VERSION ""

NS_ :

BS_:

BU_: ETH

BO_ 1520 USM_alertLog: 8 Vector__XXX
 SG_ USM_alertID M : 0|8@1+ (1,0) [0|0] "" Vector__XXX
 SG_ USM_alertState : 15|1@1+ (1,0) [0|0] "" Vector__XXX
 SG_ USM_a000_alertDataW0 m0 : 16|16@1+ (1,0) [0|0] "" Vector__XXX
 SG_ USM_a001_InternalWatchdog m1 : 16|1@1+ (1,0) [0|0] "" Vector__XXX
 SG_ USM_a002_CPUUndervoltage m2 : 16|1@1+ (1,0) [0|0] "" Vector__XXX
 SG_ USM_a003_AssertID m3 : 16|16@1+ (1,0) [0|0] "" Vector__XXX
 SG_ USM_a005_busID0 m5 : 16|4@1+ (1,0) [0|0] "" Vector__XXX
 SG_ USM_a006_busID m6 : 16|4@1+ (1,0) [0|0] "" Vector__XXX
 SG_ USM_a012_ClockError m12 : 16|1@1+ (1,0) [0|0] "" Vector__XXX
 SG_ USM_a013_LogQueueFull m13 : 16|1@1+ (1,0) [0|0] "" Vector__XXX
 SG_ USM_a015_NVMMMemOverflow m15 : 16|1@1+ (1,0) [0|0] "" Vector__XXX
 SG_ USM_a016_NVMMRecordID m16 : 16|16@1+ (1,0) [0|0] "" Vector__XXX
 SG_ USM_a021_Task1msLate m21 : 16|1@1+ (1,0) [0|0] "" Vector__XXX
 SG_ USM_a022_TaskInitErrorCount m22 : 16|8@1+ (1,0) [0|0] "" Vector__XXX
 SG_ USM_a030_logId m30 : 16|4@1+ (1,0) [0|0] "" Vector__XXX
 SG_ USM_a031_uds_bytes_0 m31 : 16|8@1+ (1,0) [0|0] "" Vector__XXX
 SG_ USM_a041_CPULoadTotal m41 : 16|8@1+ (1,0) [0|0] "" Vector__XXX
 SG_ USM_a042_Usage1msTask m42 : 16|8@1+ (1,0) [0|0] "" Vector__XXX
 SG_ USM_a043_CallTrace0 m43 : 16|24@1+ (1,0) [0|0] "" Vector__XXX
 SG_ USM_a044_CallTrace0 m44 : 16|24@1+ (1,0) [0|0] "" Vector__XXX
 SG_ USM_a045_CallTrace0 m45 : 16|24@1+ (1,0) [0|0] "" Vector__XXX
 SG_ USM_a046_CallTrace0 m46 : 16|24@1+ (1,0) [0|0] "" Vector__XXX
 SG_ USM_a057_VEH_cpControl m57 : 16|1@1+ (1,0) [0|0] "" Vector__XXX
 SG_ USM_a058_voltageDrop m58 : 16|12@1+ (0.005443676098,0) [0|0] "" Vector__XXX
 SG_ USM_a059_voltageDrop m59 : 16|12@1+ (0.005443676098,0) [0|0] "" Vector__XXX
 SG_ USM_a060_lockoutDisabled m60 : 16|1@1+ (1,0) [0|0] "" Vector__XXX
 SG_ USM_a063_switchChannel m63 : 16|8@1+ (1,0) [0|0] "" Vector__XXX
 SG_ USM_a064_busBitField m64 : 16|8@1+ (1,0) [0|0] "" Vector__XXX
 SG_ USM_a082_RIPC_epbPrivateState m82 : 16|1@1+ (1,0) [0|0] "" Vector__XXX
 SG_ USM_a083_LIPC_epbPrivateState m83 : 16|1@1+ (1,0) [0|0] "" Vector__XXX
 SG_ USM_a084_CH_StatusC m84 : 16|1@1+ (1,0) [0|0] "" Vector__XXX
 SG_ USM_a085_PARTY_buttonStatus m85 : 16|1@1+ (1,0) [0|0] "" Vector__XXX
 SG_ USM_a086_VEH_LVBMS_statusHigh m86 : 16|1@1+ (1,0) [0|0] "" Vector__XXX
 SG_ USM_a087_VEH_temperature m87 : 16|1@1+ (1,0) [0|0] "" Vector__XXX
 SG_ USM_a088_VEH_temperature m88 : 16|1@1+ (1,0) [0|0] "" Vector__XXX
 SG_ USM_a089_PARTY_party1 m89 : 16|1@1+ (1,0) [0|0] "" Vector__XXX
 SG_ USM_a090_VEH_chNm m90 : 16|1@1+ (1,0) [0|0] "" Vector__XXX
 SG_ USM_a091_VEH_faultsAndExtras m91 : 16|1@1+ (1,0) [0|0] "" Vector__XXX
 SG_ USM_a092_VEH_restraintStatus m92 : 16|1@1+ (1,0) [0|0] "" Vector__XXX
 SG_ USM_a093_VEH_restraintStatus m93 : 16|1@1+ (1,0) [0|0] "" Vector__XXX
 SG_ USM_a094_VEH_sysStatus m94 : 16|1@1+ (1,0) [0|0] "" Vector__XXX
 SG_ USM_a095_PT_ptNm m95 : 16|1@1+ (1,0) [0|0] "" Vector__XXX
 SG_ USM_a096_VEH_status m96 : 16|1@1+ (1,0) [0|0] "" Vector__XXX
 SG_ USM_a097_VEH_HVStatus m97 : 16|1@1+ (1,0) [0|0] "" Vector__XXX
 SG_ USM_a098_CH_torque m98 : 16|1@1+ (1,0) [0|0] "" Vector__XXX
 SG_ USM_a099_VEH_oocStatus m99 : 16|1@1+ (1,0) [0|0] "" Vector__XXX
 SG_ USM_a100_VEH m100 : 16|1@1+ (1,0) [0|0] "" Vector__XXX
 SG_ USM_a101_VEH_state m101 : 16|1@1+ (1,0) [0|0] "" Vector__XXX
 SG_ USM_a102_VEH_faultsAndExtras m102 : 16|1@1+ (1,0) [0|0] "" Vector__XXX
 SG_ USM_a103_VEH_hvsNm m103 : 16|1@1+ (1,0) [0|0] "" Vector__XXX
 SG_ USM_a104_VEH_chNm m104 : 16|1@1+ (1,0) [0|0] "" Vector__XXX
 SG_ USM_a105_VEH_states m105 : 16|1@1+ (1,0) [0|0] "" Vector__XXX
 SG_ USM_a106_VEH_dcdcStatus m106 : 16|1@1+ (1,0) [0|0] "" Vector__XXX
 SG_ USM_a107_VEH_hvsNm m107 : 16|1@1+ (1,0) [0|0] "" Vector__XXX
 SG_ USM_a108_VEH_hvStatus m108 : 16|1@1+ (1,0) [0|0] "" Vector__XXX
 SG_ USM_a109_PARTY_status m109 : 16|1@1+ (1,0) [0|0] "" Vector__XXX
 SG_ USM_a110_VEH_carState m110 : 16|1@1+ (1,0) [0|0] "" Vector__XXX
 SG_ USM_a111_VEH_internalStatus m111 : 16|1@1+ (1,0) [0|0] "" Vector__XXX
 SG_ USM_a112_VEH_internalStatus m112 : 16|1@1+ (1,0) [0|0] "" Vector__XXX
 SG_ USM_a113_VEH_ethNm m113 : 16|1@1+ (1,0) [0|0] "" Vector__XXX
 SG_ USM_a114_PARTY_status m114 : 16|1@1+ (1,0) [0|0] "" Vector__XXX
 SG_ USM_a115_VEH_vehNm m115 : 16|1@1+ (1,0) [0|0] "" Vector__XXX
 SG_ USM_a116_PARTY_epbmStatus m116 : 16|1@1+ (1,0) [0|0] "" Vector__XXX
 SG_ USM_a117_BDY_epbmStatus m117 : 16|1@1+ (1,0) [0|0] "" Vector__XXX
 SG_ USM_a118_VEH_vehNm m118 : 16|1@1+ (1,0) [0|0] "" Vector__XXX
 SG_ USM_a119_VEH_steerAngle m119 : 16|1@1+ (1,0) [0|0] "" Vector__XXX
 SG_ USM_a120_PARTY_chassisCntl m120 : 16|1@1+ (1,0) [0|0] "" Vector__XXX
 SG_ USM_a131_inDrivePowerState m131 : 16|1@1+ (1,0) [0|0] "" Vector__XXX
 SG_ USM_a132_inDrivePowerState m132 : 16|1@1+ (1,0) [0|0] "" Vector__XXX
 SG_ USM_a133_inDrivePowerState m133 : 16|1@1+ (1,0) [0|0] "" Vector__XXX
 SG_ USM_a134_inDrivePowerState m134 : 16|1@1+ (1,0) [0|0] "" Vector__XXX
 SG_ USM_a135_inDrivePowerState m135 : 16|1@1+ (1,0) [0|0] "" Vector__XXX
 SG_ USM_a136_inDrivePowerState m136 : 16|1@1+ (1,0) [0|0] "" Vector__XXX
 SG_ USM_a137_inDrivePowerState m137 : 16|1@1+ (1,0) [0|0] "" Vector__XXX
 SG_ USM_a138_inDrivePowerState m138 : 16|1@1+ (1,0) [0|0] "" Vector__XXX
 SG_ USM_a139_inDrivePowerState m139 : 16|1@1+ (1,0) [0|0] "" Vector__XXX
 SG_ USM_a140_inDrivePowerState m140 : 16|1@1+ (1,0) [0|0] "" Vector__XXX
 SG_ USM_a141_inDrivePowerState m141 : 16|1@1+ (1,0) [0|0] "" Vector__XXX
 SG_ USM_a142_inDrivePowerState m142 : 16|1@1+ (1,0) [0|0] "" Vector__XXX
 SG_ USM_a143_inDrivePowerState m143 : 16|1@1+ (1,0) [0|0] "" Vector__XXX
 SG_ USM_a144_inDrivePowerState m144 : 16|1@1+ (1,0) [0|0] "" Vector__XXX
 SG_ USM_a145_inDrivePowerState m145 : 16|1@1+ (1,0) [0|0] "" Vector__XXX
 SG_ USM_a146_inDrivePowerState m146 : 16|1@1+ (1,0) [0|0] "" Vector__XXX
 SG_ USM_a147_inDrivePowerState m147 : 16|1@1+ (1,0) [0|0] "" Vector__XXX
 SG_ USM_a148_inDrivePowerState m148 : 16|1@1+ (1,0) [0|0] "" Vector__XXX
 SG_ USM_a149_inDrivePowerState m149 : 16|1@1+ (1,0) [0|0] "" Vector__XXX
 SG_ USM_a150_inDrivePowerState m150 : 16|1@1+ (1,0) [0|0] "" Vector__XXX
 SG_ USM_a151_inDrivePowerState m151 : 16|1@1+ (1,0) [0|0] "" Vector__XXX
 SG_ USM_a152_inDrivePowerState m152 : 16|1@1+ (1,0) [0|0] "" Vector__XXX
 SG_ USM_a153_inDrivePowerState m153 : 16|1@1+ (1,0) [0|0] "" Vector__XXX
 SG_ USM_a154_inDrivePowerState m154 : 16|1@1+ (1,0) [0|0] "" Vector__XXX
 SG_ USM_a155_temperature m155 : 16|8@1- (1,33) [0|0] "" Vector__XXX
 SG_ USM_a156_temperature m156 : 16|8@1- (1,33) [0|0] "" Vector__XXX
 SG_ USM_a157_temperature m157 : 16|8@1- (1,33) [0|0] "" Vector__XXX
 SG_ USM_a158_temperature m158 : 16|8@1- (1,33) [0|0] "" Vector__XXX
 SG_ USM_a159_temperature m159 : 16|8@1- (1,33) [0|0] "" Vector__XXX
 SG_ USM_a160_temperature m160 : 16|8@1- (1,33) [0|0] "" Vector__XXX
 SG_ USM_a161_temperature m161 : 16|8@1- (1,33) [0|0] "" Vector__XXX
 SG_ USM_a162_temperature m162 : 16|8@1- (1,33) [0|0] "" Vector__XXX
 SG_ USM_a163_temperature m163 : 16|8@1- (1,33) [0|0] "" Vector__XXX
 SG_ USM_a164_temperature m164 : 16|8@1- (1,33) [0|0] "" Vector__XXX
 SG_ USM_a165_temperature m165 : 16|8@1- (1,33) [0|0] "" Vector__XXX
 SG_ USM_a166_temperature m166 : 16|8@1- (1,33) [0|0] "" Vector__XXX
 SG_ USM_a177_rtmCompensated m177 : 16|8@1+ (8,0) [0|0] "" Vector__XXX
 SG_ USM_a178_rtmCompensated m178 : 16|8@1+ (8,0) [0|0] "" Vector__XXX
 SG_ USM_a179_rtmCompensated m179 : 16|8@1+ (8,0) [0|0] "" Vector__XXX
 SG_ USM_a180_rtmCompensated m180 : 16|8@1+ (8,0) [0|0] "" Vector__XXX
 SG_ USM_a181_rtmCompensated m181 : 16|8@1+ (8,0) [0|0] "" Vector__XXX
 SG_ USM_a182_rtmCompensated m182 : 16|8@1+ (8,0) [0|0] "" Vector__XXX
 SG_ USM_a183_rtmCompensated m183 : 16|8@1+ (8,0) [0|0] "" Vector__XXX
 SG_ USM_a184_rtmCompensated m184 : 16|8@1+ (8,0) [0|0] "" Vector__XXX
 SG_ USM_a185_rtmCompensated m185 : 16|8@1+ (8,0) [0|0] "" Vector__XXX
 SG_ USM_a186_rtmCompensated m186 : 16|8@1+ (8,0) [0|0] "" Vector__XXX
 SG_ USM_a187_rtmCompensated m187 : 16|8@1+ (8,0) [0|0] "" Vector__XXX
 SG_ USM_a188_rtmCompensated m188 : 16|8@1+ (8,0) [0|0] "" Vector__XXX
 SG_ USM_a201_channel m201 : 16|2@1+ (1,0) [0|0] "" Vector__XXX
 SG_ USM_a202_channel m202 : 16|4@1+ (1,0) [0|0] "" Vector__XXX
 SG_ USM_a203_sdiRawDistData m203 : 16|9@1+ (1,0) [0|0] "" Vector__XXX
 SG_ USM_a204_sdiRawDistData m204 : 16|9@1+ (1,0) [0|0] "" Vector__XXX
 SG_ USM_a205_sdiRawDistData m205 : 16|9@1+ (1,0) [0|0] "" Vector__XXX
 SG_ USM_a206_sdiRawDistData m206 : 16|9@1+ (1,0) [0|0] "" Vector__XXX
 SG_ USM_a207_sdiRawDistData m207 : 16|9@1+ (1,0) [0|0] "" Vector__XXX
 SG_ USM_a208_sdiRawDistData m208 : 16|9@1+ (1,0) [0|0] "" Vector__XXX
 SG_ USM_a209_sdiRawDistData m209 : 16|9@1+ (1,0) [0|0] "" Vector__XXX
 SG_ USM_a210_sdiRawDistData m210 : 16|9@1+ (1,0) [0|0] "" Vector__XXX
 SG_ USM_a211_sdiRawDistData m211 : 16|9@1+ (1,0) [0|0] "" Vector__XXX
 SG_ USM_a212_sdiRawDistData m212 : 16|9@1+ (1,0) [0|0] "" Vector__XXX
 SG_ USM_a213_sdiRawDistData m213 : 16|9@1+ (1,0) [0|0] "" Vector__XXX
 SG_ USM_a214_sdiRawDistData m214 : 16|9@1+ (1,0) [0|0] "" Vector__XXX
 SG_ USM_a227_reset m227 : 16|1@1+ (1,0) [0|0] "" Vector__XXX
 SG_ USM_a228_reset m228 : 16|1@1+ (1,0) [0|0] "" Vector__XXX
 SG_ USM_a229_reset m229 : 16|1@1+ (1,0) [0|0] "" Vector__XXX
 SG_ USM_a230_reset m230 : 16|1@1+ (1,0) [0|0] "" Vector__XXX
 SG_ USM_a231_reset m231 : 16|1@1+ (1,0) [0|0] "" Vector__XXX
 SG_ USM_a232_reset m232 : 16|1@1+ (1,0) [0|0] "" Vector__XXX
 SG_ USM_a233_reset m233 : 16|1@1+ (1,0) [0|0] "" Vector__XXX
 SG_ USM_a234_reset m234 : 16|1@1+ (1,0) [0|0] "" Vector__XXX
 SG_ USM_a235_reset m235 : 16|1@1+ (1,0) [0|0] "" Vector__XXX
 SG_ USM_a236_reset m236 : 16|1@1+ (1,0) [0|0] "" Vector__XXX
 SG_ USM_a237_reset m237 : 16|1@1+ (1,0) [0|0] "" Vector__XXX
 SG_ USM_a238_reset m238 : 16|1@1+ (1,0) [0|0] "" Vector__XXX
 SG_ USM_a240_reset m240 : 16|1@1+ (1,0) [0|0] "" Vector__XXX
 SG_ USM_a241_reset m241 : 16|1@1+ (1,0) [0|0] "" Vector__XXX
 SG_ USM_a242_reset m242 : 16|1@1+ (1,0) [0|0] "" Vector__XXX
 SG_ USM_a243_reset m243 : 16|1@1+ (1,0) [0|0] "" Vector__XXX
 SG_ USM_a244_reset m244 : 16|1@1+ (1,0) [0|0] "" Vector__XXX
 SG_ USM_a245_reset m245 : 16|1@1+ (1,0) [0|0] "" Vector__XXX
 SG_ USM_a246_reset m246 : 16|1@1+ (1,0) [0|0] "" Vector__XXX
 SG_ USM_a247_reset m247 : 16|1@1+ (1,0) [0|0] "" Vector__XXX
 SG_ USM_a248_reset m248 : 16|1@1+ (1,0) [0|0] "" Vector__XXX
 SG_ USM_a249_reset m249 : 16|1@1+ (1,0) [0|0] "" Vector__XXX
 SG_ USM_a250_reset m250 : 16|1@1+ (1,0) [0|0] "" Vector__XXX
 SG_ USM_a251_reset m251 : 16|1@1+ (1,0) [0|0] "" Vector__XXX
 SG_ USM_a252_inDrivePowerState m252 : 16|1@1+ (1,0) [0|0] "" Vector__XXX
 SG_ USM_a253_inDrivePowerState m253 : 16|1@1+ (1,0) [0|0] "" Vector__XXX
 SG_ USM_a254_frontSensorsCurrent m254 : 16|10@1+ (0.005865102639296188,0) [0|0] "" Vector__XXX
 SG_ USM_a255_rearSensorsCurrent m255 : 16|10@1+ (0.005865102639296188,0) [0|0] "" Vector__XXX
 SG_ USM_a002_PowerOnReset m2 : 17|1@1+ (1,0) [0|0] "" Vector__XXX
 SG_ USM_a012_FlashError m12 : 17|1@1+ (1,0) [0|0] "" Vector__XXX
 SG_ USM_a013_ClearQueueFull m13 : 17|1@1+ (1,0) [0|0] "" Vector__XXX
 SG_ USM_a015_NVMMFilesystemError m15 : 17|1@1+ (1,0) [0|0] "" Vector__XXX
 SG_ USM_a021_Task1msStarved m21 : 17|1@1+ (1,0) [0|0] "" Vector__XXX
 SG_ USM_a060_resetUnlocked m60 : 17|1@1+ (1,0) [0|0] "" Vector__XXX
 SG_ USM_a082_RIPC_remoteHSD m82 : 17|1@1+ (1,0) [0|0] "" Vector__XXX
 SG_ USM_a083_LIPC_remoteHSD m83 : 17|1@1+ (1,0) [0|0] "" Vector__XXX
 SG_ USM_a086_VEH_LVBMS_statusLow m86 : 17|1@1+ (1,0) [0|0] "" Vector__XXX
 SG_ USM_a087_VEH_thermalControl m87 : 17|1@1+ (1,0) [0|0] "" Vector__XXX
 SG_ USM_a088_VEH_thermalControl m88 : 17|1@1+ (1,0) [0|0] "" Vector__XXX
 SG_ USM_a089_PARTY_status m89 : 17|1@1+ (1,0) [0|0] "" Vector__XXX
 SG_ USM_a090_VEH_state m90 : 17|1@1+ (1,0) [0|0] "" Vector__XXX
 SG_ USM_a091_VEH_info m91 : 17|1@1+ (1,0) [0|0] "" Vector__XXX
 SG_ USM_a092_VEH_switchStatus m92 : 17|1@1+ (1,0) [0|0] "" Vector__XXX
 SG_ USM_a093_VEH_switchStatus m93 : 17|1@1+ (1,0) [0|0] "" Vector__XXX
 SG_ USM_a094_PARTY_sysStatus m94 : 17|1@1+ (1,0) [0|0] "" Vector__XXX
 SG_ USM_a095_PT_status m95 : 17|1@1+ (1,0) [0|0] "" Vector__XXX
 SG_ USM_a096_CH_status m96 : 17|1@1+ (1,0) [0|0] "" Vector__XXX
 SG_ USM_a097_VEH_state m97 : 17|1@1+ (1,0) [0|0] "" Vector__XXX
 SG_ USM_a098_VEH_hvStatus m98 : 17|1@1+ (1,0) [0|0] "" Vector__XXX
 SG_ USM_a100_PARTY m100 : 17|1@1+ (1,0) [0|0] "" Vector__XXX
 SG_ USM_a101_PARTY_locState m101 : 17|1@1+ (1,0) [0|0] "" Vector__XXX
 SG_ USM_a102_VEH_feedbackStatus m102 : 17|1@1+ (1,0) [0|0] "" Vector__XXX
 SG_ USM_a103_VEH_vehNm m103 : 17|1@1+ (1,0) [0|0] "" Vector__XXX
 SG_ USM_a104_VEH_bodyControls m104 : 17|1@1+ (1,0) [0|0] "" Vector__XXX
 SG_ USM_a105_VEH_chNm m105 : 17|1@1+ (1,0) [0|0] "" Vector__XXX
 SG_ USM_a106_VEH_thermalControl m106 : 17|1@1+ (1,0) [0|0] "" Vector__XXX
 SG_ USM_a107_VEH_vehNm m107 : 17|1@1+ (1,0) [0|0] "" Vector__XXX
 SG_ USM_a108_VEH_temperature m108 : 17|1@1+ (1,0) [0|0] "" Vector__XXX
 SG_ USM_a109_PARTY_inertial2 m109 : 17|1@1+ (1,0) [0|0] "" Vector__XXX
 SG_ USM_a110_VEH_carConfig m110 : 17|1@1+ (1,0) [0|0] "" Vector__XXX
 SG_ USM_a111_VEH_status m111 : 17|1@1+ (1,0) [0|0] "" Vector__XXX
 SG_ USM_a112_VEH_status m112 : 17|1@1+ (1,0) [0|0] "" Vector__XXX
 SG_ USM_a113_VEH_hvacRequest m113 : 17|1@1+ (1,0) [0|0] "" Vector__XXX
 SG_ USM_a114_PARTY_wheelSpeeds m114 : 17|1@1+ (1,0) [0|0] "" Vector__XXX
 SG_ USM_a115_VEH_authentication m115 : 17|1@1+ (1,0) [0|0] "" Vector__XXX
 SG_ USM_a116_VEH_vehNm m116 : 17|1@1+ (1,0) [0|0] "" Vector__XXX
 SG_ USM_a117_BDY_restraintStatus m117 : 17|1@1+ (1,0) [0|0] "" Vector__XXX
 SG_ USM_a118_VEH_lighting m118 : 17|1@1+ (1,0) [0|0] "" Vector__XXX
 SG_ USM_a119_VEH_leftStalk m119 : 17|1@1+ (1,0) [0|0] "" Vector__XXX
 SG_ USM_a120_VEH_systemStatus m120 : 17|1@1+ (1,0) [0|0] "" Vector__XXX
 SG_ USM_a227_otpCrcError m227 : 17|1@1+ (1,0) [0|0] "" Vector__XXX
 SG_ USM_a228_otpCrcError m228 : 17|1@1+ (1,0) [0|0] "" Vector__XXX
 SG_ USM_a229_otpCrcError m229 : 17|1@1+ (1,0) [0|0] "" Vector__XXX
 SG_ USM_a230_otpCrcError m230 : 17|1@1+ (1,0) [0|0] "" Vector__XXX
 SG_ USM_a231_otpCrcError m231 : 17|1@1+ (1,0) [0|0] "" Vector__XXX
 SG_ USM_a232_otpCrcError m232 : 17|1@1+ (1,0) [0|0] "" Vector__XXX
 SG_ USM_a233_otpCrcError m233 : 17|1@1+ (1,0) [0|0] "" Vector__XXX
 SG_ USM_a234_otpCrcError m234 : 17|1@1+ (1,0) [0|0] "" Vector__XXX
 SG_ USM_a235_otpCrcError m235 : 17|1@1+ (1,0) [0|0] "" Vector__XXX
 SG_ USM_a236_otpCrcError m236 : 17|1@1+ (1,0) [0|0] "" Vector__XXX
 SG_ USM_a237_otpCrcError m237 : 17|1@1+ (1,0) [0|0] "" Vector__XXX
 SG_ USM_a238_otpCrcError m238 : 17|1@1+ (1,0) [0|0] "" Vector__XXX
 SG_ USM_a240_otpCrcError m240 : 17|1@1+ (1,0) [0|0] "" Vector__XXX
 SG_ USM_a241_otpCrcError m241 : 17|1@1+ (1,0) [0|0] "" Vector__XXX
 SG_ USM_a242_otpCrcError m242 : 17|1@1+ (1,0) [0|0] "" Vector__XXX
 SG_ USM_a243_otpCrcError m243 : 17|1@1+ (1,0) [0|0] "" Vector__XXX
 SG_ USM_a244_otpCrcError m244 : 17|1@1+ (1,0) [0|0] "" Vector__XXX
 SG_ USM_a245_otpCrcError m245 : 17|1@1+ (1,0) [0|0] "" Vector__XXX
 SG_ USM_a246_otpCrcError m246 : 17|1@1+ (1,0) [0|0] "" Vector__XXX
 SG_ USM_a247_otpCrcError m247 : 17|1@1+ (1,0) [0|0] "" Vector__XXX
 SG_ USM_a248_otpCrcError m248 : 17|1@1+ (1,0) [0|0] "" Vector__XXX
 SG_ USM_a249_otpCrcError m249 : 17|1@1+ (1,0) [0|0] "" Vector__XXX
 SG_ USM_a250_otpCrcError m250 : 17|1@1+ (1,0) [0|0] "" Vector__XXX
 SG_ USM_a251_otpCrcError m251 : 17|1@1+ (1,0) [0|0] "" Vector__XXX
 SG_ USM_a012_SoftwareReset m12 : 18|1@1+ (1,0) [0|0] "" Vector__XXX
 SG_ USM_a015_NVMMRecordIDError m15 : 18|1@1+ (1,0) [0|0] "" Vector__XXX
 SG_ USM_a021_Task1msMissed m21 : 18|1@1+ (1,0) [0|0] "" Vector__XXX
 SG_ USM_a082_RIPC_railStatus m82 : 18|1@1+ (1,0) [0|0] "" Vector__XXX
 SG_ USM_a083_LIPC_railStatus m83 : 18|1@1+ (1,0) [0|0] "" Vector__XXX
 SG_ USM_a086_VEH_status m86 : 18|1@1+ (1,0) [0|0] "" Vector__XXX
 SG_ USM_a087_VEH_torque m87 : 18|1@1+ (1,0) [0|0] "" Vector__XXX
 SG_ USM_a088_VEH_torque m88 : 18|1@1+ (1,0) [0|0] "" Vector__XXX
 SG_ USM_a089_VEH_status m89 : 18|1@1+ (1,0) [0|0] "" Vector__XXX
 SG_ USM_a090_PARTY_eacMonitor m90 : 18|1@1+ (1,0) [0|0] "" Vector__XXX
 SG_ USM_a091_VEH_state m91 : 18|1@1+ (1,0) [0|0] "" Vector__XXX
 SG_ USM_a092_VEH_seatStatus2 m92 : 18|1@1+ (1,0) [0|0] "" Vector__XXX
 SG_ USM_a093_VEH_seatStatus2 m93 : 18|1@1+ (1,0) [0|0] "" Vector__XXX
 SG_ USM_a098_VEH_status m98 : 18|1@1+ (1,0) [0|0] "" Vector__XXX
 SG_ USM_a100_PT m100 : 18|1@1+ (1,0) [0|0] "" Vector__XXX
 SG_ USM_a101_LIPC_externalWatchdogHeartBeat m101 : 18|1@1+ (1,0) [0|0] "" Vector__XXX
 SG_ USM_a102_VEH_sensorStatus m102 : 18|1@1+ (1,0) [0|0] "" Vector__XXX
 SG_ USM_a103_VEH_status m103 : 18|1@1+ (1,0) [0|0] "" Vector__XXX
 SG_ USM_a104_VEH_bodyControls3 m104 : 18|1@1+ (1,0) [0|0] "" Vector__XXX
 SG_ USM_a105_VEH_dampingStates m105 : 18|1@1+ (1,0) [0|0] "" Vector__XXX
 SG_ USM_a106_VEH_dcdcRailStatus m106 : 18|1@1+ (1,0) [0|0] "" Vector__XXX
 SG_ USM_a107_VEH_status m107 : 18|1@1+ (1,0) [0|0] "" Vector__XXX
 SG_ USM_a108_VEH_thermalControl m108 : 18|1@1+ (1,0) [0|0] "" Vector__XXX
 SG_ USM_a109_PARTY_nearDeploy m109 : 18|1@1+ (1,0) [0|0] "" Vector__XXX
 SG_ USM_a110_VEH_time m110 : 18|1@1+ (1,0) [0|0] "" Vector__XXX
 SG_ USM_a111_VEH_vehNm m111 : 18|1@1+ (1,0) [0|0] "" Vector__XXX
 SG_ USM_a112_VEH_vehNm m112 : 18|1@1+ (1,0) [0|0] "" Vector__XXX
 SG_ USM_a113_VEH_chargeRequest m113 : 18|1@1+ (1,0) [0|0] "" Vector__XXX
 SG_ USM_a114_VEH_wheelSpeeds m114 : 18|1@1+ (1,0) [0|0] "" Vector__XXX
 SG_ USM_a115_VEH_BLEResetRequest m115 : 18|1@1+ (1,0) [0|0] "" Vector__XXX
 SG_ USM_a116_VEH_hvacRequest m116 : 18|1@1+ (1,0) [0|0] "" Vector__XXX
 SG_ USM_a117_VEH_prndStatus m117 : 18|1@1+ (1,0) [0|0] "" Vector__XXX
 SG_ USM_a118_VEH_sensors m118 : 18|1@1+ (1,0) [0|0] "" Vector__XXX
 SG_ USM_a119_VEH_rightStalk m119 : 18|1@1+ (1,0) [0|0] "" Vector__XXX
 SG_ USM_a120_CH_chassisCntl m120 : 18|1@1+ (1,0) [0|0] "" Vector__XXX
 SG_ USM_a201_OT m201 : 18|1@1+ (1,0) [0|0] "" Vector__XXX
 SG_ USM_a227_trimRegParityErr m227 : 18|1@1+ (1,0) [0|0] "" Vector__XXX
 SG_ USM_a228_trimRegParityErr m228 : 18|1@1+ (1,0) [0|0] "" Vector__XXX
 SG_ USM_a229_trimRegParityErr m229 : 18|1@1+ (1,0) [0|0] "" Vector__XXX
 SG_ USM_a230_trimRegParityErr m230 : 18|1@1+ (1,0) [0|0] "" Vector__XXX
 SG_ USM_a231_trimRegParityErr m231 : 18|1@1+ (1,0) [0|0] "" Vector__XXX
 SG_ USM_a232_trimRegParityErr m232 : 18|1@1+ (1,0) [0|0] "" Vector__XXX
 SG_ USM_a233_trimRegParityErr m233 : 18|1@1+ (1,0) [0|0] "" Vector__XXX
 SG_ USM_a234_trimRegParityErr m234 : 18|1@1+ (1,0) [0|0] "" Vector__XXX
 SG_ USM_a235_trimRegParityErr m235 : 18|1@1+ (1,0) [0|0] "" Vector__XXX
 SG_ USM_a236_trimRegParityErr m236 : 18|1@1+ (1,0) [0|0] "" Vector__XXX
 SG_ USM_a237_trimRegParityErr m237 : 18|1@1+ (1,0) [0|0] "" Vector__XXX
 SG_ USM_a238_trimRegParityErr m238 : 18|1@1+ (1,0) [0|0] "" Vector__XXX
 SG_ USM_a240_trimRegParityErr m240 : 18|1@1+ (1,0) [0|0] "" Vector__XXX
 SG_ USM_a241_trimRegParityErr m241 : 18|1@1+ (1,0) [0|0] "" Vector__XXX
 SG_ USM_a242_trimRegParityErr m242 : 18|1@1+ (1,0) [0|0] "" Vector__XXX
 SG_ USM_a243_trimRegParityErr m243 : 18|1@1+ (1,0) [0|0] "" Vector__XXX
 SG_ USM_a244_trimRegParityErr m244 : 18|1@1+ (1,0) [0|0] "" Vector__XXX
 SG_ USM_a245_trimRegParityErr m245 : 18|1@1+ (1,0) [0|0] "" Vector__XXX
 SG_ USM_a246_trimRegParityErr m246 : 18|1@1+ (1,0) [0|0] "" Vector__XXX
 SG_ USM_a247_trimRegParityErr m247 : 18|1@1+ (1,0) [0|0] "" Vector__XXX
 SG_ USM_a248_trimRegParityErr m248 : 18|1@1+ (1,0) [0|0] "" Vector__XXX
 SG_ USM_a249_trimRegParityErr m249 : 18|1@1+ (1,0) [0|0] "" Vector__XXX
 SG_ USM_a250_trimRegParityErr m250 : 18|1@1+ (1,0) [0|0] "" Vector__XXX
 SG_ USM_a251_trimRegParityErr m251 : 18|1@1+ (1,0) [0|0] "" Vector__XXX
 SG_ USM_a012_CheckstopReset m12 : 19|1@1+ (1,0) [0|0] "" Vector__XXX
 SG_ USM_a021_Task10msLate m21 : 19|1@1+ (1,0) [0|0] "" Vector__XXX
 SG_ USM_a082_RIPC_remoteMux m82 : 19|1@1+ (1,0) [0|0] "" Vector__XXX
 SG_ USM_a083_LIPC_HSDFaults m83 : 19|1@1+ (1,0) [0|0] "" Vector__XXX
 SG_ USM_a086_VEH_12VBatteryStatus m86 : 19|1@1+ (1,0) [0|0] "" Vector__XXX
 SG_ USM_a087_VEH_status m87 : 19|1@1+ (1,0) [0|0] "" Vector__XXX
 SG_ USM_a088_VEH_status m88 : 19|1@1+ (1,0) [0|0] "" Vector__XXX
 SG_ USM_a089_BDY_party1 m89 : 19|1@1+ (1,0) [0|0] "" Vector__XXX
 SG_ USM_a090_CH_eacMonitor m90 : 19|1@1+ (1,0) [0|0] "" Vector__XXX
 SG_ USM_a092_VEH_vehNm m92 : 19|1@1+ (1,0) [0|0] "" Vector__XXX
 SG_ USM_a093_VEH_vehNm m93 : 19|1@1+ (1,0) [0|0] "" Vector__XXX
 SG_ USM_a098_VEH_thermalControl m98 : 19|1@1+ (1,0) [0|0] "" Vector__XXX
 SG_ USM_a100_CH m100 : 19|1@1+ (1,0) [0|0] "" Vector__XXX
 SG_ USM_a101_VEH_locState m101 : 19|1@1+ (1,0) [0|0] "" Vector__XXX
 SG_ USM_a102_VEH_rods m102 : 19|1@1+ (1,0) [0|0] "" Vector__XXX
 SG_ USM_a103_PT_ptNm m103 : 19|1@1+ (1,0) [0|0] "" Vector__XXX
 SG_ USM_a104_BDY_bodyControls3 m104 : 19|1@1+ (1,0) [0|0] "" Vector__XXX
 SG_ USM_a106_CH_dcdcRailStatus m106 : 19|1@1+ (1,0) [0|0] "" Vector__XXX
 SG_ USM_a107_VEH_thermalStatus m107 : 19|1@1+ (1,0) [0|0] "" Vector__XXX
 SG_ USM_a108_VEH_torque m108 : 19|1@1+ (1,0) [0|0] "" Vector__XXX
 SG_ USM_a109_PARTY_collision m109 : 19|1@1+ (1,0) [0|0] "" Vector__XXX
 SG_ USM_a110_VEH_updateStatus m110 : 19|1@1+ (1,0) [0|0] "" Vector__XXX
 SG_ USM_a111_RIPC_LVPowerState m111 : 19|1@1+ (1,0) [0|0] "" Vector__XXX
 SG_ USM_a112_LIPC_LVPowerState m112 : 19|1@1+ (1,0) [0|0] "" Vector__XXX
 SG_ USM_a113_VEH_vehicleControl m113 : 19|1@1+ (1,0) [0|0] "" Vector__XXX
 SG_ USM_a114_CH_wheelSpeeds m114 : 19|1@1+ (1,0) [0|0] "" Vector__XXX
 SG_ USM_a115_VEH_requests m115 : 19|1@1+ (1,0) [0|0] "" Vector__XXX
 SG_ USM_a116_VEH_hvacStatus m116 : 19|1@1+ (1,0) [0|0] "" Vector__XXX
 SG_ USM_a117_PARTY_epbmStatus m117 : 19|1@1+ (1,0) [0|0] "" Vector__XXX
 SG_ USM_a118_VEH_status m118 : 19|1@1+ (1,0) [0|0] "" Vector__XXX
 SG_ USM_a119_PARTY_rightStalk m119 : 19|1@1+ (1,0) [0|0] "" Vector__XXX
 SG_ USM_a120_PARTY_systemStatus m120 : 19|1@1+ (1,0) [0|0] "" Vector__XXX
 SG_ USM_a201_VCCUV_RFCB m201 : 19|1@1+ (1,0) [0|0] "" Vector__XXX
 SG_ USM_a227_sramParityErr m227 : 19|1@1+ (1,0) [0|0] "" Vector__XXX
 SG_ USM_a228_sramParityErr m228 : 19|1@1+ (1,0) [0|0] "" Vector__XXX
 SG_ USM_a229_sramParityErr m229 : 19|1@1+ (1,0) [0|0] "" Vector__XXX
 SG_ USM_a230_sramParityErr m230 : 19|1@1+ (1,0) [0|0] "" Vector__XXX
 SG_ USM_a231_sramParityErr m231 : 19|1@1+ (1,0) [0|0] "" Vector__XXX
 SG_ USM_a232_sramParityErr m232 : 19|1@1+ (1,0) [0|0] "" Vector__XXX
 SG_ USM_a233_sramParityErr m233 : 19|1@1+ (1,0) [0|0] "" Vector__XXX
 SG_ USM_a234_sramParityErr m234 : 19|1@1+ (1,0) [0|0] "" Vector__XXX
 SG_ USM_a235_sramParityErr m235 : 19|1@1+ (1,0) [0|0] "" Vector__XXX
 SG_ USM_a236_sramParityErr m236 : 19|1@1+ (1,0) [0|0] "" Vector__XXX
 SG_ USM_a237_sramParityErr m237 : 19|1@1+ (1,0) [0|0] "" Vector__XXX
 SG_ USM_a238_sramParityErr m238 : 19|1@1+ (1,0) [0|0] "" Vector__XXX
 SG_ USM_a240_sramParityErr m240 : 19|1@1+ (1,0) [0|0] "" Vector__XXX
 SG_ USM_a241_sramParityErr m241 : 19|1@1+ (1,0) [0|0] "" Vector__XXX
 SG_ USM_a242_sramParityErr m242 : 19|1@1+ (1,0) [0|0] "" Vector__XXX
 SG_ USM_a243_sramParityErr m243 : 19|1@1+ (1,0) [0|0] "" Vector__XXX
 SG_ USM_a244_sramParityErr m244 : 19|1@1+ (1,0) [0|0] "" Vector__XXX
 SG_ USM_a245_sramParityErr m245 : 19|1@1+ (1,0) [0|0] "" Vector__XXX
 SG_ USM_a246_sramParityErr m246 : 19|1@1+ (1,0) [0|0] "" Vector__XXX
 SG_ USM_a247_sramParityErr m247 : 19|1@1+ (1,0) [0|0] "" Vector__XXX
 SG_ USM_a248_sramParityErr m248 : 19|1@1+ (1,0) [0|0] "" Vector__XXX
 SG_ USM_a249_sramParityErr m249 : 19|1@1+ (1,0) [0|0] "" Vector__XXX
 SG_ USM_a250_sramParityErr m250 : 19|1@1+ (1,0) [0|0] "" Vector__XXX
 SG_ USM_a251_sramParityErr m251 : 19|1@1+ (1,0) [0|0] "" Vector__XXX
 SG_ USM_a005_faults0 m5 : 20|12@1+ (1,0) [0|0] "" Vector__XXX
 SG_ USM_a006_fault m6 : 20|4@1+ (1,0) [0|0] "" Vector__XXX
 SG_ USM_a012_DebugReset m12 : 20|1@1+ (1,0) [0|0] "" Vector__XXX
 SG_ USM_a021_Task10msStarved m21 : 20|1@1+ (1,0) [0|0] "" Vector__XXX
 SG_ USM_a086_VEH_LVPowerState m86 : 20|1@1+ (1,0) [0|0] "" Vector__XXX
 SG_ USM_a087_PARTY_torque m87 : 20|1@1+ (1,0) [0|0] "" Vector__XXX
 SG_ USM_a088_PARTY_torque m88 : 20|1@1+ (1,0) [0|0] "" Vector__XXX
 SG_ USM_a089_BDY_status m89 : 20|1@1+ (1,0) [0|0] "" Vector__XXX
 SG_ USM_a098_VEH_temperature m98 : 20|1@1+ (1,0) [0|0] "" Vector__XXX
 SG_ USM_a100_OBD m100 : 20|1@1+ (1,0) [0|0] "" Vector__XXX
 SG_ USM_a101_BDY_locState m101 : 20|1@1+ (1,0) [0|0] "" Vector__XXX
 SG_ USM_a103_PT_status m103 : 20|1@1+ (1,0) [0|0] "" Vector__XXX
 SG_ USM_a104_VEH_thermalStatus m104 : 20|1@1+ (1,0) [0|0] "" Vector__XXX
 SG_ USM_a106_CH_alertMatrix m106 : 20|1@1+ (1,0) [0|0] "" Vector__XXX
 SG_ USM_a107_VEH_bmbMinMax m107 : 20|1@1+ (1,0) [0|0] "" Vector__XXX
 SG_ USM_a108_VEH_status m108 : 20|1@1+ (1,0) [0|0] "" Vector__XXX
 SG_ USM_a109_VEH_status m109 : 20|1@1+ (1,0) [0|0] "" Vector__XXX
 SG_ USM_a110_VEH_vehNm m110 : 20|1@1+ (1,0) [0|0] "" Vector__XXX
 SG_ USM_a111_RIPC_epbPrivateState m111 : 20|1@1+ (1,0) [0|0] "" Vector__XXX
 SG_ USM_a112_LIPC_epbPrivateState m112 : 20|1@1+ (1,0) [0|0] "" Vector__XXX
 SG_ USM_a113_VEH_vehicleControl2 m113 : 20|1@1+ (1,0) [0|0] "" Vector__XXX
 SG_ USM_a114_PARTY_party3 m114 : 20|1@1+ (1,0) [0|0] "" Vector__XXX
 SG_ USM_a115_VEH_requests2 m115 : 20|1@1+ (1,0) [0|0] "" Vector__XXX
 SG_ USM_a116_VEH_LVPowerState m116 : 20|1@1+ (1,0) [0|0] "" Vector__XXX
 SG_ USM_a117_VEH_vehNm m117 : 20|1@1+ (1,0) [0|0] "" Vector__XXX
 SG_ USM_a118_VEH_okToUseHighPwr m118 : 20|1@1+ (1,0) [0|0] "" Vector__XXX
 SG_ USM_a119_CH_steerAngle m119 : 20|1@1+ (1,0) [0|0] "" Vector__XXX
 SG_ USM_a120_PARTY_torque m120 : 20|1@1+ (1,0) [0|0] "" Vector__XXX
 SG_ USM_a201_CLKREF_ERROR m201 : 20|1@1+ (1,0) [0|0] "" Vector__XXX
 SG_ USM_a202_EE m202 : 20|1@1+ (1,0) [0|0] "" Vector__XXX
 SG_ USM_a227_crcMismatchInOtp m227 : 20|1@1+ (1,0) [0|0] "" Vector__XXX
 SG_ USM_a228_crcMismatchInOtp m228 : 20|1@1+ (1,0) [0|0] "" Vector__XXX
 SG_ USM_a229_crcMismatchInOtp m229 : 20|1@1+ (1,0) [0|0] "" Vector__XXX
 SG_ USM_a230_crcMismatchInOtp m230 : 20|1@1+ (1,0) [0|0] "" Vector__XXX
 SG_ USM_a231_crcMismatchInOtp m231 : 20|1@1+ (1,0) [0|0] "" Vector__XXX
 SG_ USM_a232_crcMismatchInOtp m232 : 20|1@1+ (1,0) [0|0] "" Vector__XXX
 SG_ USM_a233_crcMismatchInOtp m233 : 20|1@1+ (1,0) [0|0] "" Vector__XXX
 SG_ USM_a234_crcMismatchInOtp m234 : 20|1@1+ (1,0) [0|0] "" Vector__XXX
 SG_ USM_a235_crcMismatchInOtp m235 : 20|1@1+ (1,0) [0|0] "" Vector__XXX
 SG_ USM_a236_crcMismatchInOtp m236 : 20|1@1+ (1,0) [0|0] "" Vector__XXX
 SG_ USM_a237_crcMismatchInOtp m237 : 20|1@1+ (1,0) [0|0] "" Vector__XXX
 SG_ USM_a238_crcMismatchInOtp m238 : 20|1@1+ (1,0) [0|0] "" Vector__XXX
 SG_ USM_a240_crcMismatchInOtp m240 : 20|1@1+ (1,0) [0|0] "" Vector__XXX
 SG_ USM_a241_crcMismatchInOtp m241 : 20|1@1+ (1,0) [0|0] "" Vector__XXX
 SG_ USM_a242_crcMismatchInOtp m242 : 20|1@1+ (1,0) [0|0] "" Vector__XXX
 SG_ USM_a243_crcMismatchInOtp m243 : 20|1@1+ (1,0) [0|0] "" Vector__XXX
 SG_ USM_a244_crcMismatchInOtp m244 : 20|1@1+ (1,0) [0|0] "" Vector__XXX
 SG_ USM_a245_crcMismatchInOtp m245 : 20|1@1+ (1,0) [0|0] "" Vector__XXX
 SG_ USM_a246_crcMismatchInOtp m246 : 20|1@1+ (1,0) [0|0] "" Vector__XXX
 SG_ USM_a247_crcMismatchInOtp m247 : 20|1@1+ (1,0) [0|0] "" Vector__XXX
 SG_ USM_a248_crcMismatchInOtp m248 : 20|1@1+ (1,0) [0|0] "" Vector__XXX
 SG_ USM_a249_crcMismatchInOtp m249 : 20|1@1+ (1,0) [0|0] "" Vector__XXX
 SG_ USM_a250_crcMismatchInOtp m250 : 20|1@1+ (1,0) [0|0] "" Vector__XXX
 SG_ USM_a251_crcMismatchInOtp m251 : 20|1@1+ (1,0) [0|0] "" Vector__XXX
 SG_ USM_a012_ExternalReset m12 : 21|1@1+ (1,0) [0|0] "" Vector__XXX
 SG_ USM_a021_Task10msMissed m21 : 21|1@1+ (1,0) [0|0] "" Vector__XXX
 SG_ USM_a086_VEH_lightStatus m86 : 21|1@1+ (1,0) [0|0] "" Vector__XXX
 SG_ USM_a087_PARTY_status m87 : 21|1@1+ (1,0) [0|0] "" Vector__XXX
 SG_ USM_a088_PARTY_status m88 : 21|1@1+ (1,0) [0|0] "" Vector__XXX
 SG_ USM_a089_CH_status m89 : 21|1@1+ (1,0) [0|0] "" Vector__XXX
 SG_ USM_a098_VEH_torque m98 : 21|1@1+ (1,0) [0|0] "" Vector__XXX
 SG_ USM_a103_VEH_evseStatus m103 : 21|1@1+ (1,0) [0|0] "" Vector__XXX
 SG_ USM_a104_CH_control m104 : 21|1@1+ (1,0) [0|0] "" Vector__XXX
 SG_ USM_a107_VEH_powerAvailable m107 : 21|1@1+ (1,0) [0|0] "" Vector__XXX
 SG_ USM_a108_PARTY_torque m108 : 21|1@1+ (1,0) [0|0] "" Vector__XXX
 SG_ USM_a109_VEH_imuOffsets m109 : 21|1@1+ (1,0) [0|0] "" Vector__XXX
 SG_ USM_a110_VEH_mismatchFault m110 : 21|1@1+ (1,0) [0|0] "" Vector__XXX
 SG_ USM_a111_RIPC_railStatus m111 : 21|1@1+ (1,0) [0|0] "" Vector__XXX
 SG_ USM_a112_LIPC_railStatus m112 : 21|1@1+ (1,0) [0|0] "" Vector__XXX
 SG_ USM_a113_VEH_peripheralPowerRequests m113 : 21|1@1+ (1,0) [0|0] "" Vector__XXX
 SG_ USM_a114_VEH_party3 m114 : 21|1@1+ (1,0) [0|0] "" Vector__XXX
 SG_ USM_a115_REM_authentication m115 : 21|1@1+ (1,0) [0|0] "" Vector__XXX
 SG_ USM_a116_VEH_lightStatus m116 : 21|1@1+ (1,0) [0|0] "" Vector__XXX
 SG_ USM_a117_VEH_hvacBlowerFdb m117 : 21|1@1+ (1,0) [0|0] "" Vector__XXX
 SG_ USM_a118_VEH_LVPowerState m118 : 21|1@1+ (1,0) [0|0] "" Vector__XXX
 SG_ USM_a119_PARTY_steerAngle m119 : 21|1@1+ (1,0) [0|0] "" Vector__XXX
 SG_ USM_a120_VEH_torque m120 : 21|1@1+ (1,0) [0|0] "" Vector__XXX
 SG_ USM_a201_CMD_INC m201 : 21|1@1+ (1,0) [0|0] "" Vector__XXX
 SG_ USM_a202_LE m202 : 21|1@1+ (1,0) [0|0] "" Vector__XXX
 SG_ USM_a227_crcMismatchInSysrom m227 : 21|1@1+ (1,0) [0|0] "" Vector__XXX
 SG_ USM_a228_crcMismatchInSysrom m228 : 21|1@1+ (1,0) [0|0] "" Vector__XXX
 SG_ USM_a229_crcMismatchInSysrom m229 : 21|1@1+ (1,0) [0|0] "" Vector__XXX
 SG_ USM_a230_crcMismatchInSysrom m230 : 21|1@1+ (1,0) [0|0] "" Vector__XXX
 SG_ USM_a231_crcMismatchInSysrom m231 : 21|1@1+ (1,0) [0|0] "" Vector__XXX
 SG_ USM_a232_crcMismatchInSysrom m232 : 21|1@1+ (1,0) [0|0] "" Vector__XXX
 SG_ USM_a233_crcMismatchInSysrom m233 : 21|1@1+ (1,0) [0|0] "" Vector__XXX
 SG_ USM_a234_crcMismatchInSysrom m234 : 21|1@1+ (1,0) [0|0] "" Vector__XXX
 SG_ USM_a235_crcMismatchInSysrom m235 : 21|1@1+ (1,0) [0|0] "" Vector__XXX
 SG_ USM_a236_crcMismatchInSysrom m236 : 21|1@1+ (1,0) [0|0] "" Vector__XXX
 SG_ USM_a237_crcMismatchInSysrom m237 : 21|1@1+ (1,0) [0|0] "" Vector__XXX
 SG_ USM_a238_crcMismatchInSysrom m238 : 21|1@1+ (1,0) [0|0] "" Vector__XXX
 SG_ USM_a240_crcMismatchInSysrom m240 : 21|1@1+ (1,0) [0|0] "" Vector__XXX
 SG_ USM_a241_crcMismatchInSysrom m241 : 21|1@1+ (1,0) [0|0] "" Vector__XXX
 SG_ USM_a242_crcMismatchInSysrom m242 : 21|1@1+ (1,0) [0|0] "" Vector__XXX
 SG_ USM_a243_crcMismatchInSysrom m243 : 21|1@1+ (1,0) [0|0] "" Vector__XXX
 SG_ USM_a244_crcMismatchInSysrom m244 : 21|1@1+ (1,0) [0|0] "" Vector__XXX
 SG_ USM_a245_crcMismatchInSysrom m245 : 21|1@1+ (1,0) [0|0] "" Vector__XXX
 SG_ USM_a246_crcMismatchInSysrom m246 : 21|1@1+ (1,0) [0|0] "" Vector__XXX
 SG_ USM_a247_crcMismatchInSysrom m247 : 21|1@1+ (1,0) [0|0] "" Vector__XXX
 SG_ USM_a248_crcMismatchInSysrom m248 : 21|1@1+ (1,0) [0|0] "" Vector__XXX
 SG_ USM_a249_crcMismatchInSysrom m249 : 21|1@1+ (1,0) [0|0] "" Vector__XXX
 SG_ USM_a250_crcMismatchInSysrom m250 : 21|1@1+ (1,0) [0|0] "" Vector__XXX
 SG_ USM_a251_crcMismatchInSysrom m251 : 21|1@1+ (1,0) [0|0] "" Vector__XXX
 SG_ USM_a021_Task100msLate m21 : 22|1@1+ (1,0) [0|0] "" Vector__XXX
 SG_ USM_a086_VEH_systemStatus m86 : 22|1@1+ (1,0) [0|0] "" Vector__XXX
 SG_ USM_a087_PARTY_temperature m87 : 22|1@1+ (1,0) [0|0] "" Vector__XXX
 SG_ USM_a088_PARTY_temperature m88 : 22|1@1+ (1,0) [0|0] "" Vector__XXX
 SG_ USM_a089_CH_party1 m89 : 22|1@1+ (1,0) [0|0] "" Vector__XXX
 SG_ USM_a098_PARTY_status m98 : 22|1@1+ (1,0) [0|0] "" Vector__XXX
 SG_ USM_a104_PARTY_control m104 : 22|1@1+ (1,0) [0|0] "" Vector__XXX
 SG_ USM_a107_PT_ptNm m107 : 22|1@1+ (1,0) [0|0] "" Vector__XXX
 SG_ USM_a108_PARTY_status m108 : 22|1@1+ (1,0) [0|0] "" Vector__XXX
 SG_ USM_a109_PARTY_inertial1 m109 : 22|1@1+ (1,0) [0|0] "" Vector__XXX
 SG_ USM_a110_VEH_vin m110 : 22|1@1+ (1,0) [0|0] "" Vector__XXX
 SG_ USM_a111_RIPC_remoteADC m111 : 22|1@1+ (1,0) [0|0] "" Vector__XXX
 SG_ USM_a112_LIPC_remoteADC m112 : 22|1@1+ (1,0) [0|0] "" Vector__XXX
 SG_ USM_a113_VEH_corianderVehicleControl m113 : 22|1@1+ (1,0) [0|0] "" Vector__XXX
 SG_ USM_a114_VEH_status m114 : 22|1@1+ (1,0) [0|0] "" Vector__XXX
 SG_ USM_a115_UI_corianderVehicleControl m115 : 22|1@1+ (1,0) [0|0] "" Vector__XXX
 SG_ USM_a116_VEH_seatStatus m116 : 22|1@1+ (1,0) [0|0] "" Vector__XXX
 SG_ USM_a117_VEH_LVPowerState m117 : 22|1@1+ (1,0) [0|0] "" Vector__XXX
 SG_ USM_a118_VEH_coolant m118 : 22|1@1+ (1,0) [0|0] "" Vector__XXX
 SG_ USM_a120_PARTY_locStatus m120 : 22|1@1+ (1,0) [0|0] "" Vector__XXX
 SG_ USM_a201_CRC_ERROR m201 : 22|1@1+ (1,0) [0|0] "" Vector__XXX
 SG_ USM_a202_SC m202 : 22|1@1+ (1,0) [0|0] "" Vector__XXX
 SG_ USM_a227_crcMismatchInEeprom m227 : 22|1@1+ (1,0) [0|0] "" Vector__XXX
 SG_ USM_a228_crcMismatchInEeprom m228 : 22|1@1+ (1,0) [0|0] "" Vector__XXX
 SG_ USM_a229_crcMismatchInEeprom m229 : 22|1@1+ (1,0) [0|0] "" Vector__XXX
 SG_ USM_a230_crcMismatchInEeprom m230 : 22|1@1+ (1,0) [0|0] "" Vector__XXX
 SG_ USM_a231_crcMismatchInEeprom m231 : 22|1@1+ (1,0) [0|0] "" Vector__XXX
 SG_ USM_a232_crcMismatchInEeprom m232 : 22|1@1+ (1,0) [0|0] "" Vector__XXX
 SG_ USM_a233_crcMismatchInEeprom m233 : 22|1@1+ (1,0) [0|0] "" Vector__XXX
 SG_ USM_a234_crcMismatchInEeprom m234 : 22|1@1+ (1,0) [0|0] "" Vector__XXX
 SG_ USM_a235_crcMismatchInEeprom m235 : 22|1@1+ (1,0) [0|0] "" Vector__XXX
 SG_ USM_a236_crcMismatchInEeprom m236 : 22|1@1+ (1,0) [0|0] "" Vector__XXX
 SG_ USM_a237_crcMismatchInEeprom m237 : 22|1@1+ (1,0) [0|0] "" Vector__XXX
 SG_ USM_a238_crcMismatchInEeprom m238 : 22|1@1+ (1,0) [0|0] "" Vector__XXX
 SG_ USM_a240_crcMismatchInEeprom m240 : 22|1@1+ (1,0) [0|0] "" Vector__XXX
 SG_ USM_a241_crcMismatchInEeprom m241 : 22|1@1+ (1,0) [0|0] "" Vector__XXX
 SG_ USM_a242_crcMismatchInEeprom m242 : 22|1@1+ (1,0) [0|0] "" Vector__XXX
 SG_ USM_a243_crcMismatchInEeprom m243 : 22|1@1+ (1,0) [0|0] "" Vector__XXX
 SG_ USM_a244_crcMismatchInEeprom m244 : 22|1@1+ (1,0) [0|0] "" Vector__XXX
 SG_ USM_a245_crcMismatchInEeprom m245 : 22|1@1+ (1,0) [0|0] "" Vector__XXX
 SG_ USM_a246_crcMismatchInEeprom m246 : 22|1@1+ (1,0) [0|0] "" Vector__XXX
 SG_ USM_a247_crcMismatchInEeprom m247 : 22|1@1+ (1,0) [0|0] "" Vector__XXX
 SG_ USM_a248_crcMismatchInEeprom m248 : 22|1@1+ (1,0) [0|0] "" Vector__XXX
 SG_ USM_a249_crcMismatchInEeprom m249 : 22|1@1+ (1,0) [0|0] "" Vector__XXX
 SG_ USM_a250_crcMismatchInEeprom m250 : 22|1@1+ (1,0) [0|0] "" Vector__XXX
 SG_ USM_a251_crcMismatchInEeprom m251 : 22|1@1+ (1,0) [0|0] "" Vector__XXX
 SG_ USM_a021_Task100msStarved m21 : 23|1@1+ (1,0) [0|0] "" Vector__XXX
 SG_ USM_a086_VEH_thermalStatus m86 : 23|1@1+ (1,0) [0|0] "" Vector__XXX
 SG_ USM_a087_PARTY_thermalControl m87 : 23|1@1+ (1,0) [0|0] "" Vector__XXX
 SG_ USM_a088_PARTY_thermalControl m88 : 23|1@1+ (1,0) [0|0] "" Vector__XXX
 SG_ USM_a089_CH_party3 m89 : 23|1@1+ (1,0) [0|0] "" Vector__XXX
 SG_ USM_a098_PARTY_temperature m98 : 23|1@1+ (1,0) [0|0] "" Vector__XXX
 SG_ USM_a104_PARTY_bodyControls m104 : 23|1@1+ (1,0) [0|0] "" Vector__XXX
 SG_ USM_a107_PT_status m107 : 23|1@1+ (1,0) [0|0] "" Vector__XXX
 SG_ USM_a108_PARTY_temperature m108 : 23|1@1+ (1,0) [0|0] "" Vector__XXX
 SG_ USM_a109_BDY_imuOffsets m109 : 23|1@1+ (1,0) [0|0] "" Vector__XXX
 SG_ USM_a110_VEH_bmpDebug m110 : 23|1@1+ (1,0) [0|0] "" Vector__XXX
 SG_ USM_a111_RIPC_switchStatus m111 : 23|1@1+ (1,0) [0|0] "" Vector__XXX
 SG_ USM_a112_LIPC_switchStatus m112 : 23|1@1+ (1,0) [0|0] "" Vector__XXX
 SG_ USM_a113_VEH_solarData m113 : 23|1@1+ (1,0) [0|0] "" Vector__XXX
 SG_ USM_a114_PARTY_wheelRotation m114 : 23|1@1+ (1,0) [0|0] "" Vector__XXX
 SG_ USM_a115_CH_TPMSDisplay m115 : 23|1@1+ (1,0) [0|0] "" Vector__XXX
 SG_ USM_a116_VEH_thsStatus m116 : 23|1@1+ (1,0) [0|0] "" Vector__XXX
 SG_ USM_a117_VEH_restraintStatus m117 : 23|1@1+ (1,0) [0|0] "" Vector__XXX
 SG_ USM_a118_VEH_vehicleStatus m118 : 23|1@1+ (1,0) [0|0] "" Vector__XXX
 SG_ USM_a120_PARTY_speed m120 : 23|1@1+ (1,0) [0|0] "" Vector__XXX
 SG_ USM_a201_UND_CMD m201 : 23|1@1+ (1,0) [0|0] "" Vector__XXX
 SG_ USM_a202_CR m202 : 23|1@1+ (1,0) [0|0] "" Vector__XXX
 SG_ USM_a227_capLossVdddOutOfRange m227 : 23|1@1+ (1,0) [0|0] "" Vector__XXX
 SG_ USM_a228_capLossVdddOutOfRange m228 : 23|1@1+ (1,0) [0|0] "" Vector__XXX
 SG_ USM_a229_capLossVdddOutOfRange m229 : 23|1@1+ (1,0) [0|0] "" Vector__XXX
 SG_ USM_a230_capLossVdddOutOfRange m230 : 23|1@1+ (1,0) [0|0] "" Vector__XXX
 SG_ USM_a231_capLossVdddOutOfRange m231 : 23|1@1+ (1,0) [0|0] "" Vector__XXX
 SG_ USM_a232_capLossVdddOutOfRange m232 : 23|1@1+ (1,0) [0|0] "" Vector__XXX
 SG_ USM_a233_capLossVdddOutOfRange m233 : 23|1@1+ (1,0) [0|0] "" Vector__XXX
 SG_ USM_a234_capLossVdddOutOfRange m234 : 23|1@1+ (1,0) [0|0] "" Vector__XXX
 SG_ USM_a235_capLossVdddOutOfRange m235 : 23|1@1+ (1,0) [0|0] "" Vector__XXX
 SG_ USM_a236_capLossVdddOutOfRange m236 : 23|1@1+ (1,0) [0|0] "" Vector__XXX
 SG_ USM_a237_capLossVdddOutOfRange m237 : 23|1@1+ (1,0) [0|0] "" Vector__XXX
 SG_ USM_a238_capLossVdddOutOfRange m238 : 23|1@1+ (1,0) [0|0] "" Vector__XXX
 SG_ USM_a240_capLossVdddOutOfRange m240 : 23|1@1+ (1,0) [0|0] "" Vector__XXX
 SG_ USM_a241_capLossVdddOutOfRange m241 : 23|1@1+ (1,0) [0|0] "" Vector__XXX
 SG_ USM_a242_capLossVdddOutOfRange m242 : 23|1@1+ (1,0) [0|0] "" Vector__XXX
 SG_ USM_a243_capLossVdddOutOfRange m243 : 23|1@1+ (1,0) [0|0] "" Vector__XXX
 SG_ USM_a244_capLossVdddOutOfRange m244 : 23|1@1+ (1,0) [0|0] "" Vector__XXX
 SG_ USM_a245_capLossVdddOutOfRange m245 : 23|1@1+ (1,0) [0|0] "" Vector__XXX
 SG_ USM_a246_capLossVdddOutOfRange m246 : 23|1@1+ (1,0) [0|0] "" Vector__XXX
 SG_ USM_a247_capLossVdddOutOfRange m247 : 23|1@1+ (1,0) [0|0] "" Vector__XXX
 SG_ USM_a248_capLossVdddOutOfRange m248 : 23|1@1+ (1,0) [0|0] "" Vector__XXX
 SG_ USM_a249_capLossVdddOutOfRange m249 : 23|1@1+ (1,0) [0|0] "" Vector__XXX
 SG_ USM_a250_capLossVdddOutOfRange m250 : 23|1@1+ (1,0) [0|0] "" Vector__XXX
 SG_ USM_a251_capLossVdddOutOfRange m251 : 23|1@1+ (1,0) [0|0] "" Vector__XXX
 SG_ USM_a006_mailboxID m6 : 24|8@1+ (1,0) [0|0] "" Vector__XXX
 SG_ USM_a021_Task100msMissed m21 : 24|1@1+ (1,0) [0|0] "" Vector__XXX
 SG_ USM_a022_TaskInitError0 m22 : 24|8@1+ (1,0) [0|0] "" Vector__XXX
 SG_ USM_a031_uds_bytes_1 m31 : 24|8@1+ (1,0) [0|0] "" Vector__XXX
 SG_ USM_a041_CPULoad1msTask m41 : 24|8@1+ (1,0) [0|0] "" Vector__XXX
 SG_ USM_a042_Usage10msTask m42 : 24|8@1+ (1,0) [0|0] "" Vector__XXX
 SG_ USM_a063_switchType m63 : 24|8@1+ (1,0) [0|0] "" Vector__XXX
 SG_ USM_a086_VEH_vehNm m86 : 24|1@1+ (1,0) [0|0] "" Vector__XXX
 SG_ USM_a087_VEH_motorStatus m87 : 24|1@1+ (1,0) [0|0] "" Vector__XXX
 SG_ USM_a088_VEH_motorStatus m88 : 24|1@1+ (1,0) [0|0] "" Vector__XXX
 SG_ USM_a089_VEH_party1 m89 : 24|1@1+ (1,0) [0|0] "" Vector__XXX
 SG_ USM_a098_PARTY_thermalControl m98 : 24|1@1+ (1,0) [0|0] "" Vector__XXX
 SG_ USM_a104_PARTY_gpsAccuracies m104 : 24|1@1+ (1,0) [0|0] "" Vector__XXX
 SG_ USM_a107_PT_thermalStatus m107 : 24|1@1+ (1,0) [0|0] "" Vector__XXX
 SG_ USM_a108_PARTY_thermalControl m108 : 24|1@1+ (1,0) [0|0] "" Vector__XXX
 SG_ USM_a109_BDY_inertial1 m109 : 24|1@1+ (1,0) [0|0] "" Vector__XXX
 SG_ USM_a110_VEH_gearControl m110 : 24|1@1+ (1,0) [0|0] "" Vector__XXX
 SG_ USM_a111_VEH_LVPowerState m111 : 24|1@1+ (1,0) [0|0] "" Vector__XXX
 SG_ USM_a112_VEH_LVPowerState m112 : 24|1@1+ (1,0) [0|0] "" Vector__XXX
 SG_ USM_a113_VEH_ventCntlReq m113 : 24|1@1+ (1,0) [0|0] "" Vector__XXX
 SG_ USM_a114_CH_wheelRotation m114 : 24|1@1+ (1,0) [0|0] "" Vector__XXX
 SG_ USM_a116_VEH_doorStatus m116 : 24|1@1+ (1,0) [0|0] "" Vector__XXX
 SG_ USM_a117_VEH_lightStatus m117 : 24|1@1+ (1,0) [0|0] "" Vector__XXX
 SG_ USM_a118_VEH_12VBatteryStatus m118 : 24|1@1+ (1,0) [0|0] "" Vector__XXX
 SG_ USM_a120_VEH_speed m120 : 24|1@1+ (1,0) [0|0] "" Vector__XXX
 SG_ USM_a131_timeSinceInit m131 : 24|16@1+ (1,0) [0|0] "" Vector__XXX
 SG_ USM_a132_timeSinceInit m132 : 24|16@1+ (1,0) [0|0] "" Vector__XXX
 SG_ USM_a133_timeSinceInit m133 : 24|16@1+ (1,0) [0|0] "" Vector__XXX
 SG_ USM_a134_timeSinceInit m134 : 24|16@1+ (1,0) [0|0] "" Vector__XXX
 SG_ USM_a135_timeSinceInit m135 : 24|16@1+ (1,0) [0|0] "" Vector__XXX
 SG_ USM_a136_timeSinceInit m136 : 24|16@1+ (1,0) [0|0] "" Vector__XXX
 SG_ USM_a137_timeSinceInit m137 : 24|16@1+ (1,0) [0|0] "" Vector__XXX
 SG_ USM_a138_timeSinceInit m138 : 24|16@1+ (1,0) [0|0] "" Vector__XXX
 SG_ USM_a139_timeSinceInit m139 : 24|16@1+ (1,0) [0|0] "" Vector__XXX
 SG_ USM_a140_timeSinceInit m140 : 24|16@1+ (1,0) [0|0] "" Vector__XXX
 SG_ USM_a141_timeSinceInit m141 : 24|16@1+ (1,0) [0|0] "" Vector__XXX
 SG_ USM_a142_timeSinceInit m142 : 24|16@1+ (1,0) [0|0] "" Vector__XXX
 SG_ USM_a143_timeSinceInit m143 : 24|16@1+ (1,0) [0|0] "" Vector__XXX
 SG_ USM_a144_timeSinceInit m144 : 24|16@1+ (1,0) [0|0] "" Vector__XXX
 SG_ USM_a145_timeSinceInit m145 : 24|16@1+ (1,0) [0|0] "" Vector__XXX
 SG_ USM_a146_timeSinceInit m146 : 24|16@1+ (1,0) [0|0] "" Vector__XXX
 SG_ USM_a147_timeSinceInit m147 : 24|16@1+ (1,0) [0|0] "" Vector__XXX
 SG_ USM_a148_timeSinceInit m148 : 24|16@1+ (1,0) [0|0] "" Vector__XXX
 SG_ USM_a149_timeSinceInit m149 : 24|16@1+ (1,0) [0|0] "" Vector__XXX
 SG_ USM_a150_timeSinceInit m150 : 24|16@1+ (1,0) [0|0] "" Vector__XXX
 SG_ USM_a151_timeSinceInit m151 : 24|16@1+ (1,0) [0|0] "" Vector__XXX
 SG_ USM_a152_timeSinceInit m152 : 24|16@1+ (1,0) [0|0] "" Vector__XXX
 SG_ USM_a153_timeSinceInit m153 : 24|16@1+ (1,0) [0|0] "" Vector__XXX
 SG_ USM_a154_timeSinceInit m154 : 24|16@1+ (1,0) [0|0] "" Vector__XXX
 SG_ USM_a177_rtmOffset m177 : 24|8@1- (2,0) [0|0] "" Vector__XXX
 SG_ USM_a178_rtmOffset m178 : 24|8@1- (2,0) [0|0] "" Vector__XXX
 SG_ USM_a179_rtmOffset m179 : 24|8@1- (2,0) [0|0] "" Vector__XXX
 SG_ USM_a180_rtmOffset m180 : 24|8@1- (2,0) [0|0] "" Vector__XXX
 SG_ USM_a181_rtmOffset m181 : 24|8@1- (2,0) [0|0] "" Vector__XXX
 SG_ USM_a182_rtmOffset m182 : 24|8@1- (2,0) [0|0] "" Vector__XXX
 SG_ USM_a183_rtmOffset m183 : 24|8@1- (2,0) [0|0] "" Vector__XXX
 SG_ USM_a184_rtmOffset m184 : 24|8@1- (2,0) [0|0] "" Vector__XXX
 SG_ USM_a185_rtmOffset m185 : 24|8@1- (2,0) [0|0] "" Vector__XXX
 SG_ USM_a186_rtmOffset m186 : 24|8@1- (2,0) [0|0] "" Vector__XXX
 SG_ USM_a187_rtmOffset m187 : 24|8@1- (2,0) [0|0] "" Vector__XXX
 SG_ USM_a188_rtmOffset m188 : 24|8@1- (2,0) [0|0] "" Vector__XXX
 SG_ USM_a201_DSI1_CMD_OVR m201 : 24|1@1+ (1,0) [0|0] "" Vector__XXX
 SG_ USM_a202_SP m202 : 24|1@1+ (1,0) [0|0] "" Vector__XXX
 SG_ USM_a227_capLossVddaOutOfRange m227 : 24|1@1+ (1,0) [0|0] "" Vector__XXX
 SG_ USM_a228_capLossVddaOutOfRange m228 : 24|1@1+ (1,0) [0|0] "" Vector__XXX
 SG_ USM_a229_capLossVddaOutOfRange m229 : 24|1@1+ (1,0) [0|0] "" Vector__XXX
 SG_ USM_a230_capLossVddaOutOfRange m230 : 24|1@1+ (1,0) [0|0] "" Vector__XXX
 SG_ USM_a231_capLossVddaOutOfRange m231 : 24|1@1+ (1,0) [0|0] "" Vector__XXX
 SG_ USM_a232_capLossVddaOutOfRange m232 : 24|1@1+ (1,0) [0|0] "" Vector__XXX
 SG_ USM_a233_capLossVddaOutOfRange m233 : 24|1@1+ (1,0) [0|0] "" Vector__XXX
 SG_ USM_a234_capLossVddaOutOfRange m234 : 24|1@1+ (1,0) [0|0] "" Vector__XXX
 SG_ USM_a235_capLossVddaOutOfRange m235 : 24|1@1+ (1,0) [0|0] "" Vector__XXX
 SG_ USM_a236_capLossVddaOutOfRange m236 : 24|1@1+ (1,0) [0|0] "" Vector__XXX
 SG_ USM_a237_capLossVddaOutOfRange m237 : 24|1@1+ (1,0) [0|0] "" Vector__XXX
 SG_ USM_a238_capLossVddaOutOfRange m238 : 24|1@1+ (1,0) [0|0] "" Vector__XXX
 SG_ USM_a240_capLossVddaOutOfRange m240 : 24|1@1+ (1,0) [0|0] "" Vector__XXX
 SG_ USM_a241_capLossVddaOutOfRange m241 : 24|1@1+ (1,0) [0|0] "" Vector__XXX
 SG_ USM_a242_capLossVddaOutOfRange m242 : 24|1@1+ (1,0) [0|0] "" Vector__XXX
 SG_ USM_a243_capLossVddaOutOfRange m243 : 24|1@1+ (1,0) [0|0] "" Vector__XXX
 SG_ USM_a244_capLossVddaOutOfRange m244 : 24|1@1+ (1,0) [0|0] "" Vector__XXX
 SG_ USM_a245_capLossVddaOutOfRange m245 : 24|1@1+ (1,0) [0|0] "" Vector__XXX
 SG_ USM_a246_capLossVddaOutOfRange m246 : 24|1@1+ (1,0) [0|0] "" Vector__XXX
 SG_ USM_a247_capLossVddaOutOfRange m247 : 24|1@1+ (1,0) [0|0] "" Vector__XXX
 SG_ USM_a248_capLossVddaOutOfRange m248 : 24|1@1+ (1,0) [0|0] "" Vector__XXX
 SG_ USM_a249_capLossVddaOutOfRange m249 : 24|1@1+ (1,0) [0|0] "" Vector__XXX
 SG_ USM_a250_capLossVddaOutOfRange m250 : 24|1@1+ (1,0) [0|0] "" Vector__XXX
 SG_ USM_a251_capLossVddaOutOfRange m251 : 24|1@1+ (1,0) [0|0] "" Vector__XXX
 SG_ USM_a021_Task1000msLate m21 : 25|1@1+ (1,0) [0|0] "" Vector__XXX
 SG_ USM_a089_VEH_party3 m89 : 25|1@1+ (1,0) [0|0] "" Vector__XXX
 SG_ USM_a098_PARTY_torque m98 : 25|1@1+ (1,0) [0|0] "" Vector__XXX
 SG_ USM_a104_CH_status m104 : 25|1@1+ (1,0) [0|0] "" Vector__XXX
 SG_ USM_a107_PT_socStatus m107 : 25|1@1+ (1,0) [0|0] "" Vector__XXX
 SG_ USM_a108_PT_temperature m108 : 25|1@1+ (1,0) [0|0] "" Vector__XXX
 SG_ USM_a109_BDY_inertial2 m109 : 25|1@1+ (1,0) [0|0] "" Vector__XXX
 SG_ USM_a110_VEH_canLogAvailability m110 : 25|1@1+ (1,0) [0|0] "" Vector__XXX
 SG_ USM_a111_VEH_seatStatus m111 : 25|1@1+ (1,0) [0|0] "" Vector__XXX
 SG_ USM_a112_PARTY_status m112 : 25|1@1+ (1,0) [0|0] "" Vector__XXX
 SG_ USM_a113_VEH_chassisControl m113 : 25|1@1+ (1,0) [0|0] "" Vector__XXX
 SG_ USM_a114_VEH_wheelRotation m114 : 25|1@1+ (1,0) [0|0] "" Vector__XXX
 SG_ USM_a116_VEH_seatHeatStatus m116 : 25|1@1+ (1,0) [0|0] "" Vector__XXX
 SG_ USM_a117_VEH_seatStatus m117 : 25|1@1+ (1,0) [0|0] "" Vector__XXX
 SG_ USM_a118_VEH_systemStatus m118 : 25|1@1+ (1,0) [0|0] "" Vector__XXX
 SG_ USM_a120_PARTY_status m120 : 25|1@1+ (1,0) [0|0] "" Vector__XXX
 SG_ USM_a201_DSI2_CMD_OVR m201 : 25|1@1+ (1,0) [0|0] "" Vector__XXX
 SG_ USM_a202_SE m202 : 25|1@1+ (1,0) [0|0] "" Vector__XXX
 SG_ USM_a227_referenceVoltOutOfRange m227 : 25|1@1+ (1,0) [0|0] "" Vector__XXX
 SG_ USM_a228_referenceVoltOutOfRange m228 : 25|1@1+ (1,0) [0|0] "" Vector__XXX
 SG_ USM_a229_referenceVoltOutOfRange m229 : 25|1@1+ (1,0) [0|0] "" Vector__XXX
 SG_ USM_a230_referenceVoltOutOfRange m230 : 25|1@1+ (1,0) [0|0] "" Vector__XXX
 SG_ USM_a231_referenceVoltOutOfRange m231 : 25|1@1+ (1,0) [0|0] "" Vector__XXX
 SG_ USM_a232_referenceVoltOutOfRange m232 : 25|1@1+ (1,0) [0|0] "" Vector__XXX
 SG_ USM_a233_referenceVoltOutOfRange m233 : 25|1@1+ (1,0) [0|0] "" Vector__XXX
 SG_ USM_a234_referenceVoltOutOfRange m234 : 25|1@1+ (1,0) [0|0] "" Vector__XXX
 SG_ USM_a235_referenceVoltOutOfRange m235 : 25|1@1+ (1,0) [0|0] "" Vector__XXX
 SG_ USM_a236_referenceVoltOutOfRange m236 : 25|1@1+ (1,0) [0|0] "" Vector__XXX
 SG_ USM_a237_referenceVoltOutOfRange m237 : 25|1@1+ (1,0) [0|0] "" Vector__XXX
 SG_ USM_a238_referenceVoltOutOfRange m238 : 25|1@1+ (1,0) [0|0] "" Vector__XXX
 SG_ USM_a240_referenceVoltOutOfRange m240 : 25|1@1+ (1,0) [0|0] "" Vector__XXX
 SG_ USM_a241_referenceVoltOutOfRange m241 : 25|1@1+ (1,0) [0|0] "" Vector__XXX
 SG_ USM_a242_referenceVoltOutOfRange m242 : 25|1@1+ (1,0) [0|0] "" Vector__XXX
 SG_ USM_a243_referenceVoltOutOfRange m243 : 25|1@1+ (1,0) [0|0] "" Vector__XXX
 SG_ USM_a244_referenceVoltOutOfRange m244 : 25|1@1+ (1,0) [0|0] "" Vector__XXX
 SG_ USM_a245_referenceVoltOutOfRange m245 : 25|1@1+ (1,0) [0|0] "" Vector__XXX
 SG_ USM_a246_referenceVoltOutOfRange m246 : 25|1@1+ (1,0) [0|0] "" Vector__XXX
 SG_ USM_a247_referenceVoltOutOfRange m247 : 25|1@1+ (1,0) [0|0] "" Vector__XXX
 SG_ USM_a248_referenceVoltOutOfRange m248 : 25|1@1+ (1,0) [0|0] "" Vector__XXX
 SG_ USM_a249_referenceVoltOutOfRange m249 : 25|1@1+ (1,0) [0|0] "" Vector__XXX
 SG_ USM_a250_referenceVoltOutOfRange m250 : 25|1@1+ (1,0) [0|0] "" Vector__XXX
 SG_ USM_a251_referenceVoltOutOfRange m251 : 25|1@1+ (1,0) [0|0] "" Vector__XXX
 SG_ USM_a021_Task1000msStarved m21 : 26|1@1+ (1,0) [0|0] "" Vector__XXX
 SG_ USM_a098_PT_thermalControl m98 : 26|1@1+ (1,0) [0|0] "" Vector__XXX
 SG_ USM_a104_PARTY_status m104 : 26|1@1+ (1,0) [0|0] "" Vector__XXX
 SG_ USM_a107_VEH_socStatus m107 : 26|1@1+ (1,0) [0|0] "" Vector__XXX
 SG_ USM_a108_PT_thermalControl m108 : 26|1@1+ (1,0) [0|0] "" Vector__XXX
 SG_ USM_a109_BDY_status m109 : 26|1@1+ (1,0) [0|0] "" Vector__XXX
 SG_ USM_a110_CH_airbagCutoffStatus m110 : 26|1@1+ (1,0) [0|0] "" Vector__XXX
 SG_ USM_a111_PARTY_status m111 : 26|1@1+ (1,0) [0|0] "" Vector__XXX
 SG_ USM_a112_CH_status m112 : 26|1@1+ (1,0) [0|0] "" Vector__XXX
 SG_ USM_a113_VEH_trackModeSettings m113 : 26|1@1+ (1,0) [0|0] "" Vector__XXX
 SG_ USM_a114_PARTY_brakeTorque m114 : 26|1@1+ (1,0) [0|0] "" Vector__XXX
 SG_ USM_a116_VEH_restraintStatus m116 : 26|1@1+ (1,0) [0|0] "" Vector__XXX
 SG_ USM_a117_BDY_falconSwitchStatus m117 : 26|1@1+ (1,0) [0|0] "" Vector__XXX
 SG_ USM_a118_PARTY_LVPowerState m118 : 26|1@1+ (1,0) [0|0] "" Vector__XXX
 SG_ USM_a120_PT_speed m120 : 26|1@1+ (1,0) [0|0] "" Vector__XXX
 SG_ USM_a201_DSI1_UV m201 : 26|1@1+ (1,0) [0|0] "" Vector__XXX
 SG_ USM_a202_UV m202 : 26|1@1+ (1,0) [0|0] "" Vector__XXX
 SG_ USM_a227_vdddVoltOutOfRange m227 : 26|1@1+ (1,0) [0|0] "" Vector__XXX
 SG_ USM_a228_vdddVoltOutOfRange m228 : 26|1@1+ (1,0) [0|0] "" Vector__XXX
 SG_ USM_a229_vdddVoltOutOfRange m229 : 26|1@1+ (1,0) [0|0] "" Vector__XXX
 SG_ USM_a230_vdddVoltOutOfRange m230 : 26|1@1+ (1,0) [0|0] "" Vector__XXX
 SG_ USM_a231_vdddVoltOutOfRange m231 : 26|1@1+ (1,0) [0|0] "" Vector__XXX
 SG_ USM_a232_vdddVoltOutOfRange m232 : 26|1@1+ (1,0) [0|0] "" Vector__XXX
 SG_ USM_a233_vdddVoltOutOfRange m233 : 26|1@1+ (1,0) [0|0] "" Vector__XXX
 SG_ USM_a234_vdddVoltOutOfRange m234 : 26|1@1+ (1,0) [0|0] "" Vector__XXX
 SG_ USM_a235_vdddVoltOutOfRange m235 : 26|1@1+ (1,0) [0|0] "" Vector__XXX
 SG_ USM_a236_vdddVoltOutOfRange m236 : 26|1@1+ (1,0) [0|0] "" Vector__XXX
 SG_ USM_a237_vdddVoltOutOfRange m237 : 26|1@1+ (1,0) [0|0] "" Vector__XXX
 SG_ USM_a238_vdddVoltOutOfRange m238 : 26|1@1+ (1,0) [0|0] "" Vector__XXX
 SG_ USM_a240_vdddVoltOutOfRange m240 : 26|1@1+ (1,0) [0|0] "" Vector__XXX
 SG_ USM_a241_vdddVoltOutOfRange m241 : 26|1@1+ (1,0) [0|0] "" Vector__XXX
 SG_ USM_a242_vdddVoltOutOfRange m242 : 26|1@1+ (1,0) [0|0] "" Vector__XXX
 SG_ USM_a243_vdddVoltOutOfRange m243 : 26|1@1+ (1,0) [0|0] "" Vector__XXX
 SG_ USM_a244_vdddVoltOutOfRange m244 : 26|1@1+ (1,0) [0|0] "" Vector__XXX
 SG_ USM_a245_vdddVoltOutOfRange m245 : 26|1@1+ (1,0) [0|0] "" Vector__XXX
 SG_ USM_a246_vdddVoltOutOfRange m246 : 26|1@1+ (1,0) [0|0] "" Vector__XXX
 SG_ USM_a247_vdddVoltOutOfRange m247 : 26|1@1+ (1,0) [0|0] "" Vector__XXX
 SG_ USM_a248_vdddVoltOutOfRange m248 : 26|1@1+ (1,0) [0|0] "" Vector__XXX
 SG_ USM_a249_vdddVoltOutOfRange m249 : 26|1@1+ (1,0) [0|0] "" Vector__XXX
 SG_ USM_a250_vdddVoltOutOfRange m250 : 26|1@1+ (1,0) [0|0] "" Vector__XXX
 SG_ USM_a251_vdddVoltOutOfRange m251 : 26|1@1+ (1,0) [0|0] "" Vector__XXX
 SG_ USM_a254_frontSensorsVoltage m254 : 26|10@1+ (0.02,0) [0|0] "" Vector__XXX
 SG_ USM_a255_rearSensorsVoltage m255 : 26|10@1+ (0.02,0) [0|0] "" Vector__XXX
 SG_ USM_a021_Task1000msMissed m21 : 27|1@1+ (1,0) [0|0] "" Vector__XXX
 SG_ USM_a098_PT_temperature m98 : 27|1@1+ (1,0) [0|0] "" Vector__XXX
 SG_ USM_a104_PARTY_steeringControl m104 : 27|1@1+ (1,0) [0|0] "" Vector__XXX
 SG_ USM_a107_VEH_packConfig m107 : 27|1@1+ (1,0) [0|0] "" Vector__XXX
 SG_ USM_a108_PARTY_motorStatus m108 : 27|1@1+ (1,0) [0|0] "" Vector__XXX
 SG_ USM_a109_VEH_inertial1 m109 : 27|1@1+ (1,0) [0|0] "" Vector__XXX
 SG_ USM_a110_CH_carConfig m110 : 27|1@1+ (1,0) [0|0] "" Vector__XXX
 SG_ USM_a111_CH_status m111 : 27|1@1+ (1,0) [0|0] "" Vector__XXX
 SG_ USM_a113_VEH_powertrainControl m113 : 27|1@1+ (1,0) [0|0] "" Vector__XXX
 SG_ USM_a114_PARTY_offsets m114 : 27|1@1+ (1,0) [0|0] "" Vector__XXX
 SG_ USM_a116_VEH_switchStatus m116 : 27|1@1+ (1,0) [0|0] "" Vector__XXX
 SG_ USM_a117_VEH_doorStatus m117 : 27|1@1+ (1,0) [0|0] "" Vector__XXX
 SG_ USM_a118_PARTY_outputPowerStatus m118 : 27|1@1+ (1,0) [0|0] "" Vector__XXX
 SG_ USM_a120_PT_systemStatus m120 : 27|1@1+ (1,0) [0|0] "" Vector__XXX
 SG_ USM_a201_DSI2_UV m201 : 27|1@1+ (1,0) [0|0] "" Vector__XXX
 SG_ USM_a202_CE m202 : 27|1@1+ (1,0) [0|0] "" Vector__XXX
 SG_ USM_a227_vrefVoldOfOtpOutOfRange m227 : 27|1@1+ (1,0) [0|0] "" Vector__XXX
 SG_ USM_a228_vrefVoldOfOtpOutOfRange m228 : 27|1@1+ (1,0) [0|0] "" Vector__XXX
 SG_ USM_a229_vrefVoldOfOtpOutOfRange m229 : 27|1@1+ (1,0) [0|0] "" Vector__XXX
 SG_ USM_a230_vrefVoldOfOtpOutOfRange m230 : 27|1@1+ (1,0) [0|0] "" Vector__XXX
 SG_ USM_a231_vrefVoldOfOtpOutOfRange m231 : 27|1@1+ (1,0) [0|0] "" Vector__XXX
 SG_ USM_a232_vrefVoldOfOtpOutOfRange m232 : 27|1@1+ (1,0) [0|0] "" Vector__XXX
 SG_ USM_a233_vrefVoldOfOtpOutOfRange m233 : 27|1@1+ (1,0) [0|0] "" Vector__XXX
 SG_ USM_a234_vrefVoldOfOtpOutOfRange m234 : 27|1@1+ (1,0) [0|0] "" Vector__XXX
 SG_ USM_a235_vrefVoldOfOtpOutOfRange m235 : 27|1@1+ (1,0) [0|0] "" Vector__XXX
 SG_ USM_a236_vrefVoldOfOtpOutOfRange m236 : 27|1@1+ (1,0) [0|0] "" Vector__XXX
 SG_ USM_a237_vrefVoldOfOtpOutOfRange m237 : 27|1@1+ (1,0) [0|0] "" Vector__XXX
 SG_ USM_a238_vrefVoldOfOtpOutOfRange m238 : 27|1@1+ (1,0) [0|0] "" Vector__XXX
 SG_ USM_a240_vrefVoldOfOtpOutOfRange m240 : 27|1@1+ (1,0) [0|0] "" Vector__XXX
 SG_ USM_a241_vrefVoldOfOtpOutOfRange m241 : 27|1@1+ (1,0) [0|0] "" Vector__XXX
 SG_ USM_a242_vrefVoldOfOtpOutOfRange m242 : 27|1@1+ (1,0) [0|0] "" Vector__XXX
 SG_ USM_a243_vrefVoldOfOtpOutOfRange m243 : 27|1@1+ (1,0) [0|0] "" Vector__XXX
 SG_ USM_a244_vrefVoldOfOtpOutOfRange m244 : 27|1@1+ (1,0) [0|0] "" Vector__XXX
 SG_ USM_a245_vrefVoldOfOtpOutOfRange m245 : 27|1@1+ (1,0) [0|0] "" Vector__XXX
 SG_ USM_a246_vrefVoldOfOtpOutOfRange m246 : 27|1@1+ (1,0) [0|0] "" Vector__XXX
 SG_ USM_a247_vrefVoldOfOtpOutOfRange m247 : 27|1@1+ (1,0) [0|0] "" Vector__XXX
 SG_ USM_a248_vrefVoldOfOtpOutOfRange m248 : 27|1@1+ (1,0) [0|0] "" Vector__XXX
 SG_ USM_a249_vrefVoldOfOtpOutOfRange m249 : 27|1@1+ (1,0) [0|0] "" Vector__XXX
 SG_ USM_a250_vrefVoldOfOtpOutOfRange m250 : 27|1@1+ (1,0) [0|0] "" Vector__XXX
 SG_ USM_a251_vrefVoldOfOtpOutOfRange m251 : 27|1@1+ (1,0) [0|0] "" Vector__XXX
 SG_ USM_a058_current m58 : 28|11@1+ (0.1,0) [0|0] "" Vector__XXX
 SG_ USM_a059_resistanceEstimate m59 : 28|12@1+ (0.00244,0) [0|0] "" Vector__XXX
 SG_ USM_a098_PARTY_motorStatus m98 : 28|1@1+ (1,0) [0|0] "" Vector__XXX
 SG_ USM_a104_CH_steeringControl m104 : 28|1@1+ (1,0) [0|0] "" Vector__XXX
 SG_ USM_a107_VEH_energyStatus m107 : 28|1@1+ (1,0) [0|0] "" Vector__XXX
 SG_ USM_a108_VEH_motorStatus m108 : 28|1@1+ (1,0) [0|0] "" Vector__XXX
 SG_ USM_a109_VEH_inertial2 m109 : 28|1@1+ (1,0) [0|0] "" Vector__XXX
 SG_ USM_a110_CH_carState m110 : 28|1@1+ (1,0) [0|0] "" Vector__XXX
 SG_ USM_a113_VEH_vehicleModes m113 : 28|1@1+ (1,0) [0|0] "" Vector__XXX
 SG_ USM_a114_BDY_offsets m114 : 28|1@1+ (1,0) [0|0] "" Vector__XXX
 SG_ USM_a116_VEH_logging1Hz m116 : 28|1@1+ (1,0) [0|0] "" Vector__XXX
 SG_ USM_a117_VEH_doorStatus2 m117 : 28|1@1+ (1,0) [0|0] "" Vector__XXX
 SG_ USM_a118_PARTY_vehicleTime m118 : 28|1@1+ (1,0) [0|0] "" Vector__XXX
 SG_ USM_a120_PARTY_vehicleEstimates m120 : 28|1@1+ (1,0) [0|0] "" Vector__XXX
 SG_ USM_a201_DSI1_ND m201 : 28|1@1+ (1,0) [0|0] "" Vector__XXX
 SG_ USM_a227_eepromProgFail m227 : 28|1@1+ (1,0) [0|0] "" Vector__XXX
 SG_ USM_a228_eepromProgFail m228 : 28|1@1+ (1,0) [0|0] "" Vector__XXX
 SG_ USM_a229_eepromProgFail m229 : 28|1@1+ (1,0) [0|0] "" Vector__XXX
 SG_ USM_a230_eepromProgFail m230 : 28|1@1+ (1,0) [0|0] "" Vector__XXX
 SG_ USM_a231_eepromProgFail m231 : 28|1@1+ (1,0) [0|0] "" Vector__XXX
 SG_ USM_a232_eepromProgFail m232 : 28|1@1+ (1,0) [0|0] "" Vector__XXX
 SG_ USM_a233_eepromProgFail m233 : 28|1@1+ (1,0) [0|0] "" Vector__XXX
 SG_ USM_a234_eepromProgFail m234 : 28|1@1+ (1,0) [0|0] "" Vector__XXX
 SG_ USM_a235_eepromProgFail m235 : 28|1@1+ (1,0) [0|0] "" Vector__XXX
 SG_ USM_a236_eepromProgFail m236 : 28|1@1+ (1,0) [0|0] "" Vector__XXX
 SG_ USM_a237_eepromProgFail m237 : 28|1@1+ (1,0) [0|0] "" Vector__XXX
 SG_ USM_a238_eepromProgFail m238 : 28|1@1+ (1,0) [0|0] "" Vector__XXX
 SG_ USM_a240_eepromProgFail m240 : 28|1@1+ (1,0) [0|0] "" Vector__XXX
 SG_ USM_a241_eepromProgFail m241 : 28|1@1+ (1,0) [0|0] "" Vector__XXX
 SG_ USM_a242_eepromProgFail m242 : 28|1@1+ (1,0) [0|0] "" Vector__XXX
 SG_ USM_a243_eepromProgFail m243 : 28|1@1+ (1,0) [0|0] "" Vector__XXX
 SG_ USM_a244_eepromProgFail m244 : 28|1@1+ (1,0) [0|0] "" Vector__XXX
 SG_ USM_a245_eepromProgFail m245 : 28|1@1+ (1,0) [0|0] "" Vector__XXX
 SG_ USM_a246_eepromProgFail m246 : 28|1@1+ (1,0) [0|0] "" Vector__XXX
 SG_ USM_a247_eepromProgFail m247 : 28|1@1+ (1,0) [0|0] "" Vector__XXX
 SG_ USM_a248_eepromProgFail m248 : 28|1@1+ (1,0) [0|0] "" Vector__XXX
 SG_ USM_a249_eepromProgFail m249 : 28|1@1+ (1,0) [0|0] "" Vector__XXX
 SG_ USM_a250_eepromProgFail m250 : 28|1@1+ (1,0) [0|0] "" Vector__XXX
 SG_ USM_a251_eepromProgFail m251 : 28|1@1+ (1,0) [0|0] "" Vector__XXX
 SG_ USM_a098_VEH_motorStatus m98 : 29|1@1+ (1,0) [0|0] "" Vector__XXX
 SG_ USM_a104_VEH_steeringControl m104 : 29|1@1+ (1,0) [0|0] "" Vector__XXX
 SG_ USM_a107_VEH_chargeInfo m107 : 29|1@1+ (1,0) [0|0] "" Vector__XXX
 SG_ USM_a108_CH_torque m108 : 29|1@1+ (1,0) [0|0] "" Vector__XXX
 SG_ USM_a109_CH_inertial1 m109 : 29|1@1+ (1,0) [0|0] "" Vector__XXX
 SG_ USM_a110_CH_vin m110 : 29|1@1+ (1,0) [0|0] "" Vector__XXX
 SG_ USM_a113_VEH_driverProfileRecall m113 : 29|1@1+ (1,0) [0|0] "" Vector__XXX
 SG_ USM_a114_BDY_party3 m114 : 29|1@1+ (1,0) [0|0] "" Vector__XXX
 SG_ USM_a116_VEH_seatStatus2 m116 : 29|1@1+ (1,0) [0|0] "" Vector__XXX
 SG_ USM_a117_VEH_windowStatus m117 : 29|1@1+ (1,0) [0|0] "" Vector__XXX
 SG_ USM_a118_VEH_thermalCommand m118 : 29|1@1+ (1,0) [0|0] "" Vector__XXX
 SG_ USM_a120_VEH_aggregatedAxleSpeed m120 : 29|1@1+ (1,0) [0|0] "" Vector__XXX
 SG_ USM_a201_DSI2_ND m201 : 29|1@1+ (1,0) [0|0] "" Vector__XXX
 SG_ USM_a227_eepromProgBuys m227 : 29|1@1+ (1,0) [0|0] "" Vector__XXX
 SG_ USM_a228_eepromProgBuys m228 : 29|1@1+ (1,0) [0|0] "" Vector__XXX
 SG_ USM_a229_eepromProgBuys m229 : 29|1@1+ (1,0) [0|0] "" Vector__XXX
 SG_ USM_a230_eepromProgBuys m230 : 29|1@1+ (1,0) [0|0] "" Vector__XXX
 SG_ USM_a231_eepromProgBuys m231 : 29|1@1+ (1,0) [0|0] "" Vector__XXX
 SG_ USM_a232_eepromProgBuys m232 : 29|1@1+ (1,0) [0|0] "" Vector__XXX
 SG_ USM_a233_eepromProgBuys m233 : 29|1@1+ (1,0) [0|0] "" Vector__XXX
 SG_ USM_a234_eepromProgBuys m234 : 29|1@1+ (1,0) [0|0] "" Vector__XXX
 SG_ USM_a235_eepromProgBuys m235 : 29|1@1+ (1,0) [0|0] "" Vector__XXX
 SG_ USM_a236_eepromProgBuys m236 : 29|1@1+ (1,0) [0|0] "" Vector__XXX
 SG_ USM_a237_eepromProgBuys m237 : 29|1@1+ (1,0) [0|0] "" Vector__XXX
 SG_ USM_a238_eepromProgBuys m238 : 29|1@1+ (1,0) [0|0] "" Vector__XXX
 SG_ USM_a240_eepromProgBuys m240 : 29|1@1+ (1,0) [0|0] "" Vector__XXX
 SG_ USM_a241_eepromProgBuys m241 : 29|1@1+ (1,0) [0|0] "" Vector__XXX
 SG_ USM_a242_eepromProgBuys m242 : 29|1@1+ (1,0) [0|0] "" Vector__XXX
 SG_ USM_a243_eepromProgBuys m243 : 29|1@1+ (1,0) [0|0] "" Vector__XXX
 SG_ USM_a244_eepromProgBuys m244 : 29|1@1+ (1,0) [0|0] "" Vector__XXX
 SG_ USM_a245_eepromProgBuys m245 : 29|1@1+ (1,0) [0|0] "" Vector__XXX
 SG_ USM_a246_eepromProgBuys m246 : 29|1@1+ (1,0) [0|0] "" Vector__XXX
 SG_ USM_a247_eepromProgBuys m247 : 29|1@1+ (1,0) [0|0] "" Vector__XXX
 SG_ USM_a248_eepromProgBuys m248 : 29|1@1+ (1,0) [0|0] "" Vector__XXX
 SG_ USM_a249_eepromProgBuys m249 : 29|1@1+ (1,0) [0|0] "" Vector__XXX
 SG_ USM_a250_eepromProgBuys m250 : 29|1@1+ (1,0) [0|0] "" Vector__XXX
 SG_ USM_a251_eepromProgBuys m251 : 29|1@1+ (1,0) [0|0] "" Vector__XXX
 SG_ USM_a104_PARTY_integratedSafetyFront m104 : 30|1@1+ (1,0) [0|0] "" Vector__XXX
 SG_ USM_a109_CH_inertial2 m109 : 30|1@1+ (1,0) [0|0] "" Vector__XXX
 SG_ USM_a110_CH_chNm m110 : 30|1@1+ (1,0) [0|0] "" Vector__XXX
 SG_ USM_a113_VEH_driverProfileRecall2 m113 : 30|1@1+ (1,0) [0|0] "" Vector__XXX
 SG_ USM_a114_BDY_status m114 : 30|1@1+ (1,0) [0|0] "" Vector__XXX
 SG_ USM_a116_VEH_status m116 : 30|1@1+ (1,0) [0|0] "" Vector__XXX
 SG_ USM_a117_VEH_switchStatus m117 : 30|1@1+ (1,0) [0|0] "" Vector__XXX
 SG_ USM_a118_CH_LVPowerState m118 : 30|1@1+ (1,0) [0|0] "" Vector__XXX
 SG_ USM_a120_PARTY_aggregatedAxleSpeed m120 : 30|1@1+ (1,0) [0|0] "" Vector__XXX
 SG_ USM_a201_DSI1_OR m201 : 30|1@1+ (1,0) [0|0] "" Vector__XXX
 SG_ USM_a227_vsupVoltOutOfRange m227 : 30|1@1+ (1,0) [0|0] "" Vector__XXX
 SG_ USM_a228_vsupVoltOutOfRange m228 : 30|1@1+ (1,0) [0|0] "" Vector__XXX
 SG_ USM_a229_vsupVoltOutOfRange m229 : 30|1@1+ (1,0) [0|0] "" Vector__XXX
 SG_ USM_a230_vsupVoltOutOfRange m230 : 30|1@1+ (1,0) [0|0] "" Vector__XXX
 SG_ USM_a231_vsupVoltOutOfRange m231 : 30|1@1+ (1,0) [0|0] "" Vector__XXX
 SG_ USM_a232_vsupVoltOutOfRange m232 : 30|1@1+ (1,0) [0|0] "" Vector__XXX
 SG_ USM_a233_vsupVoltOutOfRange m233 : 30|1@1+ (1,0) [0|0] "" Vector__XXX
 SG_ USM_a234_vsupVoltOutOfRange m234 : 30|1@1+ (1,0) [0|0] "" Vector__XXX
 SG_ USM_a235_vsupVoltOutOfRange m235 : 30|1@1+ (1,0) [0|0] "" Vector__XXX
 SG_ USM_a236_vsupVoltOutOfRange m236 : 30|1@1+ (1,0) [0|0] "" Vector__XXX
 SG_ USM_a237_vsupVoltOutOfRange m237 : 30|1@1+ (1,0) [0|0] "" Vector__XXX
 SG_ USM_a238_vsupVoltOutOfRange m238 : 30|1@1+ (1,0) [0|0] "" Vector__XXX
 SG_ USM_a240_vsupVoltOutOfRange m240 : 30|1@1+ (1,0) [0|0] "" Vector__XXX
 SG_ USM_a241_vsupVoltOutOfRange m241 : 30|1@1+ (1,0) [0|0] "" Vector__XXX
 SG_ USM_a242_vsupVoltOutOfRange m242 : 30|1@1+ (1,0) [0|0] "" Vector__XXX
 SG_ USM_a243_vsupVoltOutOfRange m243 : 30|1@1+ (1,0) [0|0] "" Vector__XXX
 SG_ USM_a244_vsupVoltOutOfRange m244 : 30|1@1+ (1,0) [0|0] "" Vector__XXX
 SG_ USM_a245_vsupVoltOutOfRange m245 : 30|1@1+ (1,0) [0|0] "" Vector__XXX
 SG_ USM_a246_vsupVoltOutOfRange m246 : 30|1@1+ (1,0) [0|0] "" Vector__XXX
 SG_ USM_a247_vsupVoltOutOfRange m247 : 30|1@1+ (1,0) [0|0] "" Vector__XXX
 SG_ USM_a248_vsupVoltOutOfRange m248 : 30|1@1+ (1,0) [0|0] "" Vector__XXX
 SG_ USM_a249_vsupVoltOutOfRange m249 : 30|1@1+ (1,0) [0|0] "" Vector__XXX
 SG_ USM_a250_vsupVoltOutOfRange m250 : 30|1@1+ (1,0) [0|0] "" Vector__XXX
 SG_ USM_a251_vsupVoltOutOfRange m251 : 30|1@1+ (1,0) [0|0] "" Vector__XXX
 SG_ USM_a104_PARTY_matrixBendAngleRequest m104 : 31|1@1+ (1,0) [0|0] "" Vector__XXX
 SG_ USM_a109_CH_status m109 : 31|1@1+ (1,0) [0|0] "" Vector__XXX
 SG_ USM_a110_CH_epochTimeGtw m110 : 31|1@1+ (1,0) [0|0] "" Vector__XXX
 SG_ USM_a113_VEH_ventCntlReg m113 : 31|1@1+ (1,0) [0|0] "" Vector__XXX
 SG_ USM_a114_BDY_wheelRotation m114 : 31|1@1+ (1,0) [0|0] "" Vector__XXX
 SG_ USM_a116_VEH_thermalCommand m116 : 31|1@1+ (1,0) [0|0] "" Vector__XXX
 SG_ USM_a117_VEH_intrusionSensorStatus m117 : 31|1@1+ (1,0) [0|0] "" Vector__XXX
 SG_ USM_a118_PARTY_sensors m118 : 31|1@1+ (1,0) [0|0] "" Vector__XXX
 SG_ USM_a120_VEH_systemPower m120 : 31|1@1+ (1,0) [0|0] "" Vector__XXX
 SG_ USM_a201_DSI2_OR m201 : 31|1@1+ (1,0) [0|0] "" Vector__XXX
 SG_ USM_a227_tempSensOutOfRange m227 : 31|1@1+ (1,0) [0|0] "" Vector__XXX
 SG_ USM_a228_tempSensOutOfRange m228 : 31|1@1+ (1,0) [0|0] "" Vector__XXX
 SG_ USM_a229_tempSensOutOfRange m229 : 31|1@1+ (1,0) [0|0] "" Vector__XXX
 SG_ USM_a230_tempSensOutOfRange m230 : 31|1@1+ (1,0) [0|0] "" Vector__XXX
 SG_ USM_a231_tempSensOutOfRange m231 : 31|1@1+ (1,0) [0|0] "" Vector__XXX
 SG_ USM_a232_tempSensOutOfRange m232 : 31|1@1+ (1,0) [0|0] "" Vector__XXX
 SG_ USM_a233_tempSensOutOfRange m233 : 31|1@1+ (1,0) [0|0] "" Vector__XXX
 SG_ USM_a234_tempSensOutOfRange m234 : 31|1@1+ (1,0) [0|0] "" Vector__XXX
 SG_ USM_a235_tempSensOutOfRange m235 : 31|1@1+ (1,0) [0|0] "" Vector__XXX
 SG_ USM_a236_tempSensOutOfRange m236 : 31|1@1+ (1,0) [0|0] "" Vector__XXX
 SG_ USM_a237_tempSensOutOfRange m237 : 31|1@1+ (1,0) [0|0] "" Vector__XXX
 SG_ USM_a238_tempSensOutOfRange m238 : 31|1@1+ (1,0) [0|0] "" Vector__XXX
 SG_ USM_a240_tempSensOutOfRange m240 : 31|1@1+ (1,0) [0|0] "" Vector__XXX
 SG_ USM_a241_tempSensOutOfRange m241 : 31|1@1+ (1,0) [0|0] "" Vector__XXX
 SG_ USM_a242_tempSensOutOfRange m242 : 31|1@1+ (1,0) [0|0] "" Vector__XXX
 SG_ USM_a243_tempSensOutOfRange m243 : 31|1@1+ (1,0) [0|0] "" Vector__XXX
 SG_ USM_a244_tempSensOutOfRange m244 : 31|1@1+ (1,0) [0|0] "" Vector__XXX
 SG_ USM_a245_tempSensOutOfRange m245 : 31|1@1+ (1,0) [0|0] "" Vector__XXX
 SG_ USM_a246_tempSensOutOfRange m246 : 31|1@1+ (1,0) [0|0] "" Vector__XXX
 SG_ USM_a247_tempSensOutOfRange m247 : 31|1@1+ (1,0) [0|0] "" Vector__XXX
 SG_ USM_a248_tempSensOutOfRange m248 : 31|1@1+ (1,0) [0|0] "" Vector__XXX
 SG_ USM_a249_tempSensOutOfRange m249 : 31|1@1+ (1,0) [0|0] "" Vector__XXX
 SG_ USM_a250_tempSensOutOfRange m250 : 31|1@1+ (1,0) [0|0] "" Vector__XXX
 SG_ USM_a251_tempSensOutOfRange m251 : 31|1@1+ (1,0) [0|0] "" Vector__XXX
 SG_ USM_a000_alertDataW1 m0 : 32|16@1+ (1,0) [0|0] "" Vector__XXX
 SG_ USM_a003_LineNumber m3 : 32|16@1+ (1,0) [0|0] "" Vector__XXX
 SG_ USM_a005_busID1 m5 : 32|4@1+ (1,0) [0|0] "" Vector__XXX
 SG_ USM_a006_messageID m6 : 32|29@1+ (1,0) [0|0] "" Vector__XXX
 SG_ USM_a016_NVMMRecordNotFound m16 : 32|1@1+ (1,0) [0|0] "" Vector__XXX
 SG_ USM_a022_TaskInitError1 m22 : 32|8@1+ (1,0) [0|0] "" Vector__XXX
 SG_ USM_a031_uds_bytes_2 m31 : 32|8@1+ (1,0) [0|0] "" Vector__XXX
 SG_ USM_a041_CPULoad10msTask m41 : 32|8@1+ (1,0) [0|0] "" Vector__XXX
 SG_ USM_a042_Usage100msTask m42 : 32|8@1+ (1,0) [0|0] "" Vector__XXX
 SG_ USM_a063_ADCVoltage m63 : 32|8@1+ (0.025,0) [0|0] "" Vector__XXX
 SG_ USM_a104_VEH_matrixHighBeamRequest m104 : 32|1@1+ (1,0) [0|0] "" Vector__XXX
 SG_ USM_a110_PARTY_carConfig m110 : 32|1@1+ (1,0) [0|0] "" Vector__XXX
 SG_ USM_a113_VEH_debugECU m113 : 32|1@1+ (1,0) [0|0] "" Vector__XXX
 SG_ USM_a114_BDY_wheelSpeeds m114 : 32|1@1+ (1,0) [0|0] "" Vector__XXX
 SG_ USM_a116_VEH_windowStatus m116 : 32|1@1+ (1,0) [0|0] "" Vector__XXX
 SG_ USM_a117_VEH_liftgateStatus m117 : 32|1@1+ (1,0) [0|0] "" Vector__XXX
 SG_ USM_a118_CH_sensors m118 : 32|1@1+ (1,0) [0|0] "" Vector__XXX
 SG_ USM_a120_PARTY_autonomyHealth m120 : 32|1@1+ (1,0) [0|0] "" Vector__XXX
 SG_ USM_a177_rtmOffsetFromInit m177 : 32|1@1+ (1,0) [0|0] "" Vector__XXX
 SG_ USM_a178_rtmOffsetFromInit m178 : 32|1@1+ (1,0) [0|0] "" Vector__XXX
 SG_ USM_a179_rtmOffsetFromInit m179 : 32|1@1+ (1,0) [0|0] "" Vector__XXX
 SG_ USM_a180_rtmOffsetFromInit m180 : 32|1@1+ (1,0) [0|0] "" Vector__XXX
 SG_ USM_a181_rtmOffsetFromInit m181 : 32|1@1+ (1,0) [0|0] "" Vector__XXX
 SG_ USM_a182_rtmOffsetFromInit m182 : 32|1@1+ (1,0) [0|0] "" Vector__XXX
 SG_ USM_a183_rtmOffsetFromInit m183 : 32|1@1+ (1,0) [0|0] "" Vector__XXX
 SG_ USM_a184_rtmOffsetFromInit m184 : 32|1@1+ (1,0) [0|0] "" Vector__XXX
 SG_ USM_a185_rtmOffsetFromInit m185 : 32|1@1+ (1,0) [0|0] "" Vector__XXX
 SG_ USM_a186_rtmOffsetFromInit m186 : 32|1@1+ (1,0) [0|0] "" Vector__XXX
 SG_ USM_a187_rtmOffsetFromInit m187 : 32|1@1+ (1,0) [0|0] "" Vector__XXX
 SG_ USM_a188_rtmOffsetFromInit m188 : 32|1@1+ (1,0) [0|0] "" Vector__XXX
 SG_ USM_a201_DSI1_DL m201 : 32|1@1+ (1,0) [0|0] "" Vector__XXX
 SG_ USM_a203_ambientTemperature m203 : 32|8@1+ (0.5,-40) [0|0] "" Vector__XXX
 SG_ USM_a204_ambientTemperature m204 : 32|8@1+ (0.5,-40) [0|0] "" Vector__XXX
 SG_ USM_a205_ambientTemperature m205 : 32|8@1+ (0.5,-40) [0|0] "" Vector__XXX
 SG_ USM_a206_ambientTemperature m206 : 32|8@1+ (0.5,-40) [0|0] "" Vector__XXX
 SG_ USM_a207_ambientTemperature m207 : 32|8@1+ (0.5,-40) [0|0] "" Vector__XXX
 SG_ USM_a208_ambientTemperature m208 : 32|8@1+ (0.5,-40) [0|0] "" Vector__XXX
 SG_ USM_a209_ambientTemperature m209 : 32|8@1+ (0.5,-40) [0|0] "" Vector__XXX
 SG_ USM_a210_ambientTemperature m210 : 32|8@1+ (0.5,-40) [0|0] "" Vector__XXX
 SG_ USM_a211_ambientTemperature m211 : 32|8@1+ (0.5,-40) [0|0] "" Vector__XXX
 SG_ USM_a212_ambientTemperature m212 : 32|8@1+ (0.5,-40) [0|0] "" Vector__XXX
 SG_ USM_a213_ambientTemperature m213 : 32|8@1+ (0.5,-40) [0|0] "" Vector__XXX
 SG_ USM_a214_ambientTemperature m214 : 32|8@1+ (0.5,-40) [0|0] "" Vector__XXX
 SG_ USM_a227_underVoltAtVtankDuringBurst m227 : 32|1@1+ (1,0) [0|0] "" Vector__XXX
 SG_ USM_a228_underVoltAtVtankDuringBurst m228 : 32|1@1+ (1,0) [0|0] "" Vector__XXX
 SG_ USM_a229_underVoltAtVtankDuringBurst m229 : 32|1@1+ (1,0) [0|0] "" Vector__XXX
 SG_ USM_a230_underVoltAtVtankDuringBurst m230 : 32|1@1+ (1,0) [0|0] "" Vector__XXX
 SG_ USM_a231_underVoltAtVtankDuringBurst m231 : 32|1@1+ (1,0) [0|0] "" Vector__XXX
 SG_ USM_a232_underVoltAtVtankDuringBurst m232 : 32|1@1+ (1,0) [0|0] "" Vector__XXX
 SG_ USM_a233_underVoltAtVtankDuringBurst m233 : 32|1@1+ (1,0) [0|0] "" Vector__XXX
 SG_ USM_a234_underVoltAtVtankDuringBurst m234 : 32|1@1+ (1,0) [0|0] "" Vector__XXX
 SG_ USM_a235_underVoltAtVtankDuringBurst m235 : 32|1@1+ (1,0) [0|0] "" Vector__XXX
 SG_ USM_a236_underVoltAtVtankDuringBurst m236 : 32|1@1+ (1,0) [0|0] "" Vector__XXX
 SG_ USM_a237_underVoltAtVtankDuringBurst m237 : 32|1@1+ (1,0) [0|0] "" Vector__XXX
 SG_ USM_a238_underVoltAtVtankDuringBurst m238 : 32|1@1+ (1,0) [0|0] "" Vector__XXX
 SG_ USM_a240_underVoltAtVtankDuringBurst m240 : 32|1@1+ (1,0) [0|0] "" Vector__XXX
 SG_ USM_a241_underVoltAtVtankDuringBurst m241 : 32|1@1+ (1,0) [0|0] "" Vector__XXX
 SG_ USM_a242_underVoltAtVtankDuringBurst m242 : 32|1@1+ (1,0) [0|0] "" Vector__XXX
 SG_ USM_a243_underVoltAtVtankDuringBurst m243 : 32|1@1+ (1,0) [0|0] "" Vector__XXX
 SG_ USM_a244_underVoltAtVtankDuringBurst m244 : 32|1@1+ (1,0) [0|0] "" Vector__XXX
 SG_ USM_a245_underVoltAtVtankDuringBurst m245 : 32|1@1+ (1,0) [0|0] "" Vector__XXX
 SG_ USM_a246_underVoltAtVtankDuringBurst m246 : 32|1@1+ (1,0) [0|0] "" Vector__XXX
 SG_ USM_a247_underVoltAtVtankDuringBurst m247 : 32|1@1+ (1,0) [0|0] "" Vector__XXX
 SG_ USM_a248_underVoltAtVtankDuringBurst m248 : 32|1@1+ (1,0) [0|0] "" Vector__XXX
 SG_ USM_a249_underVoltAtVtankDuringBurst m249 : 32|1@1+ (1,0) [0|0] "" Vector__XXX
 SG_ USM_a250_underVoltAtVtankDuringBurst m250 : 32|1@1+ (1,0) [0|0] "" Vector__XXX
 SG_ USM_a251_underVoltAtVtankDuringBurst m251 : 32|1@1+ (1,0) [0|0] "" Vector__XXX
 SG_ USM_a016_NVMMCRCMismatch m16 : 33|1@1+ (1,0) [0|0] "" Vector__XXX
 SG_ USM_a104_VEH_summonCommand m104 : 33|1@1+ (1,0) [0|0] "" Vector__XXX
 SG_ USM_a113_VEH_status m113 : 33|1@1+ (1,0) [0|0] "" Vector__XXX
 SG_ USM_a114_CH_party1 m114 : 33|1@1+ (1,0) [0|0] "" Vector__XXX
 SG_ USM_a116_PARTY_restraintStatus m116 : 33|1@1+ (1,0) [0|0] "" Vector__XXX
 SG_ USM_a117_VEH_seatStatus2 m117 : 33|1@1+ (1,0) [0|0] "" Vector__XXX
 SG_ USM_a118_VEH_interNodeResistance m118 : 33|1@1+ (1,0) [0|0] "" Vector__XXX
 SG_ USM_a120_VEH_autonomyHealth m120 : 33|1@1+ (1,0) [0|0] "" Vector__XXX
 SG_ USM_a201_DSI2_DL m201 : 33|1@1+ (1,0) [0|0] "" Vector__XXX
 SG_ USM_a227_overVoltAtVtankDuringBurst m227 : 33|1@1+ (1,0) [0|0] "" Vector__XXX
 SG_ USM_a228_overVoltAtVtankDuringBurst m228 : 33|1@1+ (1,0) [0|0] "" Vector__XXX
 SG_ USM_a229_overVoltAtVtankDuringBurst m229 : 33|1@1+ (1,0) [0|0] "" Vector__XXX
 SG_ USM_a230_overVoltAtVtankDuringBurst m230 : 33|1@1+ (1,0) [0|0] "" Vector__XXX
 SG_ USM_a231_overVoltAtVtankDuringBurst m231 : 33|1@1+ (1,0) [0|0] "" Vector__XXX
 SG_ USM_a232_overVoltAtVtankDuringBurst m232 : 33|1@1+ (1,0) [0|0] "" Vector__XXX
 SG_ USM_a233_overVoltAtVtankDuringBurst m233 : 33|1@1+ (1,0) [0|0] "" Vector__XXX
 SG_ USM_a234_overVoltAtVtankDuringBurst m234 : 33|1@1+ (1,0) [0|0] "" Vector__XXX
 SG_ USM_a235_overVoltAtVtankDuringBurst m235 : 33|1@1+ (1,0) [0|0] "" Vector__XXX
 SG_ USM_a236_overVoltAtVtankDuringBurst m236 : 33|1@1+ (1,0) [0|0] "" Vector__XXX
 SG_ USM_a237_overVoltAtVtankDuringBurst m237 : 33|1@1+ (1,0) [0|0] "" Vector__XXX
 SG_ USM_a238_overVoltAtVtankDuringBurst m238 : 33|1@1+ (1,0) [0|0] "" Vector__XXX
 SG_ USM_a240_overVoltAtVtankDuringBurst m240 : 33|1@1+ (1,0) [0|0] "" Vector__XXX
 SG_ USM_a241_overVoltAtVtankDuringBurst m241 : 33|1@1+ (1,0) [0|0] "" Vector__XXX
 SG_ USM_a242_overVoltAtVtankDuringBurst m242 : 33|1@1+ (1,0) [0|0] "" Vector__XXX
 SG_ USM_a243_overVoltAtVtankDuringBurst m243 : 33|1@1+ (1,0) [0|0] "" Vector__XXX
 SG_ USM_a244_overVoltAtVtankDuringBurst m244 : 33|1@1+ (1,0) [0|0] "" Vector__XXX
 SG_ USM_a245_overVoltAtVtankDuringBurst m245 : 33|1@1+ (1,0) [0|0] "" Vector__XXX
 SG_ USM_a246_overVoltAtVtankDuringBurst m246 : 33|1@1+ (1,0) [0|0] "" Vector__XXX
 SG_ USM_a247_overVoltAtVtankDuringBurst m247 : 33|1@1+ (1,0) [0|0] "" Vector__XXX
 SG_ USM_a248_overVoltAtVtankDuringBurst m248 : 33|1@1+ (1,0) [0|0] "" Vector__XXX
 SG_ USM_a249_overVoltAtVtankDuringBurst m249 : 33|1@1+ (1,0) [0|0] "" Vector__XXX
 SG_ USM_a250_overVoltAtVtankDuringBurst m250 : 33|1@1+ (1,0) [0|0] "" Vector__XXX
 SG_ USM_a251_overVoltAtVtankDuringBurst m251 : 33|1@1+ (1,0) [0|0] "" Vector__XXX
 SG_ USM_a016_NVMMVersionMismatch m16 : 34|1@1+ (1,0) [0|0] "" Vector__XXX
 SG_ USM_a104_VEH_status m104 : 34|1@1+ (1,0) [0|0] "" Vector__XXX
 SG_ USM_a113_VEH_elevationStatus m113 : 34|1@1+ (1,0) [0|0] "" Vector__XXX
 SG_ USM_a114_CH_party3 m114 : 34|1@1+ (1,0) [0|0] "" Vector__XXX
 SG_ USM_a116_PARTY_doorStatus m116 : 34|1@1+ (1,0) [0|0] "" Vector__XXX
 SG_ USM_a117_PARTY_restraintStatus m117 : 34|1@1+ (1,0) [0|0] "" Vector__XXX
 SG_ USM_a118_CH_lighting m118 : 34|1@1+ (1,0) [0|0] "" Vector__XXX
 SG_ USM_a120_PT_systemPower m120 : 34|1@1+ (1,0) [0|0] "" Vector__XXX
 SG_ USM_a201_DSI1_PC m201 : 34|1@1+ (1,0) [0|0] "" Vector__XXX
 SG_ USM_a227_drvsFailDuringBurst m227 : 34|1@1+ (1,0) [0|0] "" Vector__XXX
 SG_ USM_a228_drvsFailDuringBurst m228 : 34|1@1+ (1,0) [0|0] "" Vector__XXX
 SG_ USM_a229_drvsFailDuringBurst m229 : 34|1@1+ (1,0) [0|0] "" Vector__XXX
 SG_ USM_a230_drvsFailDuringBurst m230 : 34|1@1+ (1,0) [0|0] "" Vector__XXX
 SG_ USM_a231_drvsFailDuringBurst m231 : 34|1@1+ (1,0) [0|0] "" Vector__XXX
 SG_ USM_a232_drvsFailDuringBurst m232 : 34|1@1+ (1,0) [0|0] "" Vector__XXX
 SG_ USM_a233_drvsFailDuringBurst m233 : 34|1@1+ (1,0) [0|0] "" Vector__XXX
 SG_ USM_a234_drvsFailDuringBurst m234 : 34|1@1+ (1,0) [0|0] "" Vector__XXX
 SG_ USM_a235_drvsFailDuringBurst m235 : 34|1@1+ (1,0) [0|0] "" Vector__XXX
 SG_ USM_a236_drvsFailDuringBurst m236 : 34|1@1+ (1,0) [0|0] "" Vector__XXX
 SG_ USM_a237_drvsFailDuringBurst m237 : 34|1@1+ (1,0) [0|0] "" Vector__XXX
 SG_ USM_a238_drvsFailDuringBurst m238 : 34|1@1+ (1,0) [0|0] "" Vector__XXX
 SG_ USM_a240_drvsFailDuringBurst m240 : 34|1@1+ (1,0) [0|0] "" Vector__XXX
 SG_ USM_a241_drvsFailDuringBurst m241 : 34|1@1+ (1,0) [0|0] "" Vector__XXX
 SG_ USM_a242_drvsFailDuringBurst m242 : 34|1@1+ (1,0) [0|0] "" Vector__XXX
 SG_ USM_a243_drvsFailDuringBurst m243 : 34|1@1+ (1,0) [0|0] "" Vector__XXX
 SG_ USM_a244_drvsFailDuringBurst m244 : 34|1@1+ (1,0) [0|0] "" Vector__XXX
 SG_ USM_a245_drvsFailDuringBurst m245 : 34|1@1+ (1,0) [0|0] "" Vector__XXX
 SG_ USM_a246_drvsFailDuringBurst m246 : 34|1@1+ (1,0) [0|0] "" Vector__XXX
 SG_ USM_a247_drvsFailDuringBurst m247 : 34|1@1+ (1,0) [0|0] "" Vector__XXX
 SG_ USM_a248_drvsFailDuringBurst m248 : 34|1@1+ (1,0) [0|0] "" Vector__XXX
 SG_ USM_a249_drvsFailDuringBurst m249 : 34|1@1+ (1,0) [0|0] "" Vector__XXX
 SG_ USM_a250_drvsFailDuringBurst m250 : 34|1@1+ (1,0) [0|0] "" Vector__XXX
 SG_ USM_a251_drvsFailDuringBurst m251 : 34|1@1+ (1,0) [0|0] "" Vector__XXX
 SG_ USM_a016_NVMMRecordUpgraded m16 : 35|1@1+ (1,0) [0|0] "" Vector__XXX
 SG_ USM_a104_CH_pscControl m104 : 35|1@1+ (1,0) [0|0] "" Vector__XXX
 SG_ USM_a113_VEH_LVControl m113 : 35|1@1+ (1,0) [0|0] "" Vector__XXX
 SG_ USM_a114_CH_status m114 : 35|1@1+ (1,0) [0|0] "" Vector__XXX
 SG_ USM_a116_BDY_epbmStatus m116 : 35|1@1+ (1,0) [0|0] "" Vector__XXX
 SG_ USM_a117_VEH_thermalStatus m117 : 35|1@1+ (1,0) [0|0] "" Vector__XXX
 SG_ USM_a118_VEH_lightStatus m118 : 35|1@1+ (1,0) [0|0] "" Vector__XXX
 SG_ USM_a120_PARTY_stalklessInterfaces m120 : 35|1@1+ (1,0) [0|0] "" Vector__XXX
 SG_ USM_a201_DSI2_PC m201 : 35|1@1+ (1,0) [0|0] "" Vector__XXX
 SG_ USM_a227_drv1FailDuringBurst m227 : 35|1@1+ (1,0) [0|0] "" Vector__XXX
 SG_ USM_a228_drv1FailDuringBurst m228 : 35|1@1+ (1,0) [0|0] "" Vector__XXX
 SG_ USM_a229_drv1FailDuringBurst m229 : 35|1@1+ (1,0) [0|0] "" Vector__XXX
 SG_ USM_a230_drv1FailDuringBurst m230 : 35|1@1+ (1,0) [0|0] "" Vector__XXX
 SG_ USM_a231_drv1FailDuringBurst m231 : 35|1@1+ (1,0) [0|0] "" Vector__XXX
 SG_ USM_a232_drv1FailDuringBurst m232 : 35|1@1+ (1,0) [0|0] "" Vector__XXX
 SG_ USM_a233_drv1FailDuringBurst m233 : 35|1@1+ (1,0) [0|0] "" Vector__XXX
 SG_ USM_a234_drv1FailDuringBurst m234 : 35|1@1+ (1,0) [0|0] "" Vector__XXX
 SG_ USM_a235_drv1FailDuringBurst m235 : 35|1@1+ (1,0) [0|0] "" Vector__XXX
 SG_ USM_a236_drv1FailDuringBurst m236 : 35|1@1+ (1,0) [0|0] "" Vector__XXX
 SG_ USM_a237_drv1FailDuringBurst m237 : 35|1@1+ (1,0) [0|0] "" Vector__XXX
 SG_ USM_a238_drv1FailDuringBurst m238 : 35|1@1+ (1,0) [0|0] "" Vector__XXX
 SG_ USM_a240_drv1FailDuringBurst m240 : 35|1@1+ (1,0) [0|0] "" Vector__XXX
 SG_ USM_a241_drv1FailDuringBurst m241 : 35|1@1+ (1,0) [0|0] "" Vector__XXX
 SG_ USM_a242_drv1FailDuringBurst m242 : 35|1@1+ (1,0) [0|0] "" Vector__XXX
 SG_ USM_a243_drv1FailDuringBurst m243 : 35|1@1+ (1,0) [0|0] "" Vector__XXX
 SG_ USM_a244_drv1FailDuringBurst m244 : 35|1@1+ (1,0) [0|0] "" Vector__XXX
 SG_ USM_a245_drv1FailDuringBurst m245 : 35|1@1+ (1,0) [0|0] "" Vector__XXX
 SG_ USM_a246_drv1FailDuringBurst m246 : 35|1@1+ (1,0) [0|0] "" Vector__XXX
 SG_ USM_a247_drv1FailDuringBurst m247 : 35|1@1+ (1,0) [0|0] "" Vector__XXX
 SG_ USM_a248_drv1FailDuringBurst m248 : 35|1@1+ (1,0) [0|0] "" Vector__XXX
 SG_ USM_a249_drv1FailDuringBurst m249 : 35|1@1+ (1,0) [0|0] "" Vector__XXX
 SG_ USM_a250_drv1FailDuringBurst m250 : 35|1@1+ (1,0) [0|0] "" Vector__XXX
 SG_ USM_a251_drv1FailDuringBurst m251 : 35|1@1+ (1,0) [0|0] "" Vector__XXX
 SG_ USM_a005_faults1 m5 : 36|12@1+ (1,0) [0|0] "" Vector__XXX
 SG_ USM_a016_NVMMMemOverflow m16 : 36|1@1+ (1,0) [0|0] "" Vector__XXX
 SG_ USM_a104_BDY_gpsAccuracies m104 : 36|1@1+ (1,0) [0|0] "" Vector__XXX
 SG_ USM_a113_CH_chassisControl m113 : 36|1@1+ (1,0) [0|0] "" Vector__XXX
 SG_ USM_a116_BDY_restraintStatus m116 : 36|1@1+ (1,0) [0|0] "" Vector__XXX
 SG_ USM_a117_PARTY_doorStatus m117 : 36|1@1+ (1,0) [0|0] "" Vector__XXX
 SG_ USM_a118_PARTY_vehNm m118 : 36|1@1+ (1,0) [0|0] "" Vector__XXX
 SG_ USM_a120_CH_speed m120 : 36|1@1+ (1,0) [0|0] "" Vector__XXX
 SG_ USM_a227_drv2FailDuringBurst m227 : 36|1@1+ (1,0) [0|0] "" Vector__XXX
 SG_ USM_a228_drv2FailDuringBurst m228 : 36|1@1+ (1,0) [0|0] "" Vector__XXX
 SG_ USM_a229_drv2FailDuringBurst m229 : 36|1@1+ (1,0) [0|0] "" Vector__XXX
 SG_ USM_a230_drv2FailDuringBurst m230 : 36|1@1+ (1,0) [0|0] "" Vector__XXX
 SG_ USM_a231_drv2FailDuringBurst m231 : 36|1@1+ (1,0) [0|0] "" Vector__XXX
 SG_ USM_a232_drv2FailDuringBurst m232 : 36|1@1+ (1,0) [0|0] "" Vector__XXX
 SG_ USM_a233_drv2FailDuringBurst m233 : 36|1@1+ (1,0) [0|0] "" Vector__XXX
 SG_ USM_a234_drv2FailDuringBurst m234 : 36|1@1+ (1,0) [0|0] "" Vector__XXX
 SG_ USM_a235_drv2FailDuringBurst m235 : 36|1@1+ (1,0) [0|0] "" Vector__XXX
 SG_ USM_a236_drv2FailDuringBurst m236 : 36|1@1+ (1,0) [0|0] "" Vector__XXX
 SG_ USM_a237_drv2FailDuringBurst m237 : 36|1@1+ (1,0) [0|0] "" Vector__XXX
 SG_ USM_a238_drv2FailDuringBurst m238 : 36|1@1+ (1,0) [0|0] "" Vector__XXX
 SG_ USM_a240_drv2FailDuringBurst m240 : 36|1@1+ (1,0) [0|0] "" Vector__XXX
 SG_ USM_a241_drv2FailDuringBurst m241 : 36|1@1+ (1,0) [0|0] "" Vector__XXX
 SG_ USM_a242_drv2FailDuringBurst m242 : 36|1@1+ (1,0) [0|0] "" Vector__XXX
 SG_ USM_a243_drv2FailDuringBurst m243 : 36|1@1+ (1,0) [0|0] "" Vector__XXX
 SG_ USM_a244_drv2FailDuringBurst m244 : 36|1@1+ (1,0) [0|0] "" Vector__XXX
 SG_ USM_a245_drv2FailDuringBurst m245 : 36|1@1+ (1,0) [0|0] "" Vector__XXX
 SG_ USM_a246_drv2FailDuringBurst m246 : 36|1@1+ (1,0) [0|0] "" Vector__XXX
 SG_ USM_a247_drv2FailDuringBurst m247 : 36|1@1+ (1,0) [0|0] "" Vector__XXX
 SG_ USM_a248_drv2FailDuringBurst m248 : 36|1@1+ (1,0) [0|0] "" Vector__XXX
 SG_ USM_a249_drv2FailDuringBurst m249 : 36|1@1+ (1,0) [0|0] "" Vector__XXX
 SG_ USM_a250_drv2FailDuringBurst m250 : 36|1@1+ (1,0) [0|0] "" Vector__XXX
 SG_ USM_a251_drv2FailDuringBurst m251 : 36|1@1+ (1,0) [0|0] "" Vector__XXX
 SG_ USM_a016_NVMMWriteFailed m16 : 37|1@1+ (1,0) [0|0] "" Vector__XXX
 SG_ USM_a104_BDY_control m104 : 37|1@1+ (1,0) [0|0] "" Vector__XXX
 SG_ USM_a113_CH_powertrainControl m113 : 37|1@1+ (1,0) [0|0] "" Vector__XXX
 SG_ USM_a116_BDY_switchStatus m116 : 37|1@1+ (1,0) [0|0] "" Vector__XXX
 SG_ USM_a117_VEH_status m117 : 37|1@1+ (1,0) [0|0] "" Vector__XXX
 SG_ USM_a118_CH_12VBatteryStatus m118 : 37|1@1+ (1,0) [0|0] "" Vector__XXX
 SG_ USM_a120_VEH_estimatedBrakeTemp m120 : 37|1@1+ (1,0) [0|0] "" Vector__XXX
 SG_ USM_a227_crcMismatchInRam m227 : 37|1@1+ (1,0) [0|0] "" Vector__XXX
 SG_ USM_a228_crcMismatchInRam m228 : 37|1@1+ (1,0) [0|0] "" Vector__XXX
 SG_ USM_a229_crcMismatchInRam m229 : 37|1@1+ (1,0) [0|0] "" Vector__XXX
 SG_ USM_a230_crcMismatchInRam m230 : 37|1@1+ (1,0) [0|0] "" Vector__XXX
 SG_ USM_a231_crcMismatchInRam m231 : 37|1@1+ (1,0) [0|0] "" Vector__XXX
 SG_ USM_a232_crcMismatchInRam m232 : 37|1@1+ (1,0) [0|0] "" Vector__XXX
 SG_ USM_a233_crcMismatchInRam m233 : 37|1@1+ (1,0) [0|0] "" Vector__XXX
 SG_ USM_a234_crcMismatchInRam m234 : 37|1@1+ (1,0) [0|0] "" Vector__XXX
 SG_ USM_a235_crcMismatchInRam m235 : 37|1@1+ (1,0) [0|0] "" Vector__XXX
 SG_ USM_a236_crcMismatchInRam m236 : 37|1@1+ (1,0) [0|0] "" Vector__XXX
 SG_ USM_a237_crcMismatchInRam m237 : 37|1@1+ (1,0) [0|0] "" Vector__XXX
 SG_ USM_a238_crcMismatchInRam m238 : 37|1@1+ (1,0) [0|0] "" Vector__XXX
 SG_ USM_a240_crcMismatchInRam m240 : 37|1@1+ (1,0) [0|0] "" Vector__XXX
 SG_ USM_a241_crcMismatchInRam m241 : 37|1@1+ (1,0) [0|0] "" Vector__XXX
 SG_ USM_a242_crcMismatchInRam m242 : 37|1@1+ (1,0) [0|0] "" Vector__XXX
 SG_ USM_a243_crcMismatchInRam m243 : 37|1@1+ (1,0) [0|0] "" Vector__XXX
 SG_ USM_a244_crcMismatchInRam m244 : 37|1@1+ (1,0) [0|0] "" Vector__XXX
 SG_ USM_a245_crcMismatchInRam m245 : 37|1@1+ (1,0) [0|0] "" Vector__XXX
 SG_ USM_a246_crcMismatchInRam m246 : 37|1@1+ (1,0) [0|0] "" Vector__XXX
 SG_ USM_a247_crcMismatchInRam m247 : 37|1@1+ (1,0) [0|0] "" Vector__XXX
 SG_ USM_a248_crcMismatchInRam m248 : 37|1@1+ (1,0) [0|0] "" Vector__XXX
 SG_ USM_a249_crcMismatchInRam m249 : 37|1@1+ (1,0) [0|0] "" Vector__XXX
 SG_ USM_a250_crcMismatchInRam m250 : 37|1@1+ (1,0) [0|0] "" Vector__XXX
 SG_ USM_a251_crcMismatchInRam m251 : 37|1@1+ (1,0) [0|0] "" Vector__XXX
 SG_ USM_a104_BDY_status m104 : 38|1@1+ (1,0) [0|0] "" Vector__XXX
 SG_ USM_a113_VEH_tripPlanning m113 : 38|1@1+ (1,0) [0|0] "" Vector__XXX
 SG_ USM_a117_PARTY_prndStatus m117 : 38|1@1+ (1,0) [0|0] "" Vector__XXX
 SG_ USM_a118_CH_LVBMS_statusHigh m118 : 38|1@1+ (1,0) [0|0] "" Vector__XXX
 SG_ USM_a120_PARTY_prndControl m120 : 38|1@1+ (1,0) [0|0] "" Vector__XXX
 SG_ USM_a227_verificationOfConfigAndCalcParamsFail m227 : 38|1@1+ (1,0) [0|0] "" Vector__XXX
 SG_ USM_a228_verificationOfConfigAndCalcParamsFail m228 : 38|1@1+ (1,0) [0|0] "" Vector__XXX
 SG_ USM_a229_verificationOfConfigAndCalcParamsFail m229 : 38|1@1+ (1,0) [0|0] "" Vector__XXX
 SG_ USM_a230_verificationOfConfigAndCalcParamsFail m230 : 38|1@1+ (1,0) [0|0] "" Vector__XXX
 SG_ USM_a231_verificationOfConfigAndCalcParamsFail m231 : 38|1@1+ (1,0) [0|0] "" Vector__XXX
 SG_ USM_a232_verificationOfConfigAndCalcParamsFail m232 : 38|1@1+ (1,0) [0|0] "" Vector__XXX
 SG_ USM_a233_verificationOfConfigAndCalcParamsFail m233 : 38|1@1+ (1,0) [0|0] "" Vector__XXX
 SG_ USM_a234_verificationOfConfigAndCalcParamsFail m234 : 38|1@1+ (1,0) [0|0] "" Vector__XXX
 SG_ USM_a235_verificationOfConfigAndCalcParamsFail m235 : 38|1@1+ (1,0) [0|0] "" Vector__XXX
 SG_ USM_a236_verificationOfConfigAndCalcParamsFail m236 : 38|1@1+ (1,0) [0|0] "" Vector__XXX
 SG_ USM_a237_verificationOfConfigAndCalcParamsFail m237 : 38|1@1+ (1,0) [0|0] "" Vector__XXX
 SG_ USM_a238_verificationOfConfigAndCalcParamsFail m238 : 38|1@1+ (1,0) [0|0] "" Vector__XXX
 SG_ USM_a240_verificationOfConfigAndCalcParamsFail m240 : 38|1@1+ (1,0) [0|0] "" Vector__XXX
 SG_ USM_a241_verificationOfConfigAndCalcParamsFail m241 : 38|1@1+ (1,0) [0|0] "" Vector__XXX
 SG_ USM_a242_verificationOfConfigAndCalcParamsFail m242 : 38|1@1+ (1,0) [0|0] "" Vector__XXX
 SG_ USM_a243_verificationOfConfigAndCalcParamsFail m243 : 38|1@1+ (1,0) [0|0] "" Vector__XXX
 SG_ USM_a244_verificationOfConfigAndCalcParamsFail m244 : 38|1@1+ (1,0) [0|0] "" Vector__XXX
 SG_ USM_a245_verificationOfConfigAndCalcParamsFail m245 : 38|1@1+ (1,0) [0|0] "" Vector__XXX
 SG_ USM_a246_verificationOfConfigAndCalcParamsFail m246 : 38|1@1+ (1,0) [0|0] "" Vector__XXX
 SG_ USM_a247_verificationOfConfigAndCalcParamsFail m247 : 38|1@1+ (1,0) [0|0] "" Vector__XXX
 SG_ USM_a248_verificationOfConfigAndCalcParamsFail m248 : 38|1@1+ (1,0) [0|0] "" Vector__XXX
 SG_ USM_a249_verificationOfConfigAndCalcParamsFail m249 : 38|1@1+ (1,0) [0|0] "" Vector__XXX
 SG_ USM_a250_verificationOfConfigAndCalcParamsFail m250 : 38|1@1+ (1,0) [0|0] "" Vector__XXX
 SG_ USM_a251_verificationOfConfigAndCalcParamsFail m251 : 38|1@1+ (1,0) [0|0] "" Vector__XXX
 SG_ USM_a058_prevREstimate m58 : 39|12@1+ (0.00061,0) [0|0] "" Vector__XXX
 SG_ USM_a104_PARTY_autonomyControl m104 : 39|1@1+ (1,0) [0|0] "" Vector__XXX
 SG_ USM_a113_VEH_vehicleControl3 m113 : 39|1@1+ (1,0) [0|0] "" Vector__XXX
 SG_ USM_a117_PARTY_lightingSecondary m117 : 39|1@1+ (1,0) [0|0] "" Vector__XXX
 SG_ USM_a118_CH_alertMatrix m118 : 39|1@1+ (1,0) [0|0] "" Vector__XXX
 SG_ USM_a120_PARTY_locStatus2 m120 : 39|1@1+ (1,0) [0|0] "" Vector__XXX
 SG_ USM_a227_wdgClockFreqOutOfRange m227 : 39|1@1+ (1,0) [0|0] "" Vector__XXX
 SG_ USM_a228_wdgClockFreqOutOfRange m228 : 39|1@1+ (1,0) [0|0] "" Vector__XXX
 SG_ USM_a229_wdgClockFreqOutOfRange m229 : 39|1@1+ (1,0) [0|0] "" Vector__XXX
 SG_ USM_a230_wdgClockFreqOutOfRange m230 : 39|1@1+ (1,0) [0|0] "" Vector__XXX
 SG_ USM_a231_wdgClockFreqOutOfRange m231 : 39|1@1+ (1,0) [0|0] "" Vector__XXX
 SG_ USM_a232_wdgClockFreqOutOfRange m232 : 39|1@1+ (1,0) [0|0] "" Vector__XXX
 SG_ USM_a233_wdgClockFreqOutOfRange m233 : 39|1@1+ (1,0) [0|0] "" Vector__XXX
 SG_ USM_a234_wdgClockFreqOutOfRange m234 : 39|1@1+ (1,0) [0|0] "" Vector__XXX
 SG_ USM_a235_wdgClockFreqOutOfRange m235 : 39|1@1+ (1,0) [0|0] "" Vector__XXX
 SG_ USM_a236_wdgClockFreqOutOfRange m236 : 39|1@1+ (1,0) [0|0] "" Vector__XXX
 SG_ USM_a237_wdgClockFreqOutOfRange m237 : 39|1@1+ (1,0) [0|0] "" Vector__XXX
 SG_ USM_a238_wdgClockFreqOutOfRange m238 : 39|1@1+ (1,0) [0|0] "" Vector__XXX
 SG_ USM_a240_wdgClockFreqOutOfRange m240 : 39|1@1+ (1,0) [0|0] "" Vector__XXX
 SG_ USM_a241_wdgClockFreqOutOfRange m241 : 39|1@1+ (1,0) [0|0] "" Vector__XXX
 SG_ USM_a242_wdgClockFreqOutOfRange m242 : 39|1@1+ (1,0) [0|0] "" Vector__XXX
 SG_ USM_a243_wdgClockFreqOutOfRange m243 : 39|1@1+ (1,0) [0|0] "" Vector__XXX
 SG_ USM_a244_wdgClockFreqOutOfRange m244 : 39|1@1+ (1,0) [0|0] "" Vector__XXX
 SG_ USM_a245_wdgClockFreqOutOfRange m245 : 39|1@1+ (1,0) [0|0] "" Vector__XXX
 SG_ USM_a246_wdgClockFreqOutOfRange m246 : 39|1@1+ (1,0) [0|0] "" Vector__XXX
 SG_ USM_a247_wdgClockFreqOutOfRange m247 : 39|1@1+ (1,0) [0|0] "" Vector__XXX
 SG_ USM_a248_wdgClockFreqOutOfRange m248 : 39|1@1+ (1,0) [0|0] "" Vector__XXX
 SG_ USM_a249_wdgClockFreqOutOfRange m249 : 39|1@1+ (1,0) [0|0] "" Vector__XXX
 SG_ USM_a250_wdgClockFreqOutOfRange m250 : 39|1@1+ (1,0) [0|0] "" Vector__XXX
 SG_ USM_a251_wdgClockFreqOutOfRange m251 : 39|1@1+ (1,0) [0|0] "" Vector__XXX
 SG_ USM_a022_TaskInitError2 m22 : 40|8@1+ (1,0) [0|0] "" Vector__XXX
 SG_ USM_a031_uds_bytes_3 m31 : 40|8@1+ (1,0) [0|0] "" Vector__XXX
 SG_ USM_a041_CPULoad100msTask m41 : 40|8@1+ (1,0) [0|0] "" Vector__XXX
 SG_ USM_a042_Usage1000msTask m42 : 40|8@1+ (1,0) [0|0] "" Vector__XXX
 SG_ USM_a043_CallTrace1 m43 : 40|24@1+ (1,0) [0|0] "" Vector__XXX
 SG_ USM_a044_CallTrace1 m44 : 40|24@1+ (1,0) [0|0] "" Vector__XXX
 SG_ USM_a045_CallTrace1 m45 : 40|24@1+ (1,0) [0|0] "" Vector__XXX
 SG_ USM_a046_CallTrace1 m46 : 40|24@1+ (1,0) [0|0] "" Vector__XXX
 SG_ USM_a059_current m59 : 40|12@1+ (0.05,0) [0|0] "" Vector__XXX
 SG_ USM_a063_disconnected m63 : 40|1@1+ (1,0) [0|0] "" Vector__XXX
 SG_ USM_a104_VEH_autonomyControl m104 : 40|1@1+ (1,0) [0|0] "" Vector__XXX
 SG_ USM_a113_VEH_vehicleControlThermal m113 : 40|1@1+ (1,0) [0|0] "" Vector__XXX
 SG_ USM_a118_BDY_outputPowerStatus m118 : 40|1@1+ (1,0) [0|0] "" Vector__XXX
 SG_ USM_a120_VEH_chassisCntl m120 : 40|1@1+ (1,0) [0|0] "" Vector__XXX
 SG_ USM_a131_timeSincePwrStateTransition m131 : 40|16@1+ (1,0) [0|0] "" Vector__XXX
 SG_ USM_a132_timeSincePwrStateTransition m132 : 40|16@1+ (1,0) [0|0] "" Vector__XXX
 SG_ USM_a133_timeSincePwrStateTransition m133 : 40|16@1+ (1,0) [0|0] "" Vector__XXX
 SG_ USM_a134_timeSincePwrStateTransition m134 : 40|16@1+ (1,0) [0|0] "" Vector__XXX
 SG_ USM_a135_timeSincePwrStateTransition m135 : 40|16@1+ (1,0) [0|0] "" Vector__XXX
 SG_ USM_a136_timeSincePwrStateTransition m136 : 40|16@1+ (1,0) [0|0] "" Vector__XXX
 SG_ USM_a137_timeSincePwrStateTransition m137 : 40|16@1+ (1,0) [0|0] "" Vector__XXX
 SG_ USM_a138_timeSincePwrStateTransition m138 : 40|16@1+ (1,0) [0|0] "" Vector__XXX
 SG_ USM_a139_timeSincePwrStateTransition m139 : 40|16@1+ (1,0) [0|0] "" Vector__XXX
 SG_ USM_a140_timeSincePwrStateTransition m140 : 40|16@1+ (1,0) [0|0] "" Vector__XXX
 SG_ USM_a141_timeSincePwrStateTransition m141 : 40|16@1+ (1,0) [0|0] "" Vector__XXX
 SG_ USM_a142_timeSincePwrStateTransition m142 : 40|16@1+ (1,0) [0|0] "" Vector__XXX
 SG_ USM_a143_timeSincePwrStateTransition m143 : 40|16@1+ (1,0) [0|0] "" Vector__XXX
 SG_ USM_a144_timeSincePwrStateTransition m144 : 40|16@1+ (1,0) [0|0] "" Vector__XXX
 SG_ USM_a145_timeSincePwrStateTransition m145 : 40|16@1+ (1,0) [0|0] "" Vector__XXX
 SG_ USM_a146_timeSincePwrStateTransition m146 : 40|16@1+ (1,0) [0|0] "" Vector__XXX
 SG_ USM_a147_timeSincePwrStateTransition m147 : 40|16@1+ (1,0) [0|0] "" Vector__XXX
 SG_ USM_a148_timeSincePwrStateTransition m148 : 40|16@1+ (1,0) [0|0] "" Vector__XXX
 SG_ USM_a149_timeSincePwrStateTransition m149 : 40|16@1+ (1,0) [0|0] "" Vector__XXX
 SG_ USM_a150_timeSincePwrStateTransition m150 : 40|16@1+ (1,0) [0|0] "" Vector__XXX
 SG_ USM_a151_timeSincePwrStateTransition m151 : 40|16@1+ (1,0) [0|0] "" Vector__XXX
 SG_ USM_a152_timeSincePwrStateTransition m152 : 40|16@1+ (1,0) [0|0] "" Vector__XXX
 SG_ USM_a153_timeSincePwrStateTransition m153 : 40|16@1+ (1,0) [0|0] "" Vector__XXX
 SG_ USM_a154_timeSincePwrStateTransition m154 : 40|16@1+ (1,0) [0|0] "" Vector__XXX
 SG_ USM_a177_ambientTemperature m177 : 40|8@1+ (0.5,-40) [0|0] "" Vector__XXX
 SG_ USM_a178_ambientTemperature m178 : 40|8@1+ (0.5,-40) [0|0] "" Vector__XXX
 SG_ USM_a179_ambientTemperature m179 : 40|8@1+ (0.5,-40) [0|0] "" Vector__XXX
 SG_ USM_a180_ambientTemperature m180 : 40|8@1+ (0.5,-40) [0|0] "" Vector__XXX
 SG_ USM_a181_ambientTemperature m181 : 40|8@1+ (0.5,-40) [0|0] "" Vector__XXX
 SG_ USM_a182_ambientTemperature m182 : 40|8@1+ (0.5,-40) [0|0] "" Vector__XXX
 SG_ USM_a183_ambientTemperature m183 : 40|8@1+ (0.5,-40) [0|0] "" Vector__XXX
 SG_ USM_a184_ambientTemperature m184 : 40|8@1+ (0.5,-40) [0|0] "" Vector__XXX
 SG_ USM_a185_ambientTemperature m185 : 40|8@1+ (0.5,-40) [0|0] "" Vector__XXX
 SG_ USM_a186_ambientTemperature m186 : 40|8@1+ (0.5,-40) [0|0] "" Vector__XXX
 SG_ USM_a187_ambientTemperature m187 : 40|8@1+ (0.5,-40) [0|0] "" Vector__XXX
 SG_ USM_a188_ambientTemperature m188 : 40|8@1+ (0.5,-40) [0|0] "" Vector__XXX
 SG_ USM_a203_sensorTemperature m203 : 40|8@1- (1,33) [0|0] "" Vector__XXX
 SG_ USM_a204_sensorTemperature m204 : 40|8@1- (1,33) [0|0] "" Vector__XXX
 SG_ USM_a205_sensorTemperature m205 : 40|8@1- (1,33) [0|0] "" Vector__XXX
 SG_ USM_a206_sensorTemperature m206 : 40|8@1- (1,33) [0|0] "" Vector__XXX
 SG_ USM_a207_sensorTemperature m207 : 40|8@1- (1,33) [0|0] "" Vector__XXX
 SG_ USM_a208_sensorTemperature m208 : 40|8@1- (1,33) [0|0] "" Vector__XXX
 SG_ USM_a209_sensorTemperature m209 : 40|8@1- (1,33) [0|0] "" Vector__XXX
 SG_ USM_a210_sensorTemperature m210 : 40|8@1- (1,33) [0|0] "" Vector__XXX
 SG_ USM_a211_sensorTemperature m211 : 40|8@1- (1,33) [0|0] "" Vector__XXX
 SG_ USM_a212_sensorTemperature m212 : 40|8@1- (1,33) [0|0] "" Vector__XXX
 SG_ USM_a213_sensorTemperature m213 : 40|8@1- (1,33) [0|0] "" Vector__XXX
 SG_ USM_a214_sensorTemperature m214 : 40|8@1- (1,33) [0|0] "" Vector__XXX
 SG_ USM_a227_atgNoiseMeasOutOfRange m227 : 40|1@1+ (1,0) [0|0] "" Vector__XXX
 SG_ USM_a228_atgNoiseMeasOutOfRange m228 : 40|1@1+ (1,0) [0|0] "" Vector__XXX
 SG_ USM_a229_atgNoiseMeasOutOfRange m229 : 40|1@1+ (1,0) [0|0] "" Vector__XXX
 SG_ USM_a230_atgNoiseMeasOutOfRange m230 : 40|1@1+ (1,0) [0|0] "" Vector__XXX
 SG_ USM_a231_atgNoiseMeasOutOfRange m231 : 40|1@1+ (1,0) [0|0] "" Vector__XXX
 SG_ USM_a232_atgNoiseMeasOutOfRange m232 : 40|1@1+ (1,0) [0|0] "" Vector__XXX
 SG_ USM_a233_atgNoiseMeasOutOfRange m233 : 40|1@1+ (1,0) [0|0] "" Vector__XXX
 SG_ USM_a234_atgNoiseMeasOutOfRange m234 : 40|1@1+ (1,0) [0|0] "" Vector__XXX
 SG_ USM_a235_atgNoiseMeasOutOfRange m235 : 40|1@1+ (1,0) [0|0] "" Vector__XXX
 SG_ USM_a236_atgNoiseMeasOutOfRange m236 : 40|1@1+ (1,0) [0|0] "" Vector__XXX
 SG_ USM_a237_atgNoiseMeasOutOfRange m237 : 40|1@1+ (1,0) [0|0] "" Vector__XXX
 SG_ USM_a238_atgNoiseMeasOutOfRange m238 : 40|1@1+ (1,0) [0|0] "" Vector__XXX
 SG_ USM_a240_atgNoiseMeasOutOfRange m240 : 40|1@1+ (1,0) [0|0] "" Vector__XXX
 SG_ USM_a241_atgNoiseMeasOutOfRange m241 : 40|1@1+ (1,0) [0|0] "" Vector__XXX
 SG_ USM_a242_atgNoiseMeasOutOfRange m242 : 40|1@1+ (1,0) [0|0] "" Vector__XXX
 SG_ USM_a243_atgNoiseMeasOutOfRange m243 : 40|1@1+ (1,0) [0|0] "" Vector__XXX
 SG_ USM_a244_atgNoiseMeasOutOfRange m244 : 40|1@1+ (1,0) [0|0] "" Vector__XXX
 SG_ USM_a245_atgNoiseMeasOutOfRange m245 : 40|1@1+ (1,0) [0|0] "" Vector__XXX
 SG_ USM_a246_atgNoiseMeasOutOfRange m246 : 40|1@1+ (1,0) [0|0] "" Vector__XXX
 SG_ USM_a247_atgNoiseMeasOutOfRange m247 : 40|1@1+ (1,0) [0|0] "" Vector__XXX
 SG_ USM_a248_atgNoiseMeasOutOfRange m248 : 40|1@1+ (1,0) [0|0] "" Vector__XXX
 SG_ USM_a249_atgNoiseMeasOutOfRange m249 : 40|1@1+ (1,0) [0|0] "" Vector__XXX
 SG_ USM_a250_atgNoiseMeasOutOfRange m250 : 40|1@1+ (1,0) [0|0] "" Vector__XXX
 SG_ USM_a251_atgNoiseMeasOutOfRange m251 : 40|1@1+ (1,0) [0|0] "" Vector__XXX
 SG_ USM_a254_ambientTemperature m254 : 40|8@1+ (0.5,-40) [0|0] "" Vector__XXX
 SG_ USM_a255_ambientTemperature m255 : 40|8@1+ (0.5,-40) [0|0] "" Vector__XXX
 SG_ USM_a063_indeterminate m63 : 41|1@1+ (1,0) [0|0] "" Vector__XXX
 SG_ USM_a104_CH_autonomyControl m104 : 41|1@1+ (1,0) [0|0] "" Vector__XXX
 SG_ USM_a113_CH_odo m113 : 41|1@1+ (1,0) [0|0] "" Vector__XXX
 SG_ USM_a118_BDY_vehicleTime m118 : 41|1@1+ (1,0) [0|0] "" Vector__XXX
 SG_ USM_a120_CH_locStatus2 m120 : 41|1@1+ (1,0) [0|0] "" Vector__XXX
 SG_ USM_a227_syncCountError m227 : 41|1@1+ (1,0) [0|0] "" Vector__XXX
 SG_ USM_a228_syncCountError m228 : 41|1@1+ (1,0) [0|0] "" Vector__XXX
 SG_ USM_a229_syncCountError m229 : 41|1@1+ (1,0) [0|0] "" Vector__XXX
 SG_ USM_a230_syncCountError m230 : 41|1@1+ (1,0) [0|0] "" Vector__XXX
 SG_ USM_a231_syncCountError m231 : 41|1@1+ (1,0) [0|0] "" Vector__XXX
 SG_ USM_a232_syncCountError m232 : 41|1@1+ (1,0) [0|0] "" Vector__XXX
 SG_ USM_a233_syncCountError m233 : 41|1@1+ (1,0) [0|0] "" Vector__XXX
 SG_ USM_a234_syncCountError m234 : 41|1@1+ (1,0) [0|0] "" Vector__XXX
 SG_ USM_a235_syncCountError m235 : 41|1@1+ (1,0) [0|0] "" Vector__XXX
 SG_ USM_a236_syncCountError m236 : 41|1@1+ (1,0) [0|0] "" Vector__XXX
 SG_ USM_a237_syncCountError m237 : 41|1@1+ (1,0) [0|0] "" Vector__XXX
 SG_ USM_a238_syncCountError m238 : 41|1@1+ (1,0) [0|0] "" Vector__XXX
 SG_ USM_a240_syncCountError m240 : 41|1@1+ (1,0) [0|0] "" Vector__XXX
 SG_ USM_a241_syncCountError m241 : 41|1@1+ (1,0) [0|0] "" Vector__XXX
 SG_ USM_a242_syncCountError m242 : 41|1@1+ (1,0) [0|0] "" Vector__XXX
 SG_ USM_a243_syncCountError m243 : 41|1@1+ (1,0) [0|0] "" Vector__XXX
 SG_ USM_a244_syncCountError m244 : 41|1@1+ (1,0) [0|0] "" Vector__XXX
 SG_ USM_a245_syncCountError m245 : 41|1@1+ (1,0) [0|0] "" Vector__XXX
 SG_ USM_a246_syncCountError m246 : 41|1@1+ (1,0) [0|0] "" Vector__XXX
 SG_ USM_a247_syncCountError m247 : 41|1@1+ (1,0) [0|0] "" Vector__XXX
 SG_ USM_a248_syncCountError m248 : 41|1@1+ (1,0) [0|0] "" Vector__XXX
 SG_ USM_a249_syncCountError m249 : 41|1@1+ (1,0) [0|0] "" Vector__XXX
 SG_ USM_a250_syncCountError m250 : 41|1@1+ (1,0) [0|0] "" Vector__XXX
 SG_ USM_a251_syncCountError m251 : 41|1@1+ (1,0) [0|0] "" Vector__XXX
 SG_ USM_a063_stuckActive m63 : 42|1@1+ (1,0) [0|0] "" Vector__XXX
 SG_ USM_a104_BDY_autonomyControl m104 : 42|1@1+ (1,0) [0|0] "" Vector__XXX
 SG_ USM_a113_VEH_locationStatus m113 : 42|1@1+ (1,0) [0|0] "" Vector__XXX
 SG_ USM_a118_PARTY_AP_vehicleState1HzMuxed m118 : 42|1@1+ (1,0) [0|0] "" Vector__XXX
 SG_ USM_a120_VEH_locStatus m120 : 42|1@1+ (1,0) [0|0] "" Vector__XXX
 SG_ USM_a227_invalidStartEdge m227 : 42|1@1+ (1,0) [0|0] "" Vector__XXX
 SG_ USM_a228_invalidStartEdge m228 : 42|1@1+ (1,0) [0|0] "" Vector__XXX
 SG_ USM_a229_invalidStartEdge m229 : 42|1@1+ (1,0) [0|0] "" Vector__XXX
 SG_ USM_a230_invalidStartEdge m230 : 42|1@1+ (1,0) [0|0] "" Vector__XXX
 SG_ USM_a231_invalidStartEdge m231 : 42|1@1+ (1,0) [0|0] "" Vector__XXX
 SG_ USM_a232_invalidStartEdge m232 : 42|1@1+ (1,0) [0|0] "" Vector__XXX
 SG_ USM_a233_invalidStartEdge m233 : 42|1@1+ (1,0) [0|0] "" Vector__XXX
 SG_ USM_a234_invalidStartEdge m234 : 42|1@1+ (1,0) [0|0] "" Vector__XXX
 SG_ USM_a235_invalidStartEdge m235 : 42|1@1+ (1,0) [0|0] "" Vector__XXX
 SG_ USM_a236_invalidStartEdge m236 : 42|1@1+ (1,0) [0|0] "" Vector__XXX
 SG_ USM_a237_invalidStartEdge m237 : 42|1@1+ (1,0) [0|0] "" Vector__XXX
 SG_ USM_a238_invalidStartEdge m238 : 42|1@1+ (1,0) [0|0] "" Vector__XXX
 SG_ USM_a240_invalidStartEdge m240 : 42|1@1+ (1,0) [0|0] "" Vector__XXX
 SG_ USM_a241_invalidStartEdge m241 : 42|1@1+ (1,0) [0|0] "" Vector__XXX
 SG_ USM_a242_invalidStartEdge m242 : 42|1@1+ (1,0) [0|0] "" Vector__XXX
 SG_ USM_a243_invalidStartEdge m243 : 42|1@1+ (1,0) [0|0] "" Vector__XXX
 SG_ USM_a244_invalidStartEdge m244 : 42|1@1+ (1,0) [0|0] "" Vector__XXX
 SG_ USM_a245_invalidStartEdge m245 : 42|1@1+ (1,0) [0|0] "" Vector__XXX
 SG_ USM_a246_invalidStartEdge m246 : 42|1@1+ (1,0) [0|0] "" Vector__XXX
 SG_ USM_a247_invalidStartEdge m247 : 42|1@1+ (1,0) [0|0] "" Vector__XXX
 SG_ USM_a248_invalidStartEdge m248 : 42|1@1+ (1,0) [0|0] "" Vector__XXX
 SG_ USM_a249_invalidStartEdge m249 : 42|1@1+ (1,0) [0|0] "" Vector__XXX
 SG_ USM_a250_invalidStartEdge m250 : 42|1@1+ (1,0) [0|0] "" Vector__XXX
 SG_ USM_a251_invalidStartEdge m251 : 42|1@1+ (1,0) [0|0] "" Vector__XXX
 SG_ USM_a063_faulted m63 : 43|1@1+ (1,0) [0|0] "" Vector__XXX
 SG_ USM_a104_VEH_wirelessChargingStatus m104 : 43|1@1+ (1,0) [0|0] "" Vector__XXX
 SG_ USM_a113_VEH_gpsTime m113 : 43|1@1+ (1,0) [0|0] "" Vector__XXX
 SG_ USM_a118_BDY_AP_vehicleState1HzMuxed m118 : 43|1@1+ (1,0) [0|0] "" Vector__XXX
 SG_ USM_a120_VEH_locStatus2 m120 : 43|1@1+ (1,0) [0|0] "" Vector__XXX
 SG_ USM_a227_receiverReachedErrorState m227 : 43|1@1+ (1,0) [0|0] "" Vector__XXX
 SG_ USM_a228_receiverReachedErrorState m228 : 43|1@1+ (1,0) [0|0] "" Vector__XXX
 SG_ USM_a229_receiverReachedErrorState m229 : 43|1@1+ (1,0) [0|0] "" Vector__XXX
 SG_ USM_a230_receiverReachedErrorState m230 : 43|1@1+ (1,0) [0|0] "" Vector__XXX
 SG_ USM_a231_receiverReachedErrorState m231 : 43|1@1+ (1,0) [0|0] "" Vector__XXX
 SG_ USM_a232_receiverReachedErrorState m232 : 43|1@1+ (1,0) [0|0] "" Vector__XXX
 SG_ USM_a233_receiverReachedErrorState m233 : 43|1@1+ (1,0) [0|0] "" Vector__XXX
 SG_ USM_a234_receiverReachedErrorState m234 : 43|1@1+ (1,0) [0|0] "" Vector__XXX
 SG_ USM_a235_receiverReachedErrorState m235 : 43|1@1+ (1,0) [0|0] "" Vector__XXX
 SG_ USM_a236_receiverReachedErrorState m236 : 43|1@1+ (1,0) [0|0] "" Vector__XXX
 SG_ USM_a237_receiverReachedErrorState m237 : 43|1@1+ (1,0) [0|0] "" Vector__XXX
 SG_ USM_a238_receiverReachedErrorState m238 : 43|1@1+ (1,0) [0|0] "" Vector__XXX
 SG_ USM_a240_receiverReachedErrorState m240 : 43|1@1+ (1,0) [0|0] "" Vector__XXX
 SG_ USM_a241_receiverReachedErrorState m241 : 43|1@1+ (1,0) [0|0] "" Vector__XXX
 SG_ USM_a242_receiverReachedErrorState m242 : 43|1@1+ (1,0) [0|0] "" Vector__XXX
 SG_ USM_a243_receiverReachedErrorState m243 : 43|1@1+ (1,0) [0|0] "" Vector__XXX
 SG_ USM_a244_receiverReachedErrorState m244 : 43|1@1+ (1,0) [0|0] "" Vector__XXX
 SG_ USM_a245_receiverReachedErrorState m245 : 43|1@1+ (1,0) [0|0] "" Vector__XXX
 SG_ USM_a246_receiverReachedErrorState m246 : 43|1@1+ (1,0) [0|0] "" Vector__XXX
 SG_ USM_a247_receiverReachedErrorState m247 : 43|1@1+ (1,0) [0|0] "" Vector__XXX
 SG_ USM_a248_receiverReachedErrorState m248 : 43|1@1+ (1,0) [0|0] "" Vector__XXX
 SG_ USM_a249_receiverReachedErrorState m249 : 43|1@1+ (1,0) [0|0] "" Vector__XXX
 SG_ USM_a250_receiverReachedErrorState m250 : 43|1@1+ (1,0) [0|0] "" Vector__XXX
 SG_ USM_a251_receiverReachedErrorState m251 : 43|1@1+ (1,0) [0|0] "" Vector__XXX
 SG_ USM_a104_VEH_control m104 : 44|1@1+ (1,0) [0|0] "" Vector__XXX
 SG_ USM_a113_VEH_gpsVehicleSpeed m113 : 44|1@1+ (1,0) [0|0] "" Vector__XXX
 SG_ USM_a118_PARTY_VCFRONT_cameraCleaningStatus m118 : 44|1@1+ (1,0) [0|0] "" Vector__XXX
 SG_ USM_a120_VEH_prndControl m120 : 44|1@1+ (1,0) [0|0] "" Vector__XXX
 SG_ USM_a227_pdcmPulseInvalid m227 : 44|1@1+ (1,0) [0|0] "" Vector__XXX
 SG_ USM_a228_pdcmPulseInvalid m228 : 44|1@1+ (1,0) [0|0] "" Vector__XXX
 SG_ USM_a229_pdcmPulseInvalid m229 : 44|1@1+ (1,0) [0|0] "" Vector__XXX
 SG_ USM_a230_pdcmPulseInvalid m230 : 44|1@1+ (1,0) [0|0] "" Vector__XXX
 SG_ USM_a231_pdcmPulseInvalid m231 : 44|1@1+ (1,0) [0|0] "" Vector__XXX
 SG_ USM_a232_pdcmPulseInvalid m232 : 44|1@1+ (1,0) [0|0] "" Vector__XXX
 SG_ USM_a233_pdcmPulseInvalid m233 : 44|1@1+ (1,0) [0|0] "" Vector__XXX
 SG_ USM_a234_pdcmPulseInvalid m234 : 44|1@1+ (1,0) [0|0] "" Vector__XXX
 SG_ USM_a235_pdcmPulseInvalid m235 : 44|1@1+ (1,0) [0|0] "" Vector__XXX
 SG_ USM_a236_pdcmPulseInvalid m236 : 44|1@1+ (1,0) [0|0] "" Vector__XXX
 SG_ USM_a237_pdcmPulseInvalid m237 : 44|1@1+ (1,0) [0|0] "" Vector__XXX
 SG_ USM_a238_pdcmPulseInvalid m238 : 44|1@1+ (1,0) [0|0] "" Vector__XXX
 SG_ USM_a240_pdcmPulseInvalid m240 : 44|1@1+ (1,0) [0|0] "" Vector__XXX
 SG_ USM_a241_pdcmPulseInvalid m241 : 44|1@1+ (1,0) [0|0] "" Vector__XXX
 SG_ USM_a242_pdcmPulseInvalid m242 : 44|1@1+ (1,0) [0|0] "" Vector__XXX
 SG_ USM_a243_pdcmPulseInvalid m243 : 44|1@1+ (1,0) [0|0] "" Vector__XXX
 SG_ USM_a244_pdcmPulseInvalid m244 : 44|1@1+ (1,0) [0|0] "" Vector__XXX
 SG_ USM_a245_pdcmPulseInvalid m245 : 44|1@1+ (1,0) [0|0] "" Vector__XXX
 SG_ USM_a246_pdcmPulseInvalid m246 : 44|1@1+ (1,0) [0|0] "" Vector__XXX
 SG_ USM_a247_pdcmPulseInvalid m247 : 44|1@1+ (1,0) [0|0] "" Vector__XXX
 SG_ USM_a248_pdcmPulseInvalid m248 : 44|1@1+ (1,0) [0|0] "" Vector__XXX
 SG_ USM_a249_pdcmPulseInvalid m249 : 44|1@1+ (1,0) [0|0] "" Vector__XXX
 SG_ USM_a250_pdcmPulseInvalid m250 : 44|1@1+ (1,0) [0|0] "" Vector__XXX
 SG_ USM_a251_pdcmPulseInvalid m251 : 44|1@1+ (1,0) [0|0] "" Vector__XXX
 SG_ USM_a104_VEH_redundantBrakingControl m104 : 45|1@1+ (1,0) [0|0] "" Vector__XXX
 SG_ USM_a113_VEH_status2 m113 : 45|1@1+ (1,0) [0|0] "" Vector__XXX
 SG_ USM_a120_VEH_vehicleEstimates m120 : 45|1@1+ (1,0) [0|0] "" Vector__XXX
 SG_ USM_a227_crcOfReceivedCmdInvalid m227 : 45|1@1+ (1,0) [0|0] "" Vector__XXX
 SG_ USM_a228_crcOfReceivedCmdInvalid m228 : 45|1@1+ (1,0) [0|0] "" Vector__XXX
 SG_ USM_a229_crcOfReceivedCmdInvalid m229 : 45|1@1+ (1,0) [0|0] "" Vector__XXX
 SG_ USM_a230_crcOfReceivedCmdInvalid m230 : 45|1@1+ (1,0) [0|0] "" Vector__XXX
 SG_ USM_a231_crcOfReceivedCmdInvalid m231 : 45|1@1+ (1,0) [0|0] "" Vector__XXX
 SG_ USM_a232_crcOfReceivedCmdInvalid m232 : 45|1@1+ (1,0) [0|0] "" Vector__XXX
 SG_ USM_a233_crcOfReceivedCmdInvalid m233 : 45|1@1+ (1,0) [0|0] "" Vector__XXX
 SG_ USM_a234_crcOfReceivedCmdInvalid m234 : 45|1@1+ (1,0) [0|0] "" Vector__XXX
 SG_ USM_a235_crcOfReceivedCmdInvalid m235 : 45|1@1+ (1,0) [0|0] "" Vector__XXX
 SG_ USM_a236_crcOfReceivedCmdInvalid m236 : 45|1@1+ (1,0) [0|0] "" Vector__XXX
 SG_ USM_a237_crcOfReceivedCmdInvalid m237 : 45|1@1+ (1,0) [0|0] "" Vector__XXX
 SG_ USM_a238_crcOfReceivedCmdInvalid m238 : 45|1@1+ (1,0) [0|0] "" Vector__XXX
 SG_ USM_a240_crcOfReceivedCmdInvalid m240 : 45|1@1+ (1,0) [0|0] "" Vector__XXX
 SG_ USM_a241_crcOfReceivedCmdInvalid m241 : 45|1@1+ (1,0) [0|0] "" Vector__XXX
 SG_ USM_a242_crcOfReceivedCmdInvalid m242 : 45|1@1+ (1,0) [0|0] "" Vector__XXX
 SG_ USM_a243_crcOfReceivedCmdInvalid m243 : 45|1@1+ (1,0) [0|0] "" Vector__XXX
 SG_ USM_a244_crcOfReceivedCmdInvalid m244 : 45|1@1+ (1,0) [0|0] "" Vector__XXX
 SG_ USM_a245_crcOfReceivedCmdInvalid m245 : 45|1@1+ (1,0) [0|0] "" Vector__XXX
 SG_ USM_a246_crcOfReceivedCmdInvalid m246 : 45|1@1+ (1,0) [0|0] "" Vector__XXX
 SG_ USM_a247_crcOfReceivedCmdInvalid m247 : 45|1@1+ (1,0) [0|0] "" Vector__XXX
 SG_ USM_a248_crcOfReceivedCmdInvalid m248 : 45|1@1+ (1,0) [0|0] "" Vector__XXX
 SG_ USM_a249_crcOfReceivedCmdInvalid m249 : 45|1@1+ (1,0) [0|0] "" Vector__XXX
 SG_ USM_a250_crcOfReceivedCmdInvalid m250 : 45|1@1+ (1,0) [0|0] "" Vector__XXX
 SG_ USM_a251_crcOfReceivedCmdInvalid m251 : 45|1@1+ (1,0) [0|0] "" Vector__XXX
 SG_ USM_a104_BDY_bodyControls m104 : 46|1@1+ (1,0) [0|0] "" Vector__XXX
 SG_ USM_a113_VEH_autopilotControl m113 : 46|1@1+ (1,0) [0|0] "" Vector__XXX
 SG_ USM_a120_PARTY_motorStatus m120 : 46|1@1+ (1,0) [0|0] "" Vector__XXX
 SG_ USM_a227_passwordWrong m227 : 46|1@1+ (1,0) [0|0] "" Vector__XXX
 SG_ USM_a228_passwordWrong m228 : 46|1@1+ (1,0) [0|0] "" Vector__XXX
 SG_ USM_a229_passwordWrong m229 : 46|1@1+ (1,0) [0|0] "" Vector__XXX
 SG_ USM_a230_passwordWrong m230 : 46|1@1+ (1,0) [0|0] "" Vector__XXX
 SG_ USM_a231_passwordWrong m231 : 46|1@1+ (1,0) [0|0] "" Vector__XXX
 SG_ USM_a232_passwordWrong m232 : 46|1@1+ (1,0) [0|0] "" Vector__XXX
 SG_ USM_a233_passwordWrong m233 : 46|1@1+ (1,0) [0|0] "" Vector__XXX
 SG_ USM_a234_passwordWrong m234 : 46|1@1+ (1,0) [0|0] "" Vector__XXX
 SG_ USM_a235_passwordWrong m235 : 46|1@1+ (1,0) [0|0] "" Vector__XXX
 SG_ USM_a236_passwordWrong m236 : 46|1@1+ (1,0) [0|0] "" Vector__XXX
 SG_ USM_a237_passwordWrong m237 : 46|1@1+ (1,0) [0|0] "" Vector__XXX
 SG_ USM_a238_passwordWrong m238 : 46|1@1+ (1,0) [0|0] "" Vector__XXX
 SG_ USM_a240_passwordWrong m240 : 46|1@1+ (1,0) [0|0] "" Vector__XXX
 SG_ USM_a241_passwordWrong m241 : 46|1@1+ (1,0) [0|0] "" Vector__XXX
 SG_ USM_a242_passwordWrong m242 : 46|1@1+ (1,0) [0|0] "" Vector__XXX
 SG_ USM_a243_passwordWrong m243 : 46|1@1+ (1,0) [0|0] "" Vector__XXX
 SG_ USM_a244_passwordWrong m244 : 46|1@1+ (1,0) [0|0] "" Vector__XXX
 SG_ USM_a245_passwordWrong m245 : 46|1@1+ (1,0) [0|0] "" Vector__XXX
 SG_ USM_a246_passwordWrong m246 : 46|1@1+ (1,0) [0|0] "" Vector__XXX
 SG_ USM_a247_passwordWrong m247 : 46|1@1+ (1,0) [0|0] "" Vector__XXX
 SG_ USM_a248_passwordWrong m248 : 46|1@1+ (1,0) [0|0] "" Vector__XXX
 SG_ USM_a249_passwordWrong m249 : 46|1@1+ (1,0) [0|0] "" Vector__XXX
 SG_ USM_a250_passwordWrong m250 : 46|1@1+ (1,0) [0|0] "" Vector__XXX
 SG_ USM_a251_passwordWrong m251 : 46|1@1+ (1,0) [0|0] "" Vector__XXX
 SG_ USM_a113_VEH_ambientLightingCtrls m113 : 47|1@1+ (1,0) [0|0] "" Vector__XXX
 SG_ USM_a120_VEH_motorStatus m120 : 47|1@1+ (1,0) [0|0] "" Vector__XXX
 SG_ USM_a227_timeIntBetween2PulsesErr m227 : 47|1@1+ (1,0) [0|0] "" Vector__XXX
 SG_ USM_a228_timeIntBetween2PulsesErr m228 : 47|1@1+ (1,0) [0|0] "" Vector__XXX
 SG_ USM_a229_timeIntBetween2PulsesErr m229 : 47|1@1+ (1,0) [0|0] "" Vector__XXX
 SG_ USM_a230_timeIntBetween2PulsesErr m230 : 47|1@1+ (1,0) [0|0] "" Vector__XXX
 SG_ USM_a231_timeIntBetween2PulsesErr m231 : 47|1@1+ (1,0) [0|0] "" Vector__XXX
 SG_ USM_a232_timeIntBetween2PulsesErr m232 : 47|1@1+ (1,0) [0|0] "" Vector__XXX
 SG_ USM_a233_timeIntBetween2PulsesErr m233 : 47|1@1+ (1,0) [0|0] "" Vector__XXX
 SG_ USM_a234_timeIntBetween2PulsesErr m234 : 47|1@1+ (1,0) [0|0] "" Vector__XXX
 SG_ USM_a235_timeIntBetween2PulsesErr m235 : 47|1@1+ (1,0) [0|0] "" Vector__XXX
 SG_ USM_a236_timeIntBetween2PulsesErr m236 : 47|1@1+ (1,0) [0|0] "" Vector__XXX
 SG_ USM_a237_timeIntBetween2PulsesErr m237 : 47|1@1+ (1,0) [0|0] "" Vector__XXX
 SG_ USM_a238_timeIntBetween2PulsesErr m238 : 47|1@1+ (1,0) [0|0] "" Vector__XXX
 SG_ USM_a240_timeIntBetween2PulsesErr m240 : 47|1@1+ (1,0) [0|0] "" Vector__XXX
 SG_ USM_a241_timeIntBetween2PulsesErr m241 : 47|1@1+ (1,0) [0|0] "" Vector__XXX
 SG_ USM_a242_timeIntBetween2PulsesErr m242 : 47|1@1+ (1,0) [0|0] "" Vector__XXX
 SG_ USM_a243_timeIntBetween2PulsesErr m243 : 47|1@1+ (1,0) [0|0] "" Vector__XXX
 SG_ USM_a244_timeIntBetween2PulsesErr m244 : 47|1@1+ (1,0) [0|0] "" Vector__XXX
 SG_ USM_a245_timeIntBetween2PulsesErr m245 : 47|1@1+ (1,0) [0|0] "" Vector__XXX
 SG_ USM_a246_timeIntBetween2PulsesErr m246 : 47|1@1+ (1,0) [0|0] "" Vector__XXX
 SG_ USM_a247_timeIntBetween2PulsesErr m247 : 47|1@1+ (1,0) [0|0] "" Vector__XXX
 SG_ USM_a248_timeIntBetween2PulsesErr m248 : 47|1@1+ (1,0) [0|0] "" Vector__XXX
 SG_ USM_a249_timeIntBetween2PulsesErr m249 : 47|1@1+ (1,0) [0|0] "" Vector__XXX
 SG_ USM_a250_timeIntBetween2PulsesErr m250 : 47|1@1+ (1,0) [0|0] "" Vector__XXX
 SG_ USM_a251_timeIntBetween2PulsesErr m251 : 47|1@1+ (1,0) [0|0] "" Vector__XXX
 SG_ USM_a000_alertDataW2 m0 : 48|16@1+ (1,0) [0|0] "" Vector__XXX
 SG_ USM_a003_Data m3 : 48|16@1+ (1,0) [0|0] "" Vector__XXX
 SG_ USM_a022_TaskInitError3 m22 : 48|8@1+ (1,0) [0|0] "" Vector__XXX
 SG_ USM_a031_uds_bytes_4 m31 : 48|8@1+ (1,0) [0|0] "" Vector__XXX
 SG_ USM_a041_CPULoad1000msTask m41 : 48|8@1+ (1,0) [0|0] "" Vector__XXX
 SG_ USM_a042_UsageUDSTask m42 : 48|8@1+ (1,0) [0|0] "" Vector__XXX
 SG_ USM_a113_VEH_driverAssistMapData m113 : 48|1@1+ (1,0) [0|0] "" Vector__XXX
 SG_ USM_a120_BDY_speed m120 : 48|1@1+ (1,0) [0|0] "" Vector__XXX
 SG_ USM_a177_sensorTemperature m177 : 48|8@1- (1,33) [0|0] "" Vector__XXX
 SG_ USM_a178_sensorTemperature m178 : 48|8@1- (1,33) [0|0] "" Vector__XXX
 SG_ USM_a179_sensorTemperature m179 : 48|8@1- (1,33) [0|0] "" Vector__XXX
 SG_ USM_a180_sensorTemperature m180 : 48|8@1- (1,33) [0|0] "" Vector__XXX
 SG_ USM_a181_sensorTemperature m181 : 48|8@1- (1,33) [0|0] "" Vector__XXX
 SG_ USM_a182_sensorTemperature m182 : 48|8@1- (1,33) [0|0] "" Vector__XXX
 SG_ USM_a183_sensorTemperature m183 : 48|8@1- (1,33) [0|0] "" Vector__XXX
 SG_ USM_a184_sensorTemperature m184 : 48|8@1- (1,33) [0|0] "" Vector__XXX
 SG_ USM_a185_sensorTemperature m185 : 48|8@1- (1,33) [0|0] "" Vector__XXX
 SG_ USM_a186_sensorTemperature m186 : 48|8@1- (1,33) [0|0] "" Vector__XXX
 SG_ USM_a187_sensorTemperature m187 : 48|8@1- (1,33) [0|0] "" Vector__XXX
 SG_ USM_a188_sensorTemperature m188 : 48|8@1- (1,33) [0|0] "" Vector__XXX
 SG_ USM_a227_numInvalidStartEdgeSinceInit m227 : 48|4@1+ (1,0) [0|0] "" Vector__XXX
 SG_ USM_a228_numInvalidStartEdgeSinceInit m228 : 48|4@1+ (1,0) [0|0] "" Vector__XXX
 SG_ USM_a229_numInvalidStartEdgeSinceInit m229 : 48|4@1+ (1,0) [0|0] "" Vector__XXX
 SG_ USM_a230_numInvalidStartEdgeSinceInit m230 : 48|4@1+ (1,0) [0|0] "" Vector__XXX
 SG_ USM_a231_numInvalidStartEdgeSinceInit m231 : 48|4@1+ (1,0) [0|0] "" Vector__XXX
 SG_ USM_a232_numInvalidStartEdgeSinceInit m232 : 48|4@1+ (1,0) [0|0] "" Vector__XXX
 SG_ USM_a233_numInvalidStartEdgeSinceInit m233 : 48|4@1+ (1,0) [0|0] "" Vector__XXX
 SG_ USM_a234_numInvalidStartEdgeSinceInit m234 : 48|4@1+ (1,0) [0|0] "" Vector__XXX
 SG_ USM_a235_numInvalidStartEdgeSinceInit m235 : 48|4@1+ (1,0) [0|0] "" Vector__XXX
 SG_ USM_a236_numInvalidStartEdgeSinceInit m236 : 48|4@1+ (1,0) [0|0] "" Vector__XXX
 SG_ USM_a237_numInvalidStartEdgeSinceInit m237 : 48|4@1+ (1,0) [0|0] "" Vector__XXX
 SG_ USM_a238_numInvalidStartEdgeSinceInit m238 : 48|4@1+ (1,0) [0|0] "" Vector__XXX
 SG_ USM_a240_numInvalidStartEdgeSinceInit m240 : 48|4@1+ (1,0) [0|0] "" Vector__XXX
 SG_ USM_a241_numInvalidStartEdgeSinceInit m241 : 48|4@1+ (1,0) [0|0] "" Vector__XXX
 SG_ USM_a242_numInvalidStartEdgeSinceInit m242 : 48|4@1+ (1,0) [0|0] "" Vector__XXX
 SG_ USM_a243_numInvalidStartEdgeSinceInit m243 : 48|4@1+ (1,0) [0|0] "" Vector__XXX
 SG_ USM_a244_numInvalidStartEdgeSinceInit m244 : 48|4@1+ (1,0) [0|0] "" Vector__XXX
 SG_ USM_a245_numInvalidStartEdgeSinceInit m245 : 48|4@1+ (1,0) [0|0] "" Vector__XXX
 SG_ USM_a246_numInvalidStartEdgeSinceInit m246 : 48|4@1+ (1,0) [0|0] "" Vector__XXX
 SG_ USM_a247_numInvalidStartEdgeSinceInit m247 : 48|4@1+ (1,0) [0|0] "" Vector__XXX
 SG_ USM_a248_numInvalidStartEdgeSinceInit m248 : 48|4@1+ (1,0) [0|0] "" Vector__XXX
 SG_ USM_a249_numInvalidStartEdgeSinceInit m249 : 48|4@1+ (1,0) [0|0] "" Vector__XXX
 SG_ USM_a250_numInvalidStartEdgeSinceInit m250 : 48|4@1+ (1,0) [0|0] "" Vector__XXX
 SG_ USM_a251_numInvalidStartEdgeSinceInit m251 : 48|4@1+ (1,0) [0|0] "" Vector__XXX
 SG_ USM_a113_CH_vehicleControl2 m113 : 49|1@1+ (1,0) [0|0] "" Vector__XXX
 SG_ USM_a113_VEH_odo m113 : 50|1@1+ (1,0) [0|0] "" Vector__XXX
 SG_ USM_a058_newREstimate m58 : 51|12@1+ (0.00061,0) [0|0] "" Vector__XXX
 SG_ USM_a227_numAtgNoiseErrorsSinceInit m227 : 52|4@1+ (1,0) [0|0] "" Vector__XXX
 SG_ USM_a228_numAtgNoiseErrorsSinceInit m228 : 52|4@1+ (1,0) [0|0] "" Vector__XXX
 SG_ USM_a229_numAtgNoiseErrorsSinceInit m229 : 52|4@1+ (1,0) [0|0] "" Vector__XXX
 SG_ USM_a230_numAtgNoiseErrorsSinceInit m230 : 52|4@1+ (1,0) [0|0] "" Vector__XXX
 SG_ USM_a231_numAtgNoiseErrorsSinceInit m231 : 52|4@1+ (1,0) [0|0] "" Vector__XXX
 SG_ USM_a232_numAtgNoiseErrorsSinceInit m232 : 52|4@1+ (1,0) [0|0] "" Vector__XXX
 SG_ USM_a233_numAtgNoiseErrorsSinceInit m233 : 52|4@1+ (1,0) [0|0] "" Vector__XXX
 SG_ USM_a234_numAtgNoiseErrorsSinceInit m234 : 52|4@1+ (1,0) [0|0] "" Vector__XXX
 SG_ USM_a235_numAtgNoiseErrorsSinceInit m235 : 52|4@1+ (1,0) [0|0] "" Vector__XXX
 SG_ USM_a236_numAtgNoiseErrorsSinceInit m236 : 52|4@1+ (1,0) [0|0] "" Vector__XXX
 SG_ USM_a237_numAtgNoiseErrorsSinceInit m237 : 52|4@1+ (1,0) [0|0] "" Vector__XXX
 SG_ USM_a238_numAtgNoiseErrorsSinceInit m238 : 52|4@1+ (1,0) [0|0] "" Vector__XXX
 SG_ USM_a240_numAtgNoiseErrorsSinceInit m240 : 52|4@1+ (1,0) [0|0] "" Vector__XXX
 SG_ USM_a241_numAtgNoiseErrorsSinceInit m241 : 52|4@1+ (1,0) [0|0] "" Vector__XXX
 SG_ USM_a242_numAtgNoiseErrorsSinceInit m242 : 52|4@1+ (1,0) [0|0] "" Vector__XXX
 SG_ USM_a243_numAtgNoiseErrorsSinceInit m243 : 52|4@1+ (1,0) [0|0] "" Vector__XXX
 SG_ USM_a244_numAtgNoiseErrorsSinceInit m244 : 52|4@1+ (1,0) [0|0] "" Vector__XXX
 SG_ USM_a245_numAtgNoiseErrorsSinceInit m245 : 52|4@1+ (1,0) [0|0] "" Vector__XXX
 SG_ USM_a246_numAtgNoiseErrorsSinceInit m246 : 52|4@1+ (1,0) [0|0] "" Vector__XXX
 SG_ USM_a247_numAtgNoiseErrorsSinceInit m247 : 52|4@1+ (1,0) [0|0] "" Vector__XXX
 SG_ USM_a248_numAtgNoiseErrorsSinceInit m248 : 52|4@1+ (1,0) [0|0] "" Vector__XXX
 SG_ USM_a249_numAtgNoiseErrorsSinceInit m249 : 52|4@1+ (1,0) [0|0] "" Vector__XXX
 SG_ USM_a250_numAtgNoiseErrorsSinceInit m250 : 52|4@1+ (1,0) [0|0] "" Vector__XXX
 SG_ USM_a251_numAtgNoiseErrorsSinceInit m251 : 52|4@1+ (1,0) [0|0] "" Vector__XXX
 SG_ USM_a022_TaskInitError4 m22 : 56|8@1+ (1,0) [0|0] "" Vector__XXX
 SG_ USM_a031_uds_bytes_5 m31 : 56|8@1+ (1,0) [0|0] "" Vector__XXX
 SG_ USM_a041_CPULoadNVMMTask m41 : 56|8@1+ (1,0) [0|0] "" Vector__XXX
 SG_ USM_a042_UsageNVMMTask m42 : 56|8@1+ (1,0) [0|0] "" Vector__XXX
 SG_ USM_a131_numComErrSinceInit m131 : 56|8@1+ (1,0) [0|0] "" Vector__XXX
 SG_ USM_a132_numComErrSinceInit m132 : 56|8@1+ (1,0) [0|0] "" Vector__XXX
 SG_ USM_a133_numComErrSinceInit m133 : 56|8@1+ (1,0) [0|0] "" Vector__XXX
 SG_ USM_a134_numComErrSinceInit m134 : 56|8@1+ (1,0) [0|0] "" Vector__XXX
 SG_ USM_a135_numComErrSinceInit m135 : 56|8@1+ (1,0) [0|0] "" Vector__XXX
 SG_ USM_a136_numComErrSinceInit m136 : 56|8@1+ (1,0) [0|0] "" Vector__XXX
 SG_ USM_a137_numComErrSinceInit m137 : 56|8@1+ (1,0) [0|0] "" Vector__XXX
 SG_ USM_a138_numComErrSinceInit m138 : 56|8@1+ (1,0) [0|0] "" Vector__XXX
 SG_ USM_a139_numComErrSinceInit m139 : 56|8@1+ (1,0) [0|0] "" Vector__XXX
 SG_ USM_a140_numComErrSinceInit m140 : 56|8@1+ (1,0) [0|0] "" Vector__XXX
 SG_ USM_a141_numComErrSinceInit m141 : 56|8@1+ (1,0) [0|0] "" Vector__XXX
 SG_ USM_a142_numComErrSinceInit m142 : 56|8@1+ (1,0) [0|0] "" Vector__XXX
 SG_ USM_a143_numHwErrSinceInit m143 : 56|8@1+ (1,0) [0|0] "" Vector__XXX
 SG_ USM_a144_numHwErrSinceInit m144 : 56|8@1+ (1,0) [0|0] "" Vector__XXX
 SG_ USM_a145_numHwErrSinceInit m145 : 56|8@1+ (1,0) [0|0] "" Vector__XXX
 SG_ USM_a146_numHwErrSinceInit m146 : 56|8@1+ (1,0) [0|0] "" Vector__XXX
 SG_ USM_a147_numHwErrSinceInit m147 : 56|8@1+ (1,0) [0|0] "" Vector__XXX
 SG_ USM_a148_numHwErrSinceInit m148 : 56|8@1+ (1,0) [0|0] "" Vector__XXX
 SG_ USM_a149_numHwErrSinceInit m149 : 56|8@1+ (1,0) [0|0] "" Vector__XXX
 SG_ USM_a150_numHwErrSinceInit m150 : 56|8@1+ (1,0) [0|0] "" Vector__XXX
 SG_ USM_a151_numHwErrSinceInit m151 : 56|8@1+ (1,0) [0|0] "" Vector__XXX
 SG_ USM_a152_numHwErrSinceInit m152 : 56|8@1+ (1,0) [0|0] "" Vector__XXX
 SG_ USM_a153_numHwErrSinceInit m153 : 56|8@1+ (1,0) [0|0] "" Vector__XXX
 SG_ USM_a154_numHwErrSinceInit m154 : 56|8@1+ (1,0) [0|0] "" Vector__XXX
 SG_ USM_a058_faultReason m58 : 63|1@1+ (1,0) [0|0] "" Vector__XXX

BO_ 1521 RCM_bootID: 12 Vector__XXX
 SG_ RCM_bootComponentId : 7|16@0+ (1,0) [0|0] "" Vector__XXX
 SG_ RCM_bootPcbaId : 23|8@0+ (1,0) [0|0] "" Vector__XXX
 SG_ RCM_bootAssemblyId : 31|8@0+ (1,0) [0|0] "" Vector__XXX
 SG_ RCM_bootUsageId : 39|16@0+ (1,0) [0|0] "" Vector__XXX
 SG_ RCM_bootFirmwareType : 63|8@0+ (1,0) [0|0] "" Vector__XXX

BO_ 1523 APS_tsyncStatus: 8 Vector__XXX
 SG_ APS_A_tsyncStatus : 0|6@1+ (1,0) [0|0] "" Vector__XXX
 SG_ APS_B_tsyncStatus : 6|6@1+ (1,0) [0|0] "" Vector__XXX

BO_ 1529 DAS_dataLog: 8 Vector__XXX
 SG_ DAS_logMltplxr M : 0|8@1+ (1,0) [0|0] "" Vector__XXX
 SG_ DAS_HilMode m15 : 8|8@1+ (1,0) [0|0] "" Vector__XXX
 SG_ DAS_bootmsg_ApplicationtVersion m20 : 8|32@1+ (1,0) [0|0] "" Vector__XXX
 SG_ DAS_bootmsg_DDR_MfgCode m21 : 8|8@1+ (1,0) [0|0] "" Vector__XXX
 SG_ DAS_bootmsg_EyeQ_Temp_VMP m19 : 8|8@1+ (1,0) [0|0] "" Vector__XXX
 SG_ DAS_bootmsg_testResults m18 : 8|16@1+ (1,0) [0|0] "" Vector__XXX
 SG_ DAS_calib_reply_ret m16 : 8|8@1+ (1,0) [0|0] "" Vector__XXX
 SG_ DAS_init_version m10 : 8|8@1+ (1,0) [0|0] "" Vector__XXX
 SG_ DAS_maxYaw m12 : 8|8@1+ (1,0) [0|0] "" Vector__XXX
 SG_ DAS_mesp_health_diag_flag_0 m17 : 8|16@1+ (1,0) [0|0] "" Vector__XXX
 SG_ DAS_radarTarg5_dx m23 : 8|8@1+ (0.0625,0) [0|0] "" Vector__XXX
 SG_ DAS_roadEdgeWarningEnabled m13 : 8|8@1+ (1,0) [0|0] "" Vector__XXX
 SG_ DAS_scaLogVersion m22 : 8|3@1+ (1,0) [0|0] "" Vector__XXX
 SG_ DAS_speed_turn_off m14 : 8|8@1+ (0.1,0) [0|0] "" Vector__XXX
 SG_ DAS_yawFull m11 : 8|8@1- (1,0) [0|0] "" Vector__XXX
 SG_ DAS_scaLogType m22 : 11|3@1+ (1,0) [0|0] "" Vector__XXX
 SG_ DAS_scaLDWstatus m22 : 14|2@1+ (1,0) [0|0] "" Vector__XXX
 SG_ DAS_StartupFrameIndex m15 : 16|8@1+ (1,0) [0|0] "" Vector__XXX
 SG_ DAS_bootmsg_Flash_MfgCode m21 : 16|8@1+ (1,0) [0|0] "" Vector__XXX
 SG_ DAS_bootmsg_LPDDR2_temp_status m19 : 16|8@1+ (1,0) [0|0] "" Vector__XXX
 SG_ DAS_calib_reply_ct_type m16 : 16|8@1+ (1,0) [0|0] "" Vector__XXX
 SG_ DAS_detectConstructionArea m13 : 16|8@1+ (1,0) [0|0] "" Vector__XXX
 SG_ DAS_init_autofixHorizon m11 : 16|8@1- (1,0) [0|0] "" Vector__XXX
 SG_ DAS_leftWheel m10 : 16|8@1+ (0.01,0) [0|0] "" Vector__XXX
 SG_ DAS_radarTarg1_dx m23 : 16|8@1+ (0.0625,0) [0|0] "" Vector__XXX
 SG_ DAS_rollAngle m12 : 16|16@1- (0.001,0) [0|0] "" Vector__XXX
 SG_ DAS_scaLeftLaneChange m22 : 16|1@1+ (1,0) [0|0] "" Vector__XXX
 SG_ DAS_speed_turn_on m14 : 16|8@1+ (0.1,0) [0|0] "" Vector__XXX
 SG_ DAS_scaRightLaneChange m22 : 17|1@1+ (1,0) [0|0] "" Vector__XXX
 SG_ DAS_scaMinLeftUltraDist m22 : 18|9@1+ (0.01,0) [0|0] "" Vector__XXX
 SG_ DAS_RightWheel m10 : 24|8@1+ (0.01,0) [0|0] "" Vector__XXX
 SG_ DAS_bootmsg_BoardProjectCode m21 : 24|8@1+ (1,0) [0|0] "" Vector__XXX
 SG_ DAS_bootmsg_BootVersion m19 : 24|32@1+ (1,0) [0|0] "" Vector__XXX
 SG_ DAS_bootmsg_EyeQST_Test m18 : 24|32@1+ (1,0) [0|0] "" Vector__XXX
 SG_ DAS_calib_reply_ct_ver m16 : 24|8@1+ (1,0) [0|0] "" Vector__XXX
 SG_ DAS_camGenObj_dx m23 : 24|8@1+ (0.05,0) [0|0] "" Vector__XXX
 SG_ DAS_corridor_outer_boundary m13 : 24|8@1+ (0.01,0) [0|0] "" Vector__XXX
 SG_ DAS_forcedNonParallel m15 : 24|8@1+ (1,0) [0|0] "" Vector__XXX
 SG_ DAS_init_autofixYaw m11 : 24|8@1- (1,0) [0|0] "" Vector__XXX
 SG_ DAS_mesp_health_diag_flag_1 m17 : 24|16@1+ (1,0) [0|0] "" Vector__XXX
 SG_ DAS_t_max_wrn m14 : 24|8@1+ (1,0) [0|0] "" Vector__XXX
 SG_ DAS_scaMinRightUltraDist m22 : 27|9@1+ (0.01,0) [0|0] "" Vector__XXX
 SG_ DAS_bootmsg_Flash_2_MfgCode m21 : 32|8@1+ (1,0) [0|0] "" Vector__XXX
 SG_ DAS_bottom m11 : 32|8@1- (1,0) [0|0] "" Vector__XXX
 SG_ DAS_camCipv_dx m23 : 32|8@1+ (0.2,0) [0|0] "" Vector__XXX
 SG_ DAS_cameraHeight m10 : 32|8@1+ (0.01,0) [0|0] "" Vector__XXX
 SG_ DAS_disableRectangular m15 : 32|8@1+ (1,0) [0|0] "" Vector__XXX
 SG_ DAS_mesp_health_error_code m16 : 32|8@1+ (1,0) [0|0] "" Vector__XXX
 SG_ DAS_pos_warn_dist_thresh m13 : 32|8@1+ (0.01,0) [0|0] "" Vector__XXX
 SG_ DAS_regionCode m12 : 32|8@1+ (1,0) [0|0] "" Vector__XXX
 SG_ DAS_t_min_wrn m14 : 32|8@1+ (1,0) [0|0] "" Vector__XXX
 SG_ DAS_scaMaxTorsionBarTorque m22 : 36|12@1+ (0.01,-20.5) [0|0] "" Vector__XXX
 SG_ DAS_Reserved_2 m15 : 40|8@1+ (1,0) [0|0] "" Vector__XXX
 SG_ DAS_bootmsg_DDR_Size m21 : 40|8@1+ (1,0) [0|0] "" Vector__XXX
 SG_ DAS_bootmsg_EyeQ_LotNumber m20 : 40|24@1+ (1,0) [0|0] "" Vector__XXX
 SG_ DAS_camPed_dx m23 : 40|8@1+ (0.2,0) [0|0] "" Vector__XXX
 SG_ DAS_drivingSide m12 : 40|2@1+ (1,0) [0|0] "" Vector__XXX
 SG_ DAS_enableLaneCenterPred m14 : 40|8@1+ (1,0) [0|0] "" Vector__XXX
 SG_ DAS_focalLength m10 : 40|16@1+ (1,0) [0|0] "" Vector__XXX
 SG_ DAS_mesp_health_error_details m16 : 40|8@1+ (1,0) [0|0] "" Vector__XXX
 SG_ DAS_mesp_health_state_data_1 m17 : 40|8@1+ (1,0) [0|0] "" Vector__XXX
 SG_ DAS_outer_dist_term_warn m13 : 40|8@1+ (0.01,0) [0|0] "" Vector__XXX
 SG_ DAS_top m11 : 40|8@1+ (1,0) [0|0] "" Vector__XXX
 SG_ DAS_OC_REDUCED_SENSITIVITY m14 : 48|8@1+ (0.1,0) [0|0] "" Vector__XXX
 SG_ DAS_bootmsg_FlashSize m21 : 48|8@1+ (1,0) [0|0] "" Vector__XXX
 SG_ DAS_mesp_health_main_state m16 : 48|8@1+ (1,0) [0|0] "" Vector__XXX
 SG_ DAS_mesp_health_state_data_2 m17 : 48|8@1+ (1,0) [0|0] "" Vector__XXX
 SG_ DAS_minHorizon m11 : 48|8@1- (1,0) [0|0] "" Vector__XXX
 SG_ DAS_narrow_lane_width m13 : 48|8@1+ (0.1,0) [0|0] "" Vector__XXX
 SG_ DAS_refPointX m12 : 48|8@1+ (0.1,0) [0|0] "" Vector__XXX
 SG_ DAS_scaMinTTC m22 : 48|4@1+ (0.1,0) [0|0] "" Vector__XXX
 SG_ DAS_stwAngle m23 : 48|8@1- (1,0) [0|0] "" Vector__XXX
 SG_ DAS_scaMaxSteeringWheelAngleRate m22 : 52|7@1+ (1,-64) [0|0] "" Vector__XXX
 SG_ DAS_Reserved_1 m14 : 56|8@1+ (1,0) [0|0] "" Vector__XXX
 SG_ DAS_bootmsg_BoardRevision m19 : 56|8@1+ (1,0) [0|0] "" Vector__XXX
 SG_ DAS_bootmsg_EyeQ_Temp_CPU m18 : 56|8@1- (1,0) [0|0] "" Vector__XXX
 SG_ DAS_bootmsg_Flash_2_Size m21 : 56|8@1+ (1,0) [0|0] "" Vector__XXX
 SG_ DAS_horizonFull m10 : 56|8@1+ (1,0) [0|0] "" Vector__XXX
 SG_ DAS_maxHorizon m11 : 56|8@1- (1,0) [0|0] "" Vector__XXX
 SG_ DAS_mesp_health_sub_state m16 : 56|8@1+ (1,0) [0|0] "" Vector__XXX
 SG_ DAS_min_lane_width m13 : 56|8@1+ (0.1,0) [0|0] "" Vector__XXX
 SG_ DAS_refPointY m12 : 56|8@1+ (0.1,0) [0|0] "" Vector__XXX
 SG_ DAS_yawRate m23 : 56|8@1+ (0.015625,-2) [0|0] "" Vector__XXX
 SG_ DAS_scaOnHighway m22 : 59|1@1+ (1,0) [0|0] "" Vector__XXX
 SG_ DAS_scaTTCDuration m22 : 60|4@1+ (0.1,0) [0|0] "" Vector__XXX

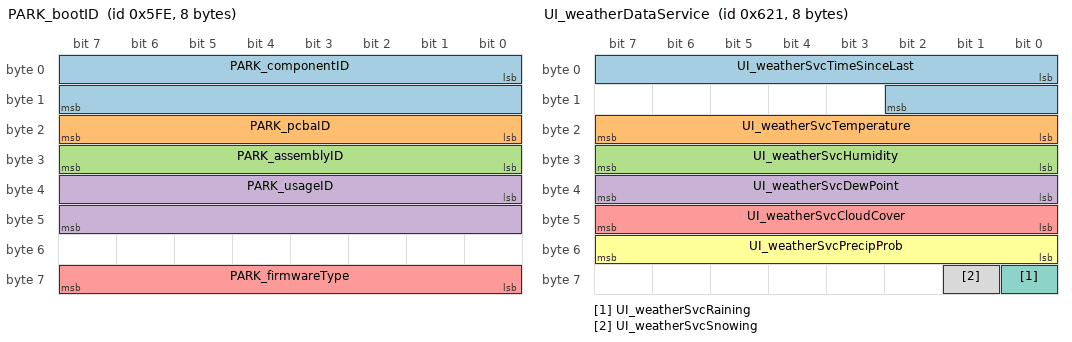
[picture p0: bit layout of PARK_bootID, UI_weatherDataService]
BO_ 1534 PARK_bootID: 8 Vector__XXX
 SG_ PARK_componentID : 0|16@1+ (1,0) [0|0] "" Vector__XXX
 SG_ PARK_pcbaID : 16|8@1+ (1,0) [0|0] "" Vector__XXX
 SG_ PARK_assemblyID : 24|8@1+ (1,0) [0|0] "" Vector__XXX
 SG_ PARK_usageID : 32|16@1+ (1,0) [0|0] "" Vector__XXX
 SG_ PARK_firmwareType : 56|8@1+ (1,0) [0|0] "" Vector__XXX

BO_ 1535 TPMS_bootID: 8 Vector__XXX
 SG_ TPMS_bootIdData : 0|64@1+ (1,0) [0|0] "" Vector__XXX

BO_ 1548 DAS_telemetryRadar: 8 Vector__XXX
 SG_ DAS_TR_ObjIndex M : 0|5@1+ (1,0) [0|0] "" Vector__XXX
 SG_ DAS_TR_Obj00_Class m0 : 5|3@1+ (1,0) [0|0] "" Vector__XXX
 SG_ DAS_TR_Obj01_Class m1 : 5|3@1+ (1,0) [0|0] "" Vector__XXX
 SG_ DAS_TR_Obj02_Class m2 : 5|3@1+ (1,0) [0|0] "" Vector__XXX
 SG_ DAS_TR_Obj03_Class m3 : 5|3@1+ (1,0) [0|0] "" Vector__XXX
 SG_ DAS_TR_Obj04_Class m4 : 5|3@1+ (1,0) [0|0] "" Vector__XXX
 SG_ DAS_TR_Obj05_Class m5 : 5|3@1+ (1,0) [0|0] "" Vector__XXX
 SG_ DAS_TR_Obj06_Class m6 : 5|3@1+ (1,0) [0|0] "" Vector__XXX
 SG_ DAS_TR_Obj07_Class m7 : 5|3@1+ (1,0) [0|0] "" Vector__XXX
 SG_ DAS_TR_Obj08_Class m8 : 5|3@1+ (1,0) [0|0] "" Vector__XXX
 SG_ DAS_TR_Obj09_Class m9 : 5|3@1+ (1,0) [0|0] "" Vector__XXX
 SG_ DAS_TR_Obj10_Class m10 : 5|3@1+ (1,0) [0|0] "" Vector__XXX
 SG_ DAS_TR_Obj11_Class m11 : 5|3@1+ (1,0) [0|0] "" Vector__XXX
 SG_ DAS_TR_Obj12_Class m12 : 5|3@1+ (1,0) [0|0] "" Vector__XXX
 SG_ DAS_TR_Obj13_Class m13 : 5|3@1+ (1,0) [0|0] "" Vector__XXX
 SG_ DAS_TR_Obj14_Class m14 : 5|3@1+ (1,0) [0|0] "" Vector__XXX
 SG_ DAS_TR_Obj15_Class m15 : 5|3@1+ (1,0) [0|0] "" Vector__XXX
 SG_ DAS_TR_Obj16_Class m16 : 5|3@1+ (1,0) [0|0] "" Vector__XXX
 SG_ DAS_TR_Obj17_Class m17 : 5|3@1+ (1,0) [0|0] "" Vector__XXX
 SG_ DAS_TR_Obj18_Class m18 : 5|3@1+ (1,0) [0|0] "" Vector__XXX
 SG_ DAS_TR_Obj19_Class m19 : 5|3@1+ (1,0) [0|0] "" Vector__XXX
 SG_ DAS_TR_Obj20_Class m20 : 5|3@1+ (1,0) [0|0] "" Vector__XXX
 SG_ DAS_TR_Obj21_Class m21 : 5|3@1+ (1,0) [0|0] "" Vector__XXX
 SG_ DAS_TR_Obj22_Class m22 : 5|3@1+ (1,0) [0|0] "" Vector__XXX
 SG_ DAS_TR_Obj23_Class m23 : 5|3@1+ (1,0) [0|0] "" Vector__XXX
 SG_ DAS_TR_Obj24_Class m24 : 5|3@1+ (1,0) [0|0] "" Vector__XXX
 SG_ DAS_TR_Obj25_Class m25 : 5|3@1+ (1,0) [0|0] "" Vector__XXX
 SG_ DAS_TR_Obj26_Class m26 : 5|3@1+ (1,0) [0|0] "" Vector__XXX
 SG_ DAS_TR_Obj27_Class m27 : 5|3@1+ (1,0) [0|0] "" Vector__XXX
 SG_ DAS_TR_Obj28_Class m28 : 5|3@1+ (1,0) [0|0] "" Vector__XXX
 SG_ DAS_TR_Obj29_Class m29 : 5|3@1+ (1,0) [0|0] "" Vector__XXX
 SG_ DAS_TR_Obj30_Class m30 : 5|3@1+ (1,0) [0|0] "" Vector__XXX
 SG_ DAS_TR_Obj31_Class m31 : 5|3@1+ (1,0) [0|0] "" Vector__XXX
 SG_ DAS_TR_Obj00_Dx m0 : 8|10@1+ (0.15625,0) [0|0] "" Vector__XXX
 SG_ DAS_TR_Obj01_Dx m1 : 8|10@1+ (0.15625,0) [0|0] "" Vector__XXX
 SG_ DAS_TR_Obj02_Dx m2 : 8|10@1+ (0.15625,0) [0|0] "" Vector__XXX
 SG_ DAS_TR_Obj03_Dx m3 : 8|10@1+ (0.15625,0) [0|0] "" Vector__XXX
 SG_ DAS_TR_Obj04_Dx m4 : 8|10@1+ (0.15625,0) [0|0] "" Vector__XXX
 SG_ DAS_TR_Obj05_Dx m5 : 8|10@1+ (0.15625,0) [0|0] "" Vector__XXX
 SG_ DAS_TR_Obj06_Dx m6 : 8|10@1+ (0.15625,0) [0|0] "" Vector__XXX
 SG_ DAS_TR_Obj07_Dx m7 : 8|10@1+ (0.15625,0) [0|0] "" Vector__XXX
 SG_ DAS_TR_Obj08_Dx m8 : 8|10@1+ (0.15625,0) [0|0] "" Vector__XXX
 SG_ DAS_TR_Obj09_Dx m9 : 8|10@1+ (0.15625,0) [0|0] "" Vector__XXX
 SG_ DAS_TR_Obj10_Dx m10 : 8|10@1+ (0.15625,0) [0|0] "" Vector__XXX
 SG_ DAS_TR_Obj11_Dx m11 : 8|10@1+ (0.15625,0) [0|0] "" Vector__XXX
 SG_ DAS_TR_Obj12_Dx m12 : 8|10@1+ (0.15625,0) [0|0] "" Vector__XXX
 SG_ DAS_TR_Obj13_Dx m13 : 8|10@1+ (0.15625,0) [0|0] "" Vector__XXX
 SG_ DAS_TR_Obj14_Dx m14 : 8|10@1+ (0.15625,0) [0|0] "" Vector__XXX
 SG_ DAS_TR_Obj15_Dx m15 : 8|10@1+ (0.15625,0) [0|0] "" Vector__XXX
 SG_ DAS_TR_Obj16_Dx m16 : 8|10@1+ (0.15625,0) [0|0] "" Vector__XXX
 SG_ DAS_TR_Obj17_Dx m17 : 8|10@1+ (0.15625,0) [0|0] "" Vector__XXX
 SG_ DAS_TR_Obj18_Dx m18 : 8|10@1+ (0.15625,0) [0|0] "" Vector__XXX
 SG_ DAS_TR_Obj19_Dx m19 : 8|10@1+ (0.15625,0) [0|0] "" Vector__XXX
 SG_ DAS_TR_Obj20_Dx m20 : 8|10@1+ (0.15625,0) [0|0] "" Vector__XXX
 SG_ DAS_TR_Obj21_Dx m21 : 8|10@1+ (0.15625,0) [0|0] "" Vector__XXX
 SG_ DAS_TR_Obj22_Dx m22 : 8|10@1+ (0.15625,0) [0|0] "" Vector__XXX
 SG_ DAS_TR_Obj23_Dx m23 : 8|10@1+ (0.15625,0) [0|0] "" Vector__XXX
 SG_ DAS_TR_Obj24_Dx m24 : 8|10@1+ (0.15625,0) [0|0] "" Vector__XXX
 SG_ DAS_TR_Obj25_Dx m25 : 8|10@1+ (0.15625,0) [0|0] "" Vector__XXX
 SG_ DAS_TR_Obj26_Dx m26 : 8|10@1+ (0.15625,0) [0|0] "" Vector__XXX
 SG_ DAS_TR_Obj27_Dx m27 : 8|10@1+ (0.15625,0) [0|0] "" Vector__XXX
 SG_ DAS_TR_Obj28_Dx m28 : 8|10@1+ (0.15625,0) [0|0] "" Vector__XXX
 SG_ DAS_TR_Obj29_Dx m29 : 8|10@1+ (0.15625,0) [0|0] "" Vector__XXX
 SG_ DAS_TR_Obj30_Dx m30 : 8|10@1+ (0.15625,0) [0|0] "" Vector__XXX
 SG_ DAS_TR_Obj31_Dx m31 : 8|10@1+ (0.15625,0) [0|0] "" Vector__XXX
 SG_ DAS_TR_Obj00_Dy m0 : 18|6@1+ (0.5,-15.5) [0|0] "" Vector__XXX
 SG_ DAS_TR_Obj01_Dy m1 : 18|6@1+ (0.5,-15.5) [0|0] "" Vector__XXX
 SG_ DAS_TR_Obj02_Dy m2 : 18|6@1+ (0.5,-15.5) [0|0] "" Vector__XXX
 SG_ DAS_TR_Obj03_Dy m3 : 18|6@1+ (0.5,-15.5) [0|0] "" Vector__XXX
 SG_ DAS_TR_Obj04_Dy m4 : 18|6@1+ (0.5,-15.5) [0|0] "" Vector__XXX
 SG_ DAS_TR_Obj05_Dy m5 : 18|6@1+ (0.5,-15.5) [0|0] "" Vector__XXX
 SG_ DAS_TR_Obj06_Dy m6 : 18|6@1+ (0.5,-15.5) [0|0] "" Vector__XXX
 SG_ DAS_TR_Obj07_Dy m7 : 18|6@1+ (0.5,-15.5) [0|0] "" Vector__XXX
 SG_ DAS_TR_Obj08_Dy m8 : 18|6@1+ (0.5,-15.5) [0|0] "" Vector__XXX
 SG_ DAS_TR_Obj09_Dy m9 : 18|6@1+ (0.5,-15.5) [0|0] "" Vector__XXX
 SG_ DAS_TR_Obj10_Dy m10 : 18|6@1+ (0.5,-15.5) [0|0] "" Vector__XXX
 SG_ DAS_TR_Obj11_Dy m11 : 18|6@1+ (0.5,-15.5) [0|0] "" Vector__XXX
 SG_ DAS_TR_Obj12_Dy m12 : 18|6@1+ (0.5,-15.5) [0|0] "" Vector__XXX
 SG_ DAS_TR_Obj13_Dy m13 : 18|6@1+ (0.5,-15.5) [0|0] "" Vector__XXX
 SG_ DAS_TR_Obj14_Dy m14 : 18|6@1+ (0.5,-15.5) [0|0] "" Vector__XXX
 SG_ DAS_TR_Obj15_Dy m15 : 18|6@1+ (0.5,-15.5) [0|0] "" Vector__XXX
 SG_ DAS_TR_Obj16_Dy m16 : 18|6@1+ (0.5,-15.5) [0|0] "" Vector__XXX
 SG_ DAS_TR_Obj17_Dy m17 : 18|6@1+ (0.5,-15.5) [0|0] "" Vector__XXX
 SG_ DAS_TR_Obj18_Dy m18 : 18|6@1+ (0.5,-15.5) [0|0] "" Vector__XXX
 SG_ DAS_TR_Obj19_Dy m19 : 18|6@1+ (0.5,-15.5) [0|0] "" Vector__XXX
 SG_ DAS_TR_Obj20_Dy m20 : 18|6@1+ (0.5,-15.5) [0|0] "" Vector__XXX
 SG_ DAS_TR_Obj21_Dy m21 : 18|6@1+ (0.5,-15.5) [0|0] "" Vector__XXX
 SG_ DAS_TR_Obj22_Dy m22 : 18|6@1+ (0.5,-15.5) [0|0] "" Vector__XXX
 SG_ DAS_TR_Obj23_Dy m23 : 18|6@1+ (0.5,-15.5) [0|0] "" Vector__XXX
 SG_ DAS_TR_Obj24_Dy m24 : 18|6@1+ (0.5,-15.5) [0|0] "" Vector__XXX
 SG_ DAS_TR_Obj25_Dy m25 : 18|6@1+ (0.5,-15.5) [0|0] "" Vector__XXX
 SG_ DAS_TR_Obj26_Dy m26 : 18|6@1+ (0.5,-15.5) [0|0] "" Vector__XXX
 SG_ DAS_TR_Obj27_Dy m27 : 18|6@1+ (0.5,-15.5) [0|0] "" Vector__XXX
 SG_ DAS_TR_Obj28_Dy m28 : 18|6@1+ (0.5,-15.5) [0|0] "" Vector__XXX
 SG_ DAS_TR_Obj29_Dy m29 : 18|6@1+ (0.5,-15.5) [0|0] "" Vector__XXX
 SG_ DAS_TR_Obj30_Dy m30 : 18|6@1+ (0.5,-15.5) [0|0] "" Vector__XXX
 SG_ DAS_TR_Obj31_Dy m31 : 18|6@1+ (0.5,-15.5) [0|0] "" Vector__XXX
 SG_ DAS_TR_Obj00_Vx m0 : 24|8@1+ (0.5,-63.5) [0|0] "" Vector__XXX
 SG_ DAS_TR_Obj01_Vx m1 : 24|8@1+ (0.5,-63.5) [0|0] "" Vector__XXX
 SG_ DAS_TR_Obj02_Vx m2 : 24|8@1+ (0.5,-63.5) [0|0] "" Vector__XXX
 SG_ DAS_TR_Obj03_Vx m3 : 24|8@1+ (0.5,-63.5) [0|0] "" Vector__XXX
 SG_ DAS_TR_Obj04_Vx m4 : 24|8@1+ (0.5,-63.5) [0|0] "" Vector__XXX
 SG_ DAS_TR_Obj05_Vx m5 : 24|8@1+ (0.5,-63.5) [0|0] "" Vector__XXX
 SG_ DAS_TR_Obj06_Vx m6 : 24|8@1+ (0.5,-63.5) [0|0] "" Vector__XXX
 SG_ DAS_TR_Obj07_Vx m7 : 24|8@1+ (0.5,-63.5) [0|0] "" Vector__XXX
 SG_ DAS_TR_Obj08_Vx m8 : 24|8@1+ (0.5,-63.5) [0|0] "" Vector__XXX
 SG_ DAS_TR_Obj09_Vx m9 : 24|8@1+ (0.5,-63.5) [0|0] "" Vector__XXX
 SG_ DAS_TR_Obj10_Vx m10 : 24|8@1+ (0.5,-63.5) [0|0] "" Vector__XXX
 SG_ DAS_TR_Obj11_Vx m11 : 24|8@1+ (0.5,-63.5) [0|0] "" Vector__XXX
 SG_ DAS_TR_Obj12_Vx m12 : 24|8@1+ (0.5,-63.5) [0|0] "" Vector__XXX
 SG_ DAS_TR_Obj13_Vx m13 : 24|8@1+ (0.5,-63.5) [0|0] "" Vector__XXX
 SG_ DAS_TR_Obj14_Vx m14 : 24|8@1+ (0.5,-63.5) [0|0] "" Vector__XXX
 SG_ DAS_TR_Obj15_Vx m15 : 24|8@1+ (0.5,-63.5) [0|0] "" Vector__XXX
 SG_ DAS_TR_Obj16_Vx m16 : 24|8@1+ (0.5,-63.5) [0|0] "" Vector__XXX
 SG_ DAS_TR_Obj17_Vx m17 : 24|8@1+ (0.5,-63.5) [0|0] "" Vector__XXX
 SG_ DAS_TR_Obj18_Vx m18 : 24|8@1+ (0.5,-63.5) [0|0] "" Vector__XXX
 SG_ DAS_TR_Obj19_Vx m19 : 24|8@1+ (0.5,-63.5) [0|0] "" Vector__XXX
 SG_ DAS_TR_Obj20_Vx m20 : 24|8@1+ (0.5,-63.5) [0|0] "" Vector__XXX
 SG_ DAS_TR_Obj21_Vx m21 : 24|8@1+ (0.5,-63.5) [0|0] "" Vector__XXX
 SG_ DAS_TR_Obj22_Vx m22 : 24|8@1+ (0.5,-63.5) [0|0] "" Vector__XXX
 SG_ DAS_TR_Obj23_Vx m23 : 24|8@1+ (0.5,-63.5) [0|0] "" Vector__XXX
 SG_ DAS_TR_Obj24_Vx m24 : 24|8@1+ (0.5,-63.5) [0|0] "" Vector__XXX
 SG_ DAS_TR_Obj25_Vx m25 : 24|8@1+ (0.5,-63.5) [0|0] "" Vector__XXX
 SG_ DAS_TR_Obj26_Vx m26 : 24|8@1+ (0.5,-63.5) [0|0] "" Vector__XXX
 SG_ DAS_TR_Obj27_Vx m27 : 24|8@1+ (0.5,-63.5) [0|0] "" Vector__XXX
 SG_ DAS_TR_Obj28_Vx m28 : 24|8@1+ (0.5,-63.5) [0|0] "" Vector__XXX
 SG_ DAS_TR_Obj29_Vx m29 : 24|8@1+ (0.5,-63.5) [0|0] "" Vector__XXX
 SG_ DAS_TR_Obj30_Vx m30 : 24|8@1+ (0.5,-63.5) [0|0] "" Vector__XXX
 SG_ DAS_TR_Obj31_Vx m31 : 24|8@1+ (0.5,-63.5) [0|0] "" Vector__XXX
 SG_ DAS_TR_Obj00_RCS m0 : 32|8@1+ (0.25,-14) [0|0] "" Vector__XXX
 SG_ DAS_TR_Obj01_RCS m1 : 32|8@1+ (0.25,-14) [0|0] "" Vector__XXX
 SG_ DAS_TR_Obj02_RCS m2 : 32|8@1+ (0.25,-14) [0|0] "" Vector__XXX
 SG_ DAS_TR_Obj03_RCS m3 : 32|8@1+ (0.25,-14) [0|0] "" Vector__XXX
 SG_ DAS_TR_Obj04_RCS m4 : 32|8@1+ (0.25,-14) [0|0] "" Vector__XXX
 SG_ DAS_TR_Obj05_RCS m5 : 32|8@1+ (0.25,-14) [0|0] "" Vector__XXX
 SG_ DAS_TR_Obj06_RCS m6 : 32|8@1+ (0.25,-14) [0|0] "" Vector__XXX
 SG_ DAS_TR_Obj07_RCS m7 : 32|8@1+ (0.25,-14) [0|0] "" Vector__XXX
 SG_ DAS_TR_Obj08_RCS m8 : 32|8@1+ (0.25,-14) [0|0] "" Vector__XXX
 SG_ DAS_TR_Obj09_RCS m9 : 32|8@1+ (0.25,-14) [0|0] "" Vector__XXX
 SG_ DAS_TR_Obj10_RCS m10 : 32|8@1+ (0.25,-14) [0|0] "" Vector__XXX
 SG_ DAS_TR_Obj11_RCS m11 : 32|8@1+ (0.25,-14) [0|0] "" Vector__XXX
 SG_ DAS_TR_Obj12_RCS m12 : 32|8@1+ (0.25,-14) [0|0] "" Vector__XXX
 SG_ DAS_TR_Obj13_RCS m13 : 32|8@1+ (0.25,-14) [0|0] "" Vector__XXX
 SG_ DAS_TR_Obj14_RCS m14 : 32|8@1+ (0.25,-14) [0|0] "" Vector__XXX
 SG_ DAS_TR_Obj15_RCS m15 : 32|8@1+ (0.25,-14) [0|0] "" Vector__XXX
 SG_ DAS_TR_Obj16_RCS m16 : 32|8@1+ (0.25,-14) [0|0] "" Vector__XXX
 SG_ DAS_TR_Obj17_RCS m17 : 32|8@1+ (0.25,-14) [0|0] "" Vector__XXX
 SG_ DAS_TR_Obj18_RCS m18 : 32|8@1+ (0.25,-14) [0|0] "" Vector__XXX
 SG_ DAS_TR_Obj19_RCS m19 : 32|8@1+ (0.25,-14) [0|0] "" Vector__XXX
 SG_ DAS_TR_Obj20_RCS m20 : 32|8@1+ (0.25,-14) [0|0] "" Vector__XXX
 SG_ DAS_TR_Obj21_RCS m21 : 32|8@1+ (0.25,-14) [0|0] "" Vector__XXX
 SG_ DAS_TR_Obj22_RCS m22 : 32|8@1+ (0.25,-14) [0|0] "" Vector__XXX
 SG_ DAS_TR_Obj23_RCS m23 : 32|8@1+ (0.25,-14) [0|0] "" Vector__XXX
 SG_ DAS_TR_Obj24_RCS m24 : 32|8@1+ (0.25,-14) [0|0] "" Vector__XXX
 SG_ DAS_TR_Obj25_RCS m25 : 32|8@1+ (0.25,-14) [0|0] "" Vector__XXX
 SG_ DAS_TR_Obj26_RCS m26 : 32|8@1+ (0.25,-14) [0|0] "" Vector__XXX
 SG_ DAS_TR_Obj27_RCS m27 : 32|8@1+ (0.25,-14) [0|0] "" Vector__XXX
 SG_ DAS_TR_Obj28_RCS m28 : 32|8@1+ (0.25,-14) [0|0] "" Vector__XXX
 SG_ DAS_TR_Obj29_RCS m29 : 32|8@1+ (0.25,-14) [0|0] "" Vector__XXX
 SG_ DAS_TR_Obj30_RCS m30 : 32|8@1+ (0.25,-14) [0|0] "" Vector__XXX
 SG_ DAS_TR_Obj31_RCS m31 : 32|8@1+ (0.25,-14) [0|0] "" Vector__XXX
 SG_ DAS_TR_Obj00_Length m0 : 40|6@1+ (0.125,0) [0|0] "" Vector__XXX
 SG_ DAS_TR_Obj01_Length m1 : 40|6@1+ (0.125,0) [0|0] "" Vector__XXX
 SG_ DAS_TR_Obj02_Length m2 : 40|6@1+ (0.125,0) [0|0] "" Vector__XXX
 SG_ DAS_TR_Obj03_Length m3 : 40|6@1+ (0.125,0) [0|0] "" Vector__XXX
 SG_ DAS_TR_Obj04_Length m4 : 40|6@1+ (0.125,0) [0|0] "" Vector__XXX
 SG_ DAS_TR_Obj05_Length m5 : 40|6@1+ (0.125,0) [0|0] "" Vector__XXX
 SG_ DAS_TR_Obj06_Length m6 : 40|6@1+ (0.125,0) [0|0] "" Vector__XXX
 SG_ DAS_TR_Obj07_Length m7 : 40|6@1+ (0.125,0) [0|0] "" Vector__XXX
 SG_ DAS_TR_Obj08_Length m8 : 40|6@1+ (0.125,0) [0|0] "" Vector__XXX
 SG_ DAS_TR_Obj09_Length m9 : 40|6@1+ (0.125,0) [0|0] "" Vector__XXX
 SG_ DAS_TR_Obj10_Length m10 : 40|6@1+ (0.125,0) [0|0] "" Vector__XXX
 SG_ DAS_TR_Obj11_Length m11 : 40|6@1+ (0.125,0) [0|0] "" Vector__XXX
 SG_ DAS_TR_Obj12_Length m12 : 40|6@1+ (0.125,0) [0|0] "" Vector__XXX
 SG_ DAS_TR_Obj13_Length m13 : 40|6@1+ (0.125,0) [0|0] "" Vector__XXX
 SG_ DAS_TR_Obj14_Length m14 : 40|6@1+ (0.125,0) [0|0] "" Vector__XXX
 SG_ DAS_TR_Obj15_Length m15 : 40|6@1+ (0.125,0) [0|0] "" Vector__XXX
 SG_ DAS_TR_Obj16_Length m16 : 40|6@1+ (0.125,0) [0|0] "" Vector__XXX
 SG_ DAS_TR_Obj17_Length m17 : 40|6@1+ (0.125,0) [0|0] "" Vector__XXX
 SG_ DAS_TR_Obj18_Length m18 : 40|6@1+ (0.125,0) [0|0] "" Vector__XXX
 SG_ DAS_TR_Obj19_Length m19 : 40|6@1+ (0.125,0) [0|0] "" Vector__XXX
 SG_ DAS_TR_Obj20_Length m20 : 40|6@1+ (0.125,0) [0|0] "" Vector__XXX
 SG_ DAS_TR_Obj21_Length m21 : 40|6@1+ (0.125,0) [0|0] "" Vector__XXX
 SG_ DAS_TR_Obj22_Length m22 : 40|6@1+ (0.125,0) [0|0] "" Vector__XXX
 SG_ DAS_TR_Obj23_Length m23 : 40|6@1+ (0.125,0) [0|0] "" Vector__XXX
 SG_ DAS_TR_Obj24_Length m24 : 40|6@1+ (0.125,0) [0|0] "" Vector__XXX
 SG_ DAS_TR_Obj25_Length m25 : 40|6@1+ (0.125,0) [0|0] "" Vector__XXX
 SG_ DAS_TR_Obj26_Length m26 : 40|6@1+ (0.125,0) [0|0] "" Vector__XXX
 SG_ DAS_TR_Obj27_Length m27 : 40|6@1+ (0.125,0) [0|0] "" Vector__XXX
 SG_ DAS_TR_Obj28_Length m28 : 40|6@1+ (0.125,0) [0|0] "" Vector__XXX
 SG_ DAS_TR_Obj29_Length m29 : 40|6@1+ (0.125,0) [0|0] "" Vector__XXX
 SG_ DAS_TR_Obj30_Length m30 : 40|6@1+ (0.125,0) [0|0] "" Vector__XXX
 SG_ DAS_TR_Obj31_Length m31 : 40|6@1+ (0.125,0) [0|0] "" Vector__XXX
 SG_ DAS_TR_Obj00_MovingState m0 : 46|2@1+ (1,0) [0|0] "" Vector__XXX
 SG_ DAS_TR_Obj01_MovingState m1 : 46|2@1+ (1,0) [0|0] "" Vector__XXX
 SG_ DAS_TR_Obj02_MovingState m2 : 46|2@1+ (1,0) [0|0] "" Vector__XXX
 SG_ DAS_TR_Obj03_MovingState m3 : 46|2@1+ (1,0) [0|0] "" Vector__XXX
 SG_ DAS_TR_Obj04_MovingState m4 : 46|2@1+ (1,0) [0|0] "" Vector__XXX
 SG_ DAS_TR_Obj05_MovingState m5 : 46|2@1+ (1,0) [0|0] "" Vector__XXX
 SG_ DAS_TR_Obj06_MovingState m6 : 46|2@1+ (1,0) [0|0] "" Vector__XXX
 SG_ DAS_TR_Obj07_MovingState m7 : 46|2@1+ (1,0) [0|0] "" Vector__XXX
 SG_ DAS_TR_Obj08_MovingState m8 : 46|2@1+ (1,0) [0|0] "" Vector__XXX
 SG_ DAS_TR_Obj09_MovingState m9 : 46|2@1+ (1,0) [0|0] "" Vector__XXX
 SG_ DAS_TR_Obj10_MovingState m10 : 46|2@1+ (1,0) [0|0] "" Vector__XXX
 SG_ DAS_TR_Obj11_MovingState m11 : 46|2@1+ (1,0) [0|0] "" Vector__XXX
 SG_ DAS_TR_Obj12_MovingState m12 : 46|2@1+ (1,0) [0|0] "" Vector__XXX
 SG_ DAS_TR_Obj13_MovingState m13 : 46|2@1+ (1,0) [0|0] "" Vector__XXX
 SG_ DAS_TR_Obj14_MovingState m14 : 46|2@1+ (1,0) [0|0] "" Vector__XXX
 SG_ DAS_TR_Obj15_MovingState m15 : 46|2@1+ (1,0) [0|0] "" Vector__XXX
 SG_ DAS_TR_Obj16_MovingState m16 : 46|2@1+ (1,0) [0|0] "" Vector__XXX
 SG_ DAS_TR_Obj17_MovingState m17 : 46|2@1+ (1,0) [0|0] "" Vector__XXX
 SG_ DAS_TR_Obj18_MovingState m18 : 46|2@1+ (1,0) [0|0] "" Vector__XXX
 SG_ DAS_TR_Obj19_MovingState m19 : 46|2@1+ (1,0) [0|0] "" Vector__XXX
 SG_ DAS_TR_Obj20_MovingState m20 : 46|2@1+ (1,0) [0|0] "" Vector__XXX
 SG_ DAS_TR_Obj21_MovingState m21 : 46|2@1+ (1,0) [0|0] "" Vector__XXX
 SG_ DAS_TR_Obj22_MovingState m22 : 46|2@1+ (1,0) [0|0] "" Vector__XXX
 SG_ DAS_TR_Obj23_MovingState m23 : 46|2@1+ (1,0) [0|0] "" Vector__XXX
 SG_ DAS_TR_Obj24_MovingState m24 : 46|2@1+ (1,0) [0|0] "" Vector__XXX
 SG_ DAS_TR_Obj25_MovingState m25 : 46|2@1+ (1,0) [0|0] "" Vector__XXX
 SG_ DAS_TR_Obj26_MovingState m26 : 46|2@1+ (1,0) [0|0] "" Vector__XXX
 SG_ DAS_TR_Obj27_MovingState m27 : 46|2@1+ (1,0) [0|0] "" Vector__XXX
 SG_ DAS_TR_Obj28_MovingState m28 : 46|2@1+ (1,0) [0|0] "" Vector__XXX
 SG_ DAS_TR_Obj29_MovingState m29 : 46|2@1+ (1,0) [0|0] "" Vector__XXX
 SG_ DAS_TR_Obj30_MovingState m30 : 46|2@1+ (1,0) [0|0] "" Vector__XXX
 SG_ DAS_TR_Obj31_MovingState m31 : 46|2@1+ (1,0) [0|0] "" Vector__XXX
 SG_ DAS_TR_Obj00_Dz m0 : 48|6@1+ (0.25,-5) [0|0] "" Vector__XXX
 SG_ DAS_TR_Obj01_Dz m1 : 48|6@1+ (0.25,-5) [0|0] "" Vector__XXX
 SG_ DAS_TR_Obj02_Dz m2 : 48|6@1+ (0.25,-5) [0|0] "" Vector__XXX
 SG_ DAS_TR_Obj03_Dz m3 : 48|6@1+ (0.25,-5) [0|0] "" Vector__XXX
 SG_ DAS_TR_Obj04_Dz m4 : 48|6@1+ (0.25,-5) [0|0] "" Vector__XXX
 SG_ DAS_TR_Obj05_Dz m5 : 48|6@1+ (0.25,-5) [0|0] "" Vector__XXX
 SG_ DAS_TR_Obj06_Dz m6 : 48|6@1+ (0.25,-5) [0|0] "" Vector__XXX
 SG_ DAS_TR_Obj07_Dz m7 : 48|6@1+ (0.25,-5) [0|0] "" Vector__XXX
 SG_ DAS_TR_Obj08_Dz m8 : 48|6@1+ (0.25,-5) [0|0] "" Vector__XXX
 SG_ DAS_TR_Obj09_Dz m9 : 48|6@1+ (0.25,-5) [0|0] "" Vector__XXX
 SG_ DAS_TR_Obj10_Dz m10 : 48|6@1+ (0.25,-5) [0|0] "" Vector__XXX
 SG_ DAS_TR_Obj11_Dz m11 : 48|6@1+ (0.25,-5) [0|0] "" Vector__XXX
 SG_ DAS_TR_Obj12_Dz m12 : 48|6@1+ (0.25,-5) [0|0] "" Vector__XXX
 SG_ DAS_TR_Obj13_Dz m13 : 48|6@1+ (0.25,-5) [0|0] "" Vector__XXX
 SG_ DAS_TR_Obj14_Dz m14 : 48|6@1+ (0.25,-5) [0|0] "" Vector__XXX
 SG_ DAS_TR_Obj15_Dz m15 : 48|6@1+ (0.25,-5) [0|0] "" Vector__XXX
 SG_ DAS_TR_Obj16_Dz m16 : 48|6@1+ (0.25,-5) [0|0] "" Vector__XXX
 SG_ DAS_TR_Obj17_Dz m17 : 48|6@1+ (0.25,-5) [0|0] "" Vector__XXX
 SG_ DAS_TR_Obj18_Dz m18 : 48|6@1+ (0.25,-5) [0|0] "" Vector__XXX
 SG_ DAS_TR_Obj19_Dz m19 : 48|6@1+ (0.25,-5) [0|0] "" Vector__XXX
 SG_ DAS_TR_Obj20_Dz m20 : 48|6@1+ (0.25,-5) [0|0] "" Vector__XXX
 SG_ DAS_TR_Obj21_Dz m21 : 48|6@1+ (0.25,-5) [0|0] "" Vector__XXX
 SG_ DAS_TR_Obj22_Dz m22 : 48|6@1+ (0.25,-5) [0|0] "" Vector__XXX
 SG_ DAS_TR_Obj23_Dz m23 : 48|6@1+ (0.25,-5) [0|0] "" Vector__XXX
 SG_ DAS_TR_Obj24_Dz m24 : 48|6@1+ (0.25,-5) [0|0] "" Vector__XXX
 SG_ DAS_TR_Obj25_Dz m25 : 48|6@1+ (0.25,-5) [0|0] "" Vector__XXX
 SG_ DAS_TR_Obj26_Dz m26 : 48|6@1+ (0.25,-5) [0|0] "" Vector__XXX
 SG_ DAS_TR_Obj27_Dz m27 : 48|6@1+ (0.25,-5) [0|0] "" Vector__XXX
 SG_ DAS_TR_Obj28_Dz m28 : 48|6@1+ (0.25,-5) [0|0] "" Vector__XXX
 SG_ DAS_TR_Obj29_Dz m29 : 48|6@1+ (0.25,-5) [0|0] "" Vector__XXX
 SG_ DAS_TR_Obj30_Dz m30 : 48|6@1+ (0.25,-5) [0|0] "" Vector__XXX
 SG_ DAS_TR_Obj31_Dz m31 : 48|6@1+ (0.25,-5) [0|0] "" Vector__XXX
 SG_ DAS_TR_Counter : 54|2@1+ (1,0) [0|0] "" Vector__XXX
 SG_ DAS_TR_Obj00_Exist m0 : 56|5@1+ (3.125,0) [0|0] "" Vector__XXX
 SG_ DAS_TR_Obj01_Exist m1 : 56|5@1+ (3.125,0) [0|0] "" Vector__XXX
 SG_ DAS_TR_Obj02_Exist m2 : 56|5@1+ (3.125,0) [0|0] "" Vector__XXX
 SG_ DAS_TR_Obj03_Exist m3 : 56|5@1+ (3.125,0) [0|0] "" Vector__XXX
 SG_ DAS_TR_Obj04_Exist m4 : 56|5@1+ (3.125,0) [0|0] "" Vector__XXX
 SG_ DAS_TR_Obj05_Exist m5 : 56|5@1+ (3.125,0) [0|0] "" Vector__XXX
 SG_ DAS_TR_Obj06_Exist m6 : 56|5@1+ (3.125,0) [0|0] "" Vector__XXX
 SG_ DAS_TR_Obj07_Exist m7 : 56|5@1+ (3.125,0) [0|0] "" Vector__XXX
 SG_ DAS_TR_Obj08_Exist m8 : 56|5@1+ (3.125,0) [0|0] "" Vector__XXX
 SG_ DAS_TR_Obj09_Exist m9 : 56|5@1+ (3.125,0) [0|0] "" Vector__XXX
 SG_ DAS_TR_Obj10_Exist m10 : 56|5@1+ (3.125,0) [0|0] "" Vector__XXX
 SG_ DAS_TR_Obj11_Exist m11 : 56|5@1+ (3.125,0) [0|0] "" Vector__XXX
 SG_ DAS_TR_Obj12_Exist m12 : 56|5@1+ (3.125,0) [0|0] "" Vector__XXX
 SG_ DAS_TR_Obj13_Exist m13 : 56|5@1+ (3.125,0) [0|0] "" Vector__XXX
 SG_ DAS_TR_Obj14_Exist m14 : 56|5@1+ (3.125,0) [0|0] "" Vector__XXX
 SG_ DAS_TR_Obj15_Exist m15 : 56|5@1+ (3.125,0) [0|0] "" Vector__XXX
 SG_ DAS_TR_Obj16_Exist m16 : 56|5@1+ (3.125,0) [0|0] "" Vector__XXX
 SG_ DAS_TR_Obj17_Exist m17 : 56|5@1+ (3.125,0) [0|0] "" Vector__XXX
 SG_ DAS_TR_Obj18_Exist m18 : 56|5@1+ (3.125,0) [0|0] "" Vector__XXX
 SG_ DAS_TR_Obj19_Exist m19 : 56|5@1+ (3.125,0) [0|0] "" Vector__XXX
 SG_ DAS_TR_Obj20_Exist m20 : 56|5@1+ (3.125,0) [0|0] "" Vector__XXX
 SG_ DAS_TR_Obj21_Exist m21 : 56|5@1+ (3.125,0) [0|0] "" Vector__XXX
 SG_ DAS_TR_Obj22_Exist m22 : 56|5@1+ (3.125,0) [0|0] "" Vector__XXX
 SG_ DAS_TR_Obj23_Exist m23 : 56|5@1+ (3.125,0) [0|0] "" Vector__XXX
 SG_ DAS_TR_Obj24_Exist m24 : 56|5@1+ (3.125,0) [0|0] "" Vector__XXX
 SG_ DAS_TR_Obj25_Exist m25 : 56|5@1+ (3.125,0) [0|0] "" Vector__XXX
 SG_ DAS_TR_Obj26_Exist m26 : 56|5@1+ (3.125,0) [0|0] "" Vector__XXX
 SG_ DAS_TR_Obj27_Exist m27 : 56|5@1+ (3.125,0) [0|0] "" Vector__XXX
 SG_ DAS_TR_Obj28_Exist m28 : 56|5@1+ (3.125,0) [0|0] "" Vector__XXX
 SG_ DAS_TR_Obj29_Exist m29 : 56|5@1+ (3.125,0) [0|0] "" Vector__XXX
 SG_ DAS_TR_Obj30_Exist m30 : 56|5@1+ (3.125,0) [0|0] "" Vector__XXX
 SG_ DAS_TR_Obj31_Exist m31 : 56|5@1+ (3.125,0) [0|0] "" Vector__XXX

BO_ 1569 UI_weatherDataService: 8 Vector__XXX
 SG_ UI_weatherSvcTimeSinceLast : 0|11@1+ (1,0) [0|0] "" Vector__XXX
 SG_ UI_weatherSvcTemperature : 16|8@1- (0.5,0) [0|0] "" Vector__XXX
 SG_ UI_weatherSvcHumidity : 24|8@1+ (0.5,0) [0|0] "" Vector__XXX
 SG_ UI_weatherSvcDewPoint : 32|8@1+ (0.5,0) [0|0] "" Vector__XXX
 SG_ UI_weatherSvcCloudCover : 40|8@1+ (0.5,0) [0|0] "" Vector__XXX
 SG_ UI_weatherSvcPrecipProb : 48|8@1+ (0.5,0) [0|0] "" Vector__XXX
 SG_ UI_weatherSvcRaining : 56|1@1+ (1,0) [0|0] "" Vector__XXX
 SG_ UI_weatherSvcSnowing : 57|1@1+ (1,0) [0|0] "" Vector__XXX

BO_ 1584 UDS_epas3pRequest: 12 Vector__XXX
 SG_ UDS_epas3pRequestData : 7|64@0+ (1,0) [0|0] "" Vector__XXX

BO_ 1585 RADC_bootID: 12 Vector__XXX
 SG_ RADC_componentID : 7|16@0+ (1,0) [0|0] "" Vector__XXX
 SG_ RADC_pcbaID : 23|8@0+ (1,0) [0|0] "" Vector__XXX
 SG_ RADC_assemblyID : 31|8@0+ (1,0) [0|0] "" Vector__XXX
 SG_ RADC_usageID : 39|16@0+ (1,0) [0|0] "" Vector__XXX
 SG_ RADC_firmwareType : 63|8@0+ (1,0) [0|0] "" Vector__XXX

BO_ 1592 EPAS3P_udsResponseCH: 12 Vector__XXX
 SG_ EPAS3P_udsResponseDataCH : 7|64@0+ (1,0) [0|0] "" Vector__XXX

BO_ 1593 DAS_bootID: 12 Vector__XXX
 SG_ DAS_componentID : 7|16@0+ (1,0) [0|0] "" Vector__XXX
 SG_ DAS_pcbaID : 23|8@0+ (1,0) [0|0] "" Vector__XXX
 SG_ DAS_assemblyID : 31|8@0+ (1,0) [0|0] "" Vector__XXX
 SG_ DAS_usageID : 39|16@0+ (1,0) [0|0] "" Vector__XXX
 SG_ DAS_firmwareType : 63|8@0+ (1,0) [0|0] "" Vector__XXX

BO_ 1601 UDS_rcmRequest: 12 Vector__XXX
 SG_ UDS_rcmRequestData : 7|64@0+ (1,0) [0|0] "" Vector__XXX

BO_ 1603 UDS_ocs1pRequest: 12 Vector__XXX
 SG_ UDS_ocs1pRequestData : 7|64@0+ (1,0) [0|0] "" Vector__XXX

BO_ 1605 UDS_espRequest: 12 Vector__XXX
 SG_ UDS_espRequestData : 7|64@0+ (1,0) [0|0] "" Vector__XXX

BO_ 1606 ESP_bootID: 8 Vector__XXX
 SG_ ESP_bootIdData : 0|64@1+ (1,0) [0|0] "" Vector__XXX

BO_ 1609 UDS_dasRequest: 12 Vector__XXX
 SG_ UDS_dasRequestData : 7|64@0+ (1,0) [0|0] "" Vector__XXX

BO_ 1613 UDS_ibstRequest: 12 Vector__XXX
 SG_ UDS_ibstRequestData : 7|64@0+ (1,0) [0|0] "" Vector__XXX

BO_ 1614 UDS_parkRequest: 12 Vector__XXX
 SG_ UDS_parkRequestData : 7|64@0+ (1,0) [0|0] "" Vector__XXX

BO_ 1615 UDS_tpmsRequest: 12 Vector__XXX
 SG_ UDS_tpmsRequestData : 7|64@0+ (1,0) [0|0] "" Vector__XXX

BO_ 1617 RCM_udsResponse: 12 Vector__XXX
 SG_ RCM_udsResponseData : 7|64@0+ (1,0) [0|0] "" Vector__XXX

BO_ 1619 OCS1P_udsResponse: 8 Vector__XXX
 SG_ OCS1P_udsResponseData : 0|64@1+ (1,0) [0|0] "" Vector__XXX

BO_ 1621 ESP_udsResponse: 12 Vector__XXX
 SG_ ESP_udsResponseData : 7|64@0+ (1,0) [0|0] "" Vector__XXX

BO_ 1625 DAS_udsResponse: 12 Vector__XXX
 SG_ DAS_udsResponseData : 7|64@0+ (1,0) [0|0] "" Vector__XXX

BO_ 1629 IBST_udsResponse: 12 Vector__XXX
 SG_ IBST_udsResponseData : 7|64@0+ (1,0) [0|0] "" Vector__XXX

BO_ 1630 PARK_udsResponse: 8 Vector__XXX
 SG_ PARK_udsResponseData : 0|64@1+ (1,0) [0|0] "" Vector__XXX

BO_ 1631 TPMS_udsResponse: 12 Vector__XXX
 SG_ TPMS_udsResponseData : 7|64@0+ (1,0) [0|0] "" Vector__XXX

BO_ 1637 XCP_epasRequest: 12 Vector__XXX
 SG_ XCP_epasRequestData : 7|64@0+ (1,0) [0|0] "" Vector__XXX

BO_ 1639 EPAS3S_xcpResponse: 12 Vector__XXX
 SG_ EPAS3S_xcpResponseData : 7|64@0+ (1,0) [0|0] "" Vector__XXX

BO_ 1645 IBST_bootID: 8 Vector__XXX
 SG_ IBST_bootIdData : 0|64@1+ (1,0) [0|0] "" Vector__XXX

BO_ 1649 UDS_radcRequest: 12 Vector__XXX
 SG_ UDS_radcRequestData : 7|64@0+ (1,0) [0|0] "" Vector__XXX

BO_ 1655 VC_LVBMS_statusHigh: 8 Vector__XXX
 SG_ VC_lvbmsStatusHighIndex M : 0|3@1+ (1,0) [0|0] "" Vector__XXX
 SG_ VC_LVBMS_MOSCommand m4 : 3|1@1+ (1,0) [0|0] "" Vector__XXX
 SG_ VC_LVBMS_packCurrent m0 : 3|22@1+ (0.001,-2000) [0|0] "" Vector__XXX
 SG_ VC_LVBMS_voltageTarget m3 : 3|16@1+ (0.001,0) [0|0] "" Vector__XXX
 SG_ VC_LVBMS_ClearErrorCntrCommand m4 : 4|1@1+ (1,0) [0|0] "" Vector__XXX
 SG_ VC_LVBMS_ClearHistoricFaultCommand m4 : 5|1@1+ (1,0) [0|0] "" Vector__XXX
 SG_ VC_LVBMS_ResetLVBMSCommand m4 : 6|1@1+ (1,0) [0|0] "" Vector__XXX
 SG_ VC_LVBMS_EnterHibernationCommand m4 : 7|1@1+ (1,0) [0|0] "" Vector__XXX
 SG_ VC_LVBMS_ECPAState m4 : 8|2@1+ (1,0) [0|0] "" Vector__XXX
 SG_ VC_LVBMS_sumCellVoltage m1 : 8|16@1+ (0.001,0) [0|0] "" Vector__XXX
 SG_ VC_totalLVLoadCurrent m2 : 8|14@1- (0.1,0) [0|0] "" Vector__XXX
 SG_ VC_LVBMS_MOSState m4 : 10|2@1+ (1,0) [0|0] "" Vector__XXX
 SG_ VC_LVBMS_VehicleState m4 : 12|2@1+ (1,0) [0|0] "" Vector__XXX
 SG_ VC_LVBMS_LINWakeDisabled m4 : 14|1@1+ (1,0) [0|0] "" Vector__XXX
 SG_ VC_LVBMS_chargeType m4 : 16|3@1+ (1,0) [0|0] "" Vector__XXX
 SG_ VC_LVBMS_cellAndArcProtEnabled m4 : 19|1@1+ (1,0) [0|0] "" Vector__XXX
 SG_ VC_LVBMS_currentTarget m3 : 19|18@1+ (0.001,-122) [0|0] "" Vector__XXX
 SG_ VC_LVPackChargeCurrentLimit m2 : 22|12@1+ (0.1,0) [0|0] "" Vector__XXX
 SG_ VC_LVBMS_avgBrickVoltage m4 : 24|13@1+ (0.001,0) [0|0] "" Vector__XXX
 SG_ VC_LVBMS_maxBrickVoltage m1 : 24|13@1+ (0.001,0) [0|0] "" Vector__XXX
 SG_ VC_LVBMS_packVoltage m0 : 25|16@1+ (0.001,0) [0|0] "" Vector__XXX
 SG_ VC_LVPackCurrent m2 : 34|14@1- (0.1,0) [0|0] "" Vector__XXX
 SG_ VC_LVBMS_maxAllowedChargeCurrent m3 : 37|13@1+ (0.1,0) [0|0] "" Vector__XXX
 SG_ VC_LVBMS_maxBrickVoltageIndex m1 : 40|8@1+ (1,0) [0|0] "" Vector__XXX
 SG_ VC_LVBMS_minBrickVoltage m4 : 40|13@1+ (0.001,0) [0|0] "" Vector__XXX
 SG_ VC_LVBMS_packTemperature m0 : 41|9@1+ (0.5,-50) [0|0] "" Vector__XXX
 SG_ VC_LVBMS_estimatedPackOcv m2 : 48|16@1+ (0.001,0) [0|0] "" Vector__XXX
 SG_ VC_LVBMS_MOSTemperature m0 : 50|12@1+ (0.5,-50) [0|0] "" Vector__XXX
 SG_ VC_LVBMS_maxAllowedDischargeCurrent m3 : 50|13@1+ (0.1,0) [0|0] "" Vector__XXX
 SG_ VC_LVBMS_minBrickVoltageIndex m4 : 56|8@1+ (1,0) [0|0] "" Vector__XXX

BO_ 1665 RADC_udsResponse: 12 Vector__XXX
 SG_ RADC_udsResponseData : 7|64@0+ (1,0) [0|0] "" Vector__XXX

BO_ 1801 DBG_IsotermAP: 12 Vector__XXX
 SG_ DBG_IsotermAP : 7|64@0+ (1,0) [0|0] "" Vector__XXX

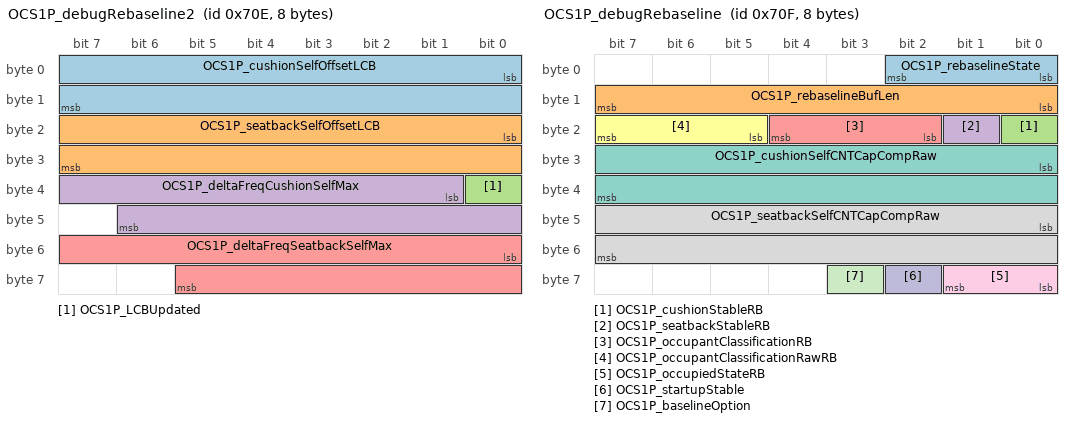
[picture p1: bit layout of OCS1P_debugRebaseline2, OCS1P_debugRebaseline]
BO_ 1806 OCS1P_debugRebaseline2: 8 Vector__XXX
 SG_ OCS1P_cushionSelfOffsetLCB : 0|16@1- (0.005,0) [0|0] "" Vector__XXX
 SG_ OCS1P_seatbackSelfOffsetLCB : 16|16@1- (0.005,0) [0|0] "" Vector__XXX
 SG_ OCS1P_LCBUpdated : 32|1@1+ (1,0) [0|0] "" Vector__XXX
 SG_ OCS1P_deltaFreqCushionSelfMax : 33|14@1- (10,0) [0|0] "" Vector__XXX
 SG_ OCS1P_deltaFreqSeatbackSelfMax : 48|14@1- (10,0) [0|0] "" Vector__XXX

BO_ 1807 OCS1P_debugRebaseline: 8 Vector__XXX
 SG_ OCS1P_rebaselineState : 0|3@1+ (1,0) [0|0] "" Vector__XXX
 SG_ OCS1P_rebaselineBufLen : 8|8@1+ (1,0) [0|0] "" Vector__XXX
 SG_ OCS1P_cushionStableRB : 16|1@1+ (1,0) [0|0] "" Vector__XXX
 SG_ OCS1P_seatbackStableRB : 17|1@1+ (1,0) [0|0] "" Vector__XXX
 SG_ OCS1P_occupantClassificationRB : 18|3@1+ (1,0) [0|0] "" Vector__XXX
 SG_ OCS1P_occupantClassificationRawRB : 21|3@1+ (1,0) [0|0] "" Vector__XXX
 SG_ OCS1P_cushionSelfCNTCapCompRaw : 24|16@1+ (0.005,0) [0|0] "" Vector__XXX
 SG_ OCS1P_seatbackSelfCNTCapCompRaw : 40|16@1+ (0.005,0) [0|0] "" Vector__XXX
 SG_ OCS1P_occupiedStateRB : 56|2@1+ (1,0) [0|0] "" Vector__XXX
 SG_ OCS1P_startupStable : 58|1@1+ (1,0) [0|0] "" Vector__XXX
 SG_ OCS1P_baselineOption : 59|1@1+ (1,0) [0|0] "" Vector__XXX

BO_ 1815 RCM_imuOffsets: 8 Vector__XXX
 SG_ RCM_imuOffsetsIndex M : 0|2@1+ (1,0) [0|0] "" Vector__XXX
 SG_ RCM_CGXdistance m2 : 8|16@1+ (1,-32768) [0|0] "" Vector__XXX
 SG_ RCM_longitudinalAccelOffset m1 : 8|16@1- (0.00125,0) [0|0] "" Vector__XXX
 SG_ RCM_yawRateOffset m0 : 8|16@1- (0.0001,0) [0|0] "" Vector__XXX
 SG_ RCM_CGYdistance m2 : 24|16@1+ (1,-32768) [0|0] "" Vector__XXX
 SG_ RCM_lateralAccelOffset m1 : 24|16@1- (0.00125,0) [0|0] "" Vector__XXX
 SG_ RCM_pitchRateOffset m0 : 24|16@1- (0.0001,0) [0|0] "" Vector__XXX
 SG_ RCM_CGZdistance m2 : 40|16@1+ (1,-32768) [0|0] "" Vector__XXX
 SG_ RCM_rollRateOffset m0 : 40|16@1- (0.0001,0) [0|0] "" Vector__XXX
 SG_ RCM_verticalAccelOffset m1 : 40|16@1- (0.00125,0) [0|0] "" Vector__XXX

BO_ 1817 DAS_IsotermAP: 12 Vector__XXX
 SG_ DAS_IsotermAP : 7|64@0+ (1,0) [0|0] "" Vector__XXX

VAL_ 1520 USM_alertID 0 "ALERT_DO_NOT_USE_ZERO" 1 "a001_DriverDoorOpen" 2 "a002_DoorOpen" 3 "a003_TrunkOpen" 4 "a004_FrunkOpen" 5 "a005_HeadlightsOnDoorOpen" 6 "a006_RemoteServiceAlert" 7 "a007_SoftPackConfigMismatch" 8 "a008_TouchScreenError" 9 "a009_SquashfsError" 10 "a010_MapsMissing" 11 "a011_IncorrectMap" 12 "a012_NotOnPrivateProperty" 13 "a013_TPMSHardWarning" 14 "a014_TPMSSoftWarning" 15 "a015_TPMSOverPressureWarning" 16 "a016_TPMSTemperatureWarning" 17 "a017_TPMSSystemFault" 18 "a018_SlipStartOn" 19 "a019_ParkBrakeFault" 20 "a020_SteeringReduced" 21 "a021_RearSeatbeltUnbuckled" 22 "a022_ApeFusesEtc" 23 "a023_CellInternetCheckFailed" 24 "a024_WifiInternetCheckFailed" 25 "a025_WifiOnlineCheckFailed" 26 "a026_ModemResetLoopDetected" 27 "a027_AutoSteerMIA" 28 "a028_FrontTrunkPopupClosed" 29 "a029_ModemMIA" 30 "a030_ModemVMCrash" 31 "a031_BrakeFluidLow" 32 "a032_CellModemRecoveryResets" 33 "a033_ApTrialExpired" 34 "a034_WakeupProblem" 35 "a035_AudioWatchdogKernelError" 36 "a036_AudioWatchdogHfpError" 37 "a037_AudioWatchdogXrunStormError" 38 "a038_AudioWatchdogA2bI2cLockupError" 39 "a039_AudioA2bNeedRediscovery" 40 "a040_HomelinkTransmit" 41 "a041_AudioDmesgXrun" 42 "a042_AudioDmesgRtThrottling" 43 "a043_InvalidMapDataOverride" 44 "a044_AudioDmesgDspException" 45 "a045_ECallNeedsService" 46 "a046_BackupCameraStreamError" 47 "a047_CellRoamingDisallowed" 48 "a048_AudioPremiumAmpCheckFailed" 49 "a049_BrakeShiftRequired" 50 "a050_BackupCameraIPUTimeout" 51 "a051_BackupCameraFrameTimeout" 52 "a052_KernelPanicReported" 53 "a053_QtCarExitError" 54 "a054_AudioBoostPowerBad" 55 "a055_ManualECallDisabled" 56 "a056_ManualECallButtonDisconnected" 57 "a057_CellAntennaDisconnected" 58 "a058_GPSAntennaDisconnected" 59 "a059_ECallSpeakerDisconnected" 60 "a060_ECallMicDisconnected" 61 "a061_SIMTestFailed" 62 "a062_ENSTestFailed" 63 "a063_CellularTestFailed" 64 "a064_ModemFirmwareTestFailed" 65 "a065_WiFiRecoveryReset" 66 "a066_GpuHangDetected" 67 "a067_WarnOnI915" 68 "a068_VideoUnexpectedExit" 69 "a069_VideoUDPTimeout" 70 "a070_VideoPipelineWarning" 71 "a071_VideoPipelineError" 72 "a072_ECallAnalogMicFailed" 73 "a073_ECallDigitalMicFailed" 74 "a074_EMMCHangDetected" 75 "a075_BackupCameraInitError" 76 "a076_NumFalseManualECalls" 77 "a077_AudioA2bMicChannelSwap" 78 "a078_DashcamUsbDriveUnmountable" 79 "a079_DashcamUsbDriveFull" 80 "a080_DashcamUsbDriveSlow" 81 "a081_CellModemSearchExpired" 82 "a082_NumModemRebootStuckInECall" 83 "a083_ECallProxyWatchdogTriggered" 84 "a084_SerializerError" 85 "a085_DeserializerError" 86 "a086_TouchEnumerationError" 87 "a087_BmpReset" 88 "a088_CellRemovableSimMissing" 89 "a089_RadioSoftResetError" 90 "a090_RadioPingFailError" 91 "a091_VehicleLinkStall" 92 "a092_updateStarted" 93 "a093_updateEnded" 94 "a094_ModemPowerOnFailure" 95 "a095_CidStorageRunningLow" 96 "a096_VideodPipelineIssueDetected" 97 "a097_AudiodRestarted" 98 "a098_DiskCheckFailure" 99 "a099_eMMCStatusError" 100 "a100_eMMCFTLError" 101 "a101_wifiStackProblem" 102 "a102_A2bDiscoveryFailed" 103 "a103_UsbHubNotEnumerating" 104 "a104_DashcamUsbDriveMissing" 105 "a105_firmwareReinstallRequested" 106 "a106_rebootBackstopTriggered" 107 "a107_DashcamUsbDriveTooBigForVfatFsck" 108 "a108_DashcamUsbDriveGettingFull" 109 "a109_DashcamUsbDriveTooSmall" 110 "a110_DashcamUsbDriveCorrupt" 111 "a111_DashcamUsbDriveWrongPort" 112 "a112_badUSBDevice" 113 "a113_DashcamHasOnboardSentryClips" ;
VAL_ 1520 USM_alertState 0 "CLEARED" 1 "SET" ;
VAL_ 1520 USM_a031_uds_bytes_0 0 "0" 1 "1" 2 "2" 3 "3" 4 "4" 5 "5" 6 "6" 7 "7" 8 "8" 9 "9" 10 "10" 11 "11" 12 "12" 13 "13" 14 "14" 15 "15" 16 "16" 17 "17" 18 "18" 19 "19" 20 "20" 21 "21" 22 "22" 23 "23" 24 "24" 25 "25" 26 "26" 27 "27" 28 "28" 29 "29" 30 "30" 31 "31" ;
VAL_ 1520 USM_a096_VEH_status 0 "DISABLED" 1 "ENABLED" 2 "TEMPORARY_FAILURE" 3 "SNA" ;
VAL_ 1520 USM_a101_VEH_state 0 "STANDBY" 1 "DRIVE" 2 "SUPPORT" 3 "CHARGE" 4 "FEIM" 5 "CLEAR_FAULT" 6 "FAULT" 7 "WELD" 8 "TEST" 9 "SNA" 10 "DIAG" ;
VAL_ 1520 USM_a109_PARTY_status 0 "DISABLED" 1 "ENABLED" 2 "TEMPORARY_FAILURE" 3 "SNA" ;
VAL_ 1520 USM_a114_PARTY_status 0 "DISABLED" 1 "ENABLED" 2 "TEMPORARY_FAILURE" 3 "SNA" ;
VAL_ 1520 USM_a089_PARTY_status 0 "DISABLED" 1 "ENABLED" 2 "TEMPORARY_FAILURE" 3 "SNA" ;
VAL_ 1520 USM_a090_VEH_state 0 "STANDBY" 1 "DRIVE" 2 "SUPPORT" 3 "CHARGE" 4 "FEIM" 5 "CLEAR_FAULT" 6 "FAULT" 7 "WELD" 8 "TEST" 9 "SNA" 10 "DIAG" ;
VAL_ 1520 USM_a095_PT_status 0 "DISABLED" 1 "ENABLED" 2 "TEMPORARY_FAILURE" 3 "SNA" ;
VAL_ 1520 USM_a096_CH_status 0 "DISABLED" 1 "ENABLED" 2 "TEMPORARY_FAILURE" 3 "SNA" ;
VAL_ 1520 USM_a097_VEH_state 0 "STANDBY" 1 "DRIVE" 2 "SUPPORT" 3 "CHARGE" 4 "FEIM" 5 "CLEAR_FAULT" 6 "FAULT" 7 "WELD" 8 "TEST" 9 "SNA" 10 "DIAG" ;
VAL_ 1520 USM_a111_VEH_status 0 "DISABLED" 1 "ENABLED" 2 "TEMPORARY_FAILURE" 3 "SNA" ;
VAL_ 1520 USM_a112_VEH_status 0 "DISABLED" 1 "ENABLED" 2 "TEMPORARY_FAILURE" 3 "SNA" ;
VAL_ 1520 USM_a120_VEH_systemStatus 0 "UNKNOWN" 1 "RELEASED" 2 "PARKED" 3 "DYNAMIC" 4 "PARKING" 5 "RELEASING" 6 "FAULT" 7 "FAULT_SECURE" 8 "MISMATCH" ;
VAL_ 1520 USM_a086_VEH_status 0 "DISABLED" 1 "ENABLED" 2 "TEMPORARY_FAILURE" 3 "SNA" ;
VAL_ 1520 USM_a089_VEH_status 0 "DISABLED" 1 "ENABLED" 2 "TEMPORARY_FAILURE" 3 "SNA" ;
VAL_ 1520 USM_a091_VEH_state 0 "STANDBY" 1 "DRIVE" 2 "SUPPORT" 3 "CHARGE" 4 "FEIM" 5 "CLEAR_FAULT" 6 "FAULT" 7 "WELD" 8 "TEST" 9 "SNA" 10 "DIAG" ;
VAL_ 1520 USM_a098_VEH_status 0 "DISABLED" 1 "ENABLED" 2 "TEMPORARY_FAILURE" 3 "SNA" ;
VAL_ 1520 USM_a103_VEH_status 0 "DISABLED" 1 "ENABLED" 2 "TEMPORARY_FAILURE" 3 "SNA" ;
VAL_ 1520 USM_a107_VEH_status 0 "DISABLED" 1 "ENABLED" 2 "TEMPORARY_FAILURE" 3 "SNA" ;
VAL_ 1520 USM_a087_VEH_status 0 "DISABLED" 1 "ENABLED" 2 "TEMPORARY_FAILURE" 3 "SNA" ;
VAL_ 1520 USM_a088_VEH_status 0 "DISABLED" 1 "ENABLED" 2 "TEMPORARY_FAILURE" 3 "SNA" ;
VAL_ 1520 USM_a118_VEH_status 0 "DISABLED" 1 "ENABLED" 2 "TEMPORARY_FAILURE" 3 "SNA" ;
VAL_ 1520 USM_a120_PARTY_systemStatus 0 "UNKNOWN" 1 "RELEASED" 2 "PARKED" 3 "DYNAMIC" 4 "PARKING" 5 "RELEASING" 6 "FAULT" 7 "FAULT_SECURE" 8 "MISMATCH" ;
VAL_ 1520 USM_a089_BDY_status 0 "DISABLED" 1 "ENABLED" 2 "TEMPORARY_FAILURE" 3 "SNA" ;
VAL_ 1520 USM_a103_PT_status 0 "DISABLED" 1 "ENABLED" 2 "TEMPORARY_FAILURE" 3 "SNA" ;
VAL_ 1520 USM_a108_VEH_status 0 "DISABLED" 1 "ENABLED" 2 "TEMPORARY_FAILURE" 3 "SNA" ;
VAL_ 1520 USM_a109_VEH_status 0 "DISABLED" 1 "ENABLED" 2 "TEMPORARY_FAILURE" 3 "SNA" ;
VAL_ 1520 USM_a087_PARTY_status 0 "DISABLED" 1 "ENABLED" 2 "TEMPORARY_FAILURE" 3 "SNA" ;
VAL_ 1520 USM_a088_PARTY_status 0 "DISABLED" 1 "ENABLED" 2 "TEMPORARY_FAILURE" 3 "SNA" ;
VAL_ 1520 USM_a089_CH_status 0 "DISABLED" 1 "ENABLED" 2 "TEMPORARY_FAILURE" 3 "SNA" ;
VAL_ 1520 USM_a086_VEH_systemStatus 0 "UNKNOWN" 1 "RELEASED" 2 "PARKED" 3 "DYNAMIC" 4 "PARKING" 5 "RELEASING" 6 "FAULT" 7 "FAULT_SECURE" 8 "MISMATCH" ;
VAL_ 1520 USM_a098_PARTY_status 0 "DISABLED" 1 "ENABLED" 2 "TEMPORARY_FAILURE" 3 "SNA" ;
VAL_ 1520 USM_a108_PARTY_status 0 "DISABLED" 1 "ENABLED" 2 "TEMPORARY_FAILURE" 3 "SNA" ;
VAL_ 1520 USM_a114_VEH_status 0 "DISABLED" 1 "ENABLED" 2 "TEMPORARY_FAILURE" 3 "SNA" ;
VAL_ 1520 USM_a107_PT_status 0 "DISABLED" 1 "ENABLED" 2 "TEMPORARY_FAILURE" 3 "SNA" ;
VAL_ 1520 USM_a104_CH_status 0 "DISABLED" 1 "ENABLED" 2 "TEMPORARY_FAILURE" 3 "SNA" ;
VAL_ 1520 USM_a112_PARTY_status 0 "DISABLED" 1 "ENABLED" 2 "TEMPORARY_FAILURE" 3 "SNA" ;
VAL_ 1520 USM_a118_VEH_systemStatus 0 "UNKNOWN" 1 "RELEASED" 2 "PARKED" 3 "DYNAMIC" 4 "PARKING" 5 "RELEASING" 6 "FAULT" 7 "FAULT_SECURE" 8 "MISMATCH" ;
VAL_ 1520 USM_a120_PARTY_status 0 "DISABLED" 1 "ENABLED" 2 "TEMPORARY_FAILURE" 3 "SNA" ;
VAL_ 1520 USM_a104_PARTY_status 0 "DISABLED" 1 "ENABLED" 2 "TEMPORARY_FAILURE" 3 "SNA" ;
VAL_ 1520 USM_a109_BDY_status 0 "DISABLED" 1 "ENABLED" 2 "TEMPORARY_FAILURE" 3 "SNA" ;
VAL_ 1520 USM_a110_CH_airbagCutoffStatus 0 "RCM_PASSENGER_AIRBAG_ENABLED" 1 "RCM_PASSENGER_AIRBAG_DISABLED" 3 "SNA" ;
VAL_ 1520 USM_a111_PARTY_status 0 "DISABLED" 1 "ENABLED" 2 "TEMPORARY_FAILURE" 3 "SNA" ;
VAL_ 1520 USM_a112_CH_status 0 "DISABLED" 1 "ENABLED" 2 "TEMPORARY_FAILURE" 3 "SNA" ;
VAL_ 1520 USM_a111_CH_status 0 "DISABLED" 1 "ENABLED" 2 "TEMPORARY_FAILURE" 3 "SNA" ;
VAL_ 1520 USM_a120_PT_systemStatus 0 "UNKNOWN" 1 "RELEASED" 2 "PARKED" 3 "DYNAMIC" 4 "PARKING" 5 "RELEASING" 6 "FAULT" 7 "FAULT_SECURE" 8 "MISMATCH" ;
VAL_ 1520 USM_a114_BDY_status 0 "DISABLED" 1 "ENABLED" 2 "TEMPORARY_FAILURE" 3 "SNA" ;
VAL_ 1520 USM_a116_VEH_status 0 "DISABLED" 1 "ENABLED" 2 "TEMPORARY_FAILURE" 3 "SNA" ;
VAL_ 1520 USM_a109_CH_status 0 "DISABLED" 1 "ENABLED" 2 "TEMPORARY_FAILURE" 3 "SNA" ;
VAL_ 1520 USM_a113_VEH_status 0 "DISABLED" 1 "ENABLED" 2 "TEMPORARY_FAILURE" 3 "SNA" ;
VAL_ 1520 USM_a104_VEH_status 0 "DISABLED" 1 "ENABLED" 2 "TEMPORARY_FAILURE" 3 "SNA" ;
VAL_ 1520 USM_a114_CH_status 0 "DISABLED" 1 "ENABLED" 2 "TEMPORARY_FAILURE" 3 "SNA" ;
VAL_ 1520 USM_a117_VEH_status 0 "DISABLED" 1 "ENABLED" 2 "TEMPORARY_FAILURE" 3 "SNA" ;
VAL_ 1520 USM_a104_BDY_status 0 "DISABLED" 1 "ENABLED" 2 "TEMPORARY_FAILURE" 3 "SNA" ;
VAL_ 1529 DAS_init_version 254 "LOCAL_BUILD" 255 "SNA" ;
VAL_ 1529 DAS_mesp_health_diag_flag_0 0 "0" 1 "1" 2 "2" 3 "3" 4 "4" 5 "5" 6 "6" 7 "7" 8 "8" 9 "9" 10 "10" 11 "11" 12 "12" 13 "13" 14 "14" 15 "15" 16 "16" 17 "17" 18 "18" 19 "19" 20 "20" 21 "21" 22 "22" 23 "23" 24 "24" 25 "25" 26 "26" 27 "27" 28 "28" 29 "29" 30 "30" 31 "31" ;
VAL_ 1529 DAS_radarTarg5_dx 255 "SNA" ;
VAL_ 1529 DAS_bootmsg_LPDDR2_temp_status 0 "DISABLED" 1 "ENABLED" 2 "TEMPORARY_FAILURE" 3 "SNA" ;
VAL_ 1529 DAS_calib_reply_ct_type 0 "US_TESLA" 1 "EURO_IEC" 2 "GB" 3 "IEC_CCS" ;
VAL_ 1529 DAS_radarTarg1_dx 255 "SNA" ;
VAL_ 1529 DAS_camGenObj_dx 255 "SNA" ;
VAL_ 1529 DAS_camCipv_dx 255 "SNA" ;
VAL_ 1529 DAS_camPed_dx 255 "SNA" ;
VAL_ 1529 DAS_drivingSide 0 "LEFT" 1 "RIGHT" 2 "UNKNOWN" ;
VAL_ 1529 DAS_mesp_health_main_state 0 "STANDBY" 1 "DRIVE" 2 "SUPPORT" 3 "CHARGE" 4 "FEIM" 5 "CLEAR_FAULT" 6 "FAULT" 7 "WELD" 8 "TEST" 9 "SNA" 10 "DIAG" ;
VAL_ 1529 DAS_mesp_health_sub_state 0 "STANDBY" 1 "DRIVE" 2 "SUPPORT" 3 "CHARGE" 4 "FEIM" 5 "CLEAR_FAULT" 6 "FAULT" 7 "WELD" 8 "TEST" 9 "SNA" 10 "DIAG" ;
VAL_ 1529 DAS_yawRate 4294934528 "SNA" ;
VAL_ 1548 DAS_TR_ObjIndex 0 "Mux0" 1 "Mux1" 2 "Mux2" 3 "Mux3" 4 "Mux4" 5 "Mux5" 6 "Mux6" 7 "Mux7" 8 "Mux8" 9 "Mux9" 10 "Mux10" 11 "Mux11" 12 "Mux12" 13 "Mux13" 14 "Mux14" 15 "Mux15" 16 "Mux16" 17 "Mux17" 18 "Mux18" 19 "Mux19" 20 "Mux20" 21 "Mux21" 22 "Mux22" 23 "Mux23" 24 "Mux24" 25 "Mux25" 26 "Mux26" 27 "Mux27" 28 "Mux28" 29 "Mux29" 30 "Mux30" 31 "Mux31" ;
VAL_ 1548 DAS_TR_Obj00_Class 0 "UNKNOWN" 1 "MOVING_FOUR_WHEEL_VEHICLE" 2 "MOVING_TWO_WHEEL_VEHICLE" 3 "MOVING_PEDESTRIAN" 4 "CONSTRUCTION_ELEMENT" ;
VAL_ 1548 DAS_TR_Obj01_Class 0 "UNKNOWN" 1 "MOVING_FOUR_WHEEL_VEHICLE" 2 "MOVING_TWO_WHEEL_VEHICLE" 3 "MOVING_PEDESTRIAN" 4 "CONSTRUCTION_ELEMENT" ;
VAL_ 1548 DAS_TR_Obj02_Class 0 "UNKNOWN" 1 "MOVING_FOUR_WHEEL_VEHICLE" 2 "MOVING_TWO_WHEEL_VEHICLE" 3 "MOVING_PEDESTRIAN" 4 "CONSTRUCTION_ELEMENT" ;
VAL_ 1548 DAS_TR_Obj03_Class 0 "UNKNOWN" 1 "MOVING_FOUR_WHEEL_VEHICLE" 2 "MOVING_TWO_WHEEL_VEHICLE" 3 "MOVING_PEDESTRIAN" 4 "CONSTRUCTION_ELEMENT" ;
VAL_ 1548 DAS_TR_Obj04_Class 0 "UNKNOWN" 1 "MOVING_FOUR_WHEEL_VEHICLE" 2 "MOVING_TWO_WHEEL_VEHICLE" 3 "MOVING_PEDESTRIAN" 4 "CONSTRUCTION_ELEMENT" ;
VAL_ 1548 DAS_TR_Obj05_Class 0 "UNKNOWN" 1 "MOVING_FOUR_WHEEL_VEHICLE" 2 "MOVING_TWO_WHEEL_VEHICLE" 3 "MOVING_PEDESTRIAN" 4 "CONSTRUCTION_ELEMENT" ;
VAL_ 1548 DAS_TR_Obj06_Class 0 "UNKNOWN" 1 "MOVING_FOUR_WHEEL_VEHICLE" 2 "MOVING_TWO_WHEEL_VEHICLE" 3 "MOVING_PEDESTRIAN" 4 "CONSTRUCTION_ELEMENT" ;
VAL_ 1548 DAS_TR_Obj07_Class 0 "UNKNOWN" 1 "MOVING_FOUR_WHEEL_VEHICLE" 2 "MOVING_TWO_WHEEL_VEHICLE" 3 "MOVING_PEDESTRIAN" 4 "CONSTRUCTION_ELEMENT" ;
VAL_ 1548 DAS_TR_Obj08_Class 0 "UNKNOWN" 1 "MOVING_FOUR_WHEEL_VEHICLE" 2 "MOVING_TWO_WHEEL_VEHICLE" 3 "MOVING_PEDESTRIAN" 4 "CONSTRUCTION_ELEMENT" ;
VAL_ 1548 DAS_TR_Obj09_Class 0 "UNKNOWN" 1 "MOVING_FOUR_WHEEL_VEHICLE" 2 "MOVING_TWO_WHEEL_VEHICLE" 3 "MOVING_PEDESTRIAN" 4 "CONSTRUCTION_ELEMENT" ;
VAL_ 1548 DAS_TR_Obj10_Class 0 "UNKNOWN" 1 "MOVING_FOUR_WHEEL_VEHICLE" 2 "MOVING_TWO_WHEEL_VEHICLE" 3 "MOVING_PEDESTRIAN" 4 "CONSTRUCTION_ELEMENT" ;
VAL_ 1548 DAS_TR_Obj11_Class 0 "UNKNOWN" 1 "MOVING_FOUR_WHEEL_VEHICLE" 2 "MOVING_TWO_WHEEL_VEHICLE" 3 "MOVING_PEDESTRIAN" 4 "CONSTRUCTION_ELEMENT" ;
VAL_ 1548 DAS_TR_Obj12_Class 0 "UNKNOWN" 1 "MOVING_FOUR_WHEEL_VEHICLE" 2 "MOVING_TWO_WHEEL_VEHICLE" 3 "MOVING_PEDESTRIAN" 4 "CONSTRUCTION_ELEMENT" ;
VAL_ 1548 DAS_TR_Obj13_Class 0 "UNKNOWN" 1 "MOVING_FOUR_WHEEL_VEHICLE" 2 "MOVING_TWO_WHEEL_VEHICLE" 3 "MOVING_PEDESTRIAN" 4 "CONSTRUCTION_ELEMENT" ;
VAL_ 1548 DAS_TR_Obj14_Class 0 "UNKNOWN" 1 "MOVING_FOUR_WHEEL_VEHICLE" 2 "MOVING_TWO_WHEEL_VEHICLE" 3 "MOVING_PEDESTRIAN" 4 "CONSTRUCTION_ELEMENT" ;
VAL_ 1548 DAS_TR_Obj15_Class 0 "UNKNOWN" 1 "MOVING_FOUR_WHEEL_VEHICLE" 2 "MOVING_TWO_WHEEL_VEHICLE" 3 "MOVING_PEDESTRIAN" 4 "CONSTRUCTION_ELEMENT" ;
VAL_ 1548 DAS_TR_Obj16_Class 0 "UNKNOWN" 1 "MOVING_FOUR_WHEEL_VEHICLE" 2 "MOVING_TWO_WHEEL_VEHICLE" 3 "MOVING_PEDESTRIAN" 4 "CONSTRUCTION_ELEMENT" ;
VAL_ 1548 DAS_TR_Obj17_Class 0 "UNKNOWN" 1 "MOVING_FOUR_WHEEL_VEHICLE" 2 "MOVING_TWO_WHEEL_VEHICLE" 3 "MOVING_PEDESTRIAN" 4 "CONSTRUCTION_ELEMENT" ;
VAL_ 1548 DAS_TR_Obj18_Class 0 "UNKNOWN" 1 "MOVING_FOUR_WHEEL_VEHICLE" 2 "MOVING_TWO_WHEEL_VEHICLE" 3 "MOVING_PEDESTRIAN" 4 "CONSTRUCTION_ELEMENT" ;
VAL_ 1548 DAS_TR_Obj19_Class 0 "UNKNOWN" 1 "MOVING_FOUR_WHEEL_VEHICLE" 2 "MOVING_TWO_WHEEL_VEHICLE" 3 "MOVING_PEDESTRIAN" 4 "CONSTRUCTION_ELEMENT" ;
VAL_ 1548 DAS_TR_Obj20_Class 0 "UNKNOWN" 1 "MOVING_FOUR_WHEEL_VEHICLE" 2 "MOVING_TWO_WHEEL_VEHICLE" 3 "MOVING_PEDESTRIAN" 4 "CONSTRUCTION_ELEMENT" ;
VAL_ 1548 DAS_TR_Obj21_Class 0 "UNKNOWN" 1 "MOVING_FOUR_WHEEL_VEHICLE" 2 "MOVING_TWO_WHEEL_VEHICLE" 3 "MOVING_PEDESTRIAN" 4 "CONSTRUCTION_ELEMENT" ;
VAL_ 1548 DAS_TR_Obj22_Class 0 "UNKNOWN" 1 "MOVING_FOUR_WHEEL_VEHICLE" 2 "MOVING_TWO_WHEEL_VEHICLE" 3 "MOVING_PEDESTRIAN" 4 "CONSTRUCTION_ELEMENT" ;
VAL_ 1548 DAS_TR_Obj23_Class 0 "UNKNOWN" 1 "MOVING_FOUR_WHEEL_VEHICLE" 2 "MOVING_TWO_WHEEL_VEHICLE" 3 "MOVING_PEDESTRIAN" 4 "CONSTRUCTION_ELEMENT" ;
VAL_ 1548 DAS_TR_Obj24_Class 0 "UNKNOWN" 1 "MOVING_FOUR_WHEEL_VEHICLE" 2 "MOVING_TWO_WHEEL_VEHICLE" 3 "MOVING_PEDESTRIAN" 4 "CONSTRUCTION_ELEMENT" ;
VAL_ 1548 DAS_TR_Obj25_Class 0 "UNKNOWN" 1 "MOVING_FOUR_WHEEL_VEHICLE" 2 "MOVING_TWO_WHEEL_VEHICLE" 3 "MOVING_PEDESTRIAN" 4 "CONSTRUCTION_ELEMENT" ;
VAL_ 1548 DAS_TR_Obj26_Class 0 "UNKNOWN" 1 "MOVING_FOUR_WHEEL_VEHICLE" 2 "MOVING_TWO_WHEEL_VEHICLE" 3 "MOVING_PEDESTRIAN" 4 "CONSTRUCTION_ELEMENT" ;
VAL_ 1548 DAS_TR_Obj27_Class 0 "UNKNOWN" 1 "MOVING_FOUR_WHEEL_VEHICLE" 2 "MOVING_TWO_WHEEL_VEHICLE" 3 "MOVING_PEDESTRIAN" 4 "CONSTRUCTION_ELEMENT" ;
VAL_ 1548 DAS_TR_Obj28_Class 0 "UNKNOWN" 1 "MOVING_FOUR_WHEEL_VEHICLE" 2 "MOVING_TWO_WHEEL_VEHICLE" 3 "MOVING_PEDESTRIAN" 4 "CONSTRUCTION_ELEMENT" ;
VAL_ 1548 DAS_TR_Obj29_Class 0 "UNKNOWN" 1 "MOVING_FOUR_WHEEL_VEHICLE" 2 "MOVING_TWO_WHEEL_VEHICLE" 3 "MOVING_PEDESTRIAN" 4 "CONSTRUCTION_ELEMENT" ;
VAL_ 1548 DAS_TR_Obj30_Class 0 "UNKNOWN" 1 "MOVING_FOUR_WHEEL_VEHICLE" 2 "MOVING_TWO_WHEEL_VEHICLE" 3 "MOVING_PEDESTRIAN" 4 "CONSTRUCTION_ELEMENT" ;
VAL_ 1548 DAS_TR_Obj31_Class 0 "UNKNOWN" 1 "MOVING_FOUR_WHEEL_VEHICLE" 2 "MOVING_TWO_WHEEL_VEHICLE" 3 "MOVING_PEDESTRIAN" 4 "CONSTRUCTION_ELEMENT" ;
VAL_ 1548 DAS_TR_Obj00_MovingState 0 "INDETERMINATE" 1 "MOVING" 2 "STOPPED" 3 "STANDING" ;
VAL_ 1548 DAS_TR_Obj01_MovingState 0 "INDETERMINATE" 1 "MOVING" 2 "STOPPED" 3 "STANDING" ;
VAL_ 1548 DAS_TR_Obj02_MovingState 0 "INDETERMINATE" 1 "MOVING" 2 "STOPPED" 3 "STANDING" ;
VAL_ 1548 DAS_TR_Obj03_MovingState 0 "INDETERMINATE" 1 "MOVING" 2 "STOPPED" 3 "STANDING" ;
VAL_ 1548 DAS_TR_Obj04_MovingState 0 "INDETERMINATE" 1 "MOVING" 2 "STOPPED" 3 "STANDING" ;
VAL_ 1548 DAS_TR_Obj05_MovingState 0 "INDETERMINATE" 1 "MOVING" 2 "STOPPED" 3 "STANDING" ;
VAL_ 1548 DAS_TR_Obj06_MovingState 0 "INDETERMINATE" 1 "MOVING" 2 "STOPPED" 3 "STANDING" ;
VAL_ 1548 DAS_TR_Obj07_MovingState 0 "INDETERMINATE" 1 "MOVING" 2 "STOPPED" 3 "STANDING" ;
VAL_ 1548 DAS_TR_Obj08_MovingState 0 "INDETERMINATE" 1 "MOVING" 2 "STOPPED" 3 "STANDING" ;
VAL_ 1548 DAS_TR_Obj09_MovingState 0 "INDETERMINATE" 1 "MOVING" 2 "STOPPED" 3 "STANDING" ;
VAL_ 1548 DAS_TR_Obj10_MovingState 0 "INDETERMINATE" 1 "MOVING" 2 "STOPPED" 3 "STANDING" ;
VAL_ 1548 DAS_TR_Obj11_MovingState 0 "INDETERMINATE" 1 "MOVING" 2 "STOPPED" 3 "STANDING" ;
VAL_ 1548 DAS_TR_Obj12_MovingState 0 "INDETERMINATE" 1 "MOVING" 2 "STOPPED" 3 "STANDING" ;
VAL_ 1548 DAS_TR_Obj13_MovingState 0 "INDETERMINATE" 1 "MOVING" 2 "STOPPED" 3 "STANDING" ;
VAL_ 1548 DAS_TR_Obj14_MovingState 0 "INDETERMINATE" 1 "MOVING" 2 "STOPPED" 3 "STANDING" ;
VAL_ 1548 DAS_TR_Obj15_MovingState 0 "INDETERMINATE" 1 "MOVING" 2 "STOPPED" 3 "STANDING" ;
VAL_ 1548 DAS_TR_Obj16_MovingState 0 "INDETERMINATE" 1 "MOVING" 2 "STOPPED" 3 "STANDING" ;
VAL_ 1548 DAS_TR_Obj17_MovingState 0 "INDETERMINATE" 1 "MOVING" 2 "STOPPED" 3 "STANDING" ;
VAL_ 1548 DAS_TR_Obj18_MovingState 0 "INDETERMINATE" 1 "MOVING" 2 "STOPPED" 3 "STANDING" ;
VAL_ 1548 DAS_TR_Obj19_MovingState 0 "INDETERMINATE" 1 "MOVING" 2 "STOPPED" 3 "STANDING" ;
VAL_ 1548 DAS_TR_Obj20_MovingState 0 "INDETERMINATE" 1 "MOVING" 2 "STOPPED" 3 "STANDING" ;
VAL_ 1548 DAS_TR_Obj21_MovingState 0 "INDETERMINATE" 1 "MOVING" 2 "STOPPED" 3 "STANDING" ;
VAL_ 1548 DAS_TR_Obj22_MovingState 0 "INDETERMINATE" 1 "MOVING" 2 "STOPPED" 3 "STANDING" ;
VAL_ 1548 DAS_TR_Obj23_MovingState 0 "INDETERMINATE" 1 "MOVING" 2 "STOPPED" 3 "STANDING" ;
VAL_ 1548 DAS_TR_Obj24_MovingState 0 "INDETERMINATE" 1 "MOVING" 2 "STOPPED" 3 "STANDING" ;
VAL_ 1548 DAS_TR_Obj25_MovingState 0 "INDETERMINATE" 1 "MOVING" 2 "STOPPED" 3 "STANDING" ;
VAL_ 1548 DAS_TR_Obj26_MovingState 0 "INDETERMINATE" 1 "MOVING" 2 "STOPPED" 3 "STANDING" ;
VAL_ 1548 DAS_TR_Obj27_MovingState 0 "INDETERMINATE" 1 "MOVING" 2 "STOPPED" 3 "STANDING" ;
VAL_ 1548 DAS_TR_Obj28_MovingState 0 "INDETERMINATE" 1 "MOVING" 2 "STOPPED" 3 "STANDING" ;
VAL_ 1548 DAS_TR_Obj29_MovingState 0 "INDETERMINATE" 1 "MOVING" 2 "STOPPED" 3 "STANDING" ;
VAL_ 1548 DAS_TR_Obj30_MovingState 0 "INDETERMINATE" 1 "MOVING" 2 "STOPPED" 3 "STANDING" ;
VAL_ 1548 DAS_TR_Obj31_MovingState 0 "INDETERMINATE" 1 "MOVING" 2 "STOPPED" 3 "STANDING" ;
VAL_ 1655 VC_lvbmsStatusHighIndex 0 "PACK_VITALS_1" 1 "CELL_VITALS_1" 2 "CELL_VITALS_2" 3 "TARGETS" 4 "STATE_AND_COMMANDS" 5 "PCS_INTERFACE" 6 "INVALID" ;
VAL_ 1655 VC_LVBMS_packCurrent 4194303 "SNA" ;
VAL_ 1655 VC_LVBMS_voltageTarget 32767 "SNA" ;
VAL_ 1655 VC_LVBMS_ECPAState 0 "OPEN" 1 "CLOSED" 2 "INVALID" 3 "SNA" ;
VAL_ 1655 VC_LVBMS_sumCellVoltage 65534 "INVALID" 65535 "SNA" ;
VAL_ 1655 VC_LVBMS_MOSState 0 "OPEN" 1 "CLOSED" 2 "INVALID" 3 "SNA" ;
VAL_ 1655 VC_LVBMS_VehicleState 0 "DRIVE" 1 "ACCESSORY" 2 "CONDITIONING" 3 "OFF" ;
VAL_ 1655 VC_LVBMS_LINWakeDisabled 0 "ENABLED" 1 "DISABLED" ;
VAL_ 1655 VC_LVBMS_chargeType 0 "UNDEFINED" 1 "CONSTANT_CURRENT" 2 "CONSTANT_VOLTAGE" 3 "COMPLETE" 4 "SNA" ;
VAL_ 1655 VC_LVBMS_currentTarget 32767 "SNA" ;
VAL_ 1655 VC_LVBMS_packVoltage 65535 "SNA" ;
VAL_ 1655 VC_LVBMS_maxAllowedChargeCurrent 8191 "SNA" ;
VAL_ 1655 VC_LVBMS_packTemperature 511 "SNA" ;
VAL_ 1655 VC_LVBMS_MOSTemperature 4095 "SNA" ;
VAL_ 1655 VC_LVBMS_maxAllowedDischargeCurrent 8191 "SNA" ;
